VERSION ""

NS_ :

BS_:

BU_: Skylark_EV

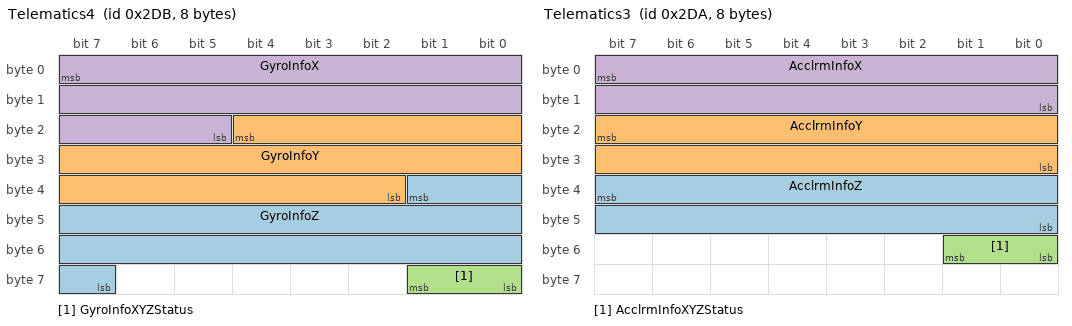
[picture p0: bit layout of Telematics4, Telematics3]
BO_ 731 Telematics4: 8 Skylark_EV
 SG_ GyroInfoZ : 33|19@0- (0.01,0) [-2000|2000] "deg/s" Vector__XXX
 SG_ GyroInfoY : 20|19@0- (0.01,0) [-2000|2000] "deg/s" Vector__XXX
 SG_ GyroInfoXYZStatus : 57|2@0+ (1,0) [0|3] "" Vector__XXX
 SG_ GyroInfoX : 7|19@0- (0.01,0) [-2000|2000] "deg/s" Vector__XXX

BO_ 730 Telematics3: 8 Skylark_EV
 SG_ AcclrmInfoZ : 39|16@0- (0.01,0) [-300|300] "m/s^2" Vector__XXX
 SG_ AcclrmInfoY : 23|16@0- (0.01,0) [-300|300] "m/s^2" Vector__XXX
 SG_ AcclrmInfoXYZStatus : 49|2@0+ (1,0) [0|3] "" Vector__XXX
 SG_ AcclrmInfoX : 7|16@0- (0.01,0) [-300|300] "m/s^2" Vector__XXX

BO_ 699 IPC11: 8 Vector__XXX
 SG_ IcHuTripBInfofull : 22|17@0+ (0.1,0) [0|9999.9] "Km"  Skylark_EV
 SG_ IcHuTripAInfofull : 7|17@0+ (0.1,0) [0|9999.9] "Km"  Skylark_EV

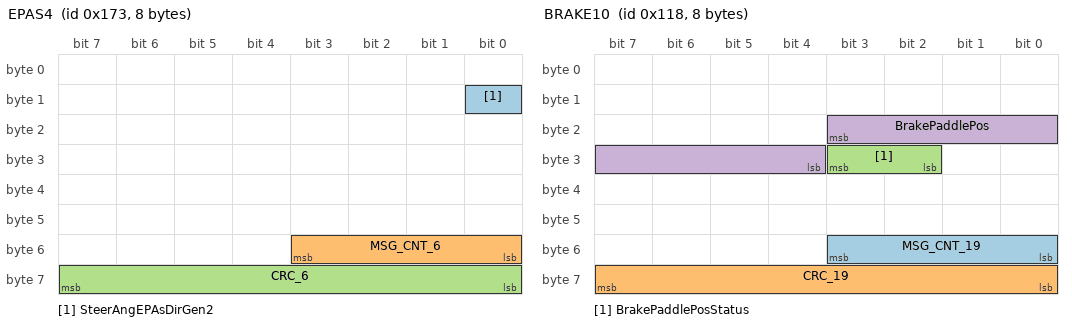
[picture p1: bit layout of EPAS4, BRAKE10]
BO_ 371 EPAS4: 8 Vector__XXX
 SG_ SteerAngEPAsDirGen2 : 8|1@0+ (1,0) [0|1] ""  Skylark_EV
 SG_ MSG_CNT_6 : 51|4@0+ (1,0) [0|15] ""  Skylark_EV
 SG_ CRC_6 : 63|8@0+ (1,0) [0|255] ""  Skylark_EV

BO_ 280 BRAKE10: 8 Vector__XXX
 SG_ MSG_CNT_19 : 51|4@0+ (1,0) [0|15] ""  Skylark_EV
 SG_ CRC_19 : 63|8@0+ (1,0) [0|255] ""  Skylark_EV
 SG_ BrakePaddlePosStatus : 27|2@0+ (1,0) [0|3] ""  Skylark_EV
 SG_ BrakePaddlePos : 19|8@0+ (0.5,0) [0|100] "%"  Skylark_EV

BO_ 703 IPC_RC1: 8 Vector__XXX
 SG_ OATICSigNewStatus : 15|2@0+ (1,0) [0|3] ""  Skylark_EV
 SG_ OATICSigNew : 7|8@0+ (0.5,-40) [-40|85] "degC"  Skylark_EV

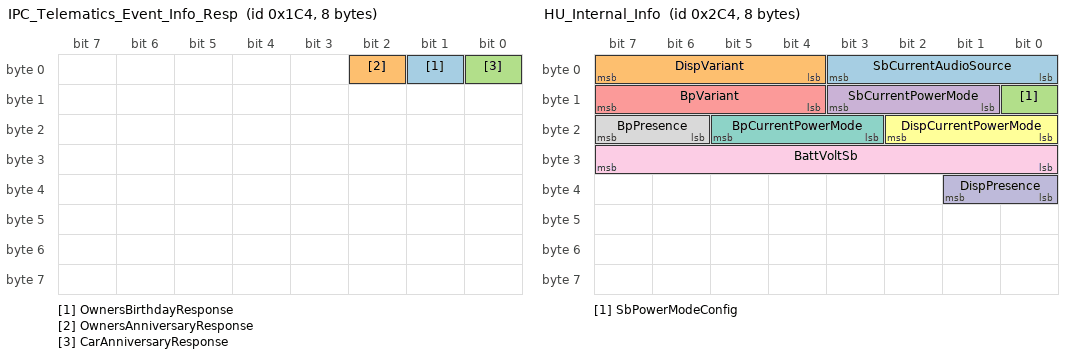
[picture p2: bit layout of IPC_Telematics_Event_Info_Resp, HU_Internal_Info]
BO_ 452 IPC_Telematics_Event_Info_Resp: 8 Vector__XXX
 SG_ OwnersBirthdayResponse : 1|1@0+ (1,0) [0|1] ""  Skylark_EV
 SG_ OwnersAnniversaryResponse : 2|1@0+ (1,0) [0|1] ""  Skylark_EV
 SG_ CarAnniversaryResponse : 0|1@0+ (1,0) [0|1] ""  Skylark_EV

BO_ 1548 VICM_DiagResponse_UUDT: 8 Vector__XXX
 SG_ VICM_DiagResponse_UUDT : 7|64@0+ (1,0) [0|0] ""  Skylark_EV

BO_ 1804 VICM_DiagResponse_USDT: 8 Vector__XXX
 SG_ VICM_DiagResponse_USDT : 7|64@0+ (1,0) [0|0] ""  Skylark_EV

BO_ 1796 VICM_DiagRequest: 8 Skylark_EV
 SG_ VICM_DiagRequest : 7|64@0+ (1,0) [0|0] "" Vector__XXX

BO_ 1771 VCU_DiagResponse_UUDT: 8 Vector__XXX
 SG_ VCU_DiagResponse_UUDT : 7|64@0+ (1,0) [0|0] ""  Skylark_EV

BO_ 2027 VCU_DiagResponse_USDT: 8 Vector__XXX
 SG_ VCU_DiagResponse_USDT : 7|64@0+ (1,0) [0|0] ""  Skylark_EV

BO_ 1763 VCU_DiagRequest_UUDT: 8 Skylark_EV
 SG_ VCU_DiagRequest_UUDT : 7|64@0+ (1,0) [0|0] "" Vector__XXX

BO_ 2019 VCU_DiagRequest_USDT: 8 Skylark_EV
 SG_ VCU_DiagRequest_USDT : 7|64@0+ (1,0) [0|0] "" Vector__XXX

BO_ 1849 WPC_DiagResponse_USDT: 8 Vector__XXX
 SG_ WPC_DiagResponse_USDT : 7|64@0+ (1,0) [0|0] ""  Skylark_EV

BO_ 1841 WPC_DiagRequest: 8 Skylark_EV
 SG_ WPC_DiagRequest : 7|64@0+ (1,0) [0|0] "" Vector__XXX

BO_ 1630 TPMS_DiagResponse_UUDT: 8 Vector__XXX
 SG_ TPMS_DiagResponse_UUDT : 7|64@0+ (1,0) [0|0] ""  Skylark_EV

BO_ 1886 TPMS_DiagResponse_USDT: 8 Vector__XXX
 SG_ TPMS_DiagResponse_USDT : 7|64@0+ (1,0) [0|0] ""  Skylark_EV

BO_ 1878 TPMS_DiagRequest: 8 Skylark_EV
 SG_ TPMS_DiagRequest : 7|64@0+ (1,0) [0|0] "" Vector__XXX

BO_ 1546 SRS_DiagResponse_UUDT: 8 Vector__XXX
 SG_ SRS_DiagResponse_UUDT : 7|64@0+ (1,0) [0|0] ""  Skylark_EV

BO_ 1802 SRS_DiagResponse_USDT: 8 Vector__XXX
 SG_ SRS_DiagResponse_USDT : 7|64@0+ (1,0) [0|0] ""  Skylark_EV

BO_ 1794 SRS_DiagRequest: 8 Skylark_EV
 SG_ SRS_DiagRequest : 7|64@0+ (1,0) [0|0] "" Vector__XXX

BO_ 1610 SRR_DiagResponse_UUDT: 8 Vector__XXX
 SG_ SRR_DiagResponse_UUDT : 7|64@0+ (1,0) [0|0] ""  Skylark_EV

BO_ 1866 SRR_DiagResponse_USDT: 8 Vector__XXX
 SG_ SRR_DiagResponse_USDT : 7|64@0+ (1,0) [0|0] ""  Skylark_EV

BO_ 1858 SRR_DiagRequest: 8 Skylark_EV
 SG_ SRR_DiagRequest : 7|64@0+ (1,0) [0|0] "" Vector__XXX

BO_ 1560 PEPS_DiagResponse_UUDT: 8 Vector__XXX
 SG_ PEPS_DiagResponse_UUDT : 7|64@0+ (1,0) [0|0] ""  Skylark_EV

BO_ 1816 PEPS_DiagResponse_USDT: 8 Vector__XXX
 SG_ PEPS_DiagResponse_USDT : 7|64@0+ (1,0) [0|0] ""  Skylark_EV

BO_ 1808 PEPS_DiagRequest_USDT: 8 Skylark_EV
 SG_ PEPS_DiagRequest_USDT : 7|64@0+ (1,0) [0|0] "" Vector__XXX

BO_ 1564 PDC_DiagResponse_UUDT: 8 Vector__XXX
 SG_ PDC_DiagResponse_UUDT : 7|64@0+ (1,0) [0|0] ""  Skylark_EV

BO_ 1820 PDC_DiagResponse_USDT: 8 Vector__XXX
 SG_ PDC_DiagResponse_USDT : 7|64@0+ (1,0) [0|0] ""  Skylark_EV

BO_ 1812 PDC_DiagRequest: 8 Skylark_EV
 SG_ PDC_DiagRequest : 7|64@0+ (1,0) [0|0] "" Vector__XXX

BO_ 1608 FR_DiagResponse_UUDT: 8 Vector__XXX
 SG_ FR_DiagResponse_UUDT : 7|64@0+ (1,0) [0|0] ""  Skylark_EV

BO_ 1864 FR_DiagResponse_USDT: 8 Vector__XXX
 SG_ FR_DiagResponse_USDT : 7|64@0+ (1,0) [0|0] ""  Skylark_EV

BO_ 1856 FR_DiagRequest: 8 Skylark_EV
 SG_ FR_DiagRequest : 7|64@0+ (1,0) [0|0] "" Vector__XXX

BO_ 1609 FCM_DiagResponse_UUDT: 8 Vector__XXX
 SG_ FCM_DiagResponse_UUDT : 7|64@0+ (1,0) [0|0] ""  Skylark_EV

BO_ 1865 FCM_DiagResponse_USDT: 8 Vector__XXX
 SG_ FCM_DiagResponse_USDT : 7|64@0+ (1,0) [0|0] ""  Skylark_EV

BO_ 1857 FCM_DiagRequest: 8 Skylark_EV
 SG_ FCM_DiagRequest : 7|64@0+ (1,0) [0|0] "" Vector__XXX

BO_ 1624 ESP_DiagResponse_UUDT: 8 Vector__XXX
 SG_ ESP_DiagResponse_UUDT : 7|64@0+ (1,0) [0|0] ""  Skylark_EV

BO_ 1880 ESP_DiagResponse_USDT: 8 Vector__XXX
 SG_ ESP_DiagResponse_USDT : 7|64@0+ (1,0) [0|0] ""  Skylark_EV

BO_ 1872 ESP_DiagRequest: 8 Skylark_EV
 SG_ ESP_DiagRequest : 7|64@0+ (1,0) [0|0] "" Vector__XXX

BO_ 1884 ESCL_DiagResponse_USDT: 8 Vector__XXX
 SG_ ESCL_DiagResponse_USDT : 7|64@0+ (1,0) [0|0] ""  Skylark_EV

BO_ 1876 ESCL_DiagRequest: 8 Skylark_EV
 SG_ ESCL_DiagRequest : 7|64@0+ (1,0) [0|0] "" Vector__XXX

BO_ 1626 EPAS_DiagResponse_UUDT: 8 Vector__XXX
 SG_ EPAS_DiagResponse_UUDT : 7|64@0+ (1,0) [0|0] ""  Skylark_EV

BO_ 1882 EPAS_DiagResponse_USDT: 8 Vector__XXX
 SG_ EPAS_DiagResponse_USDT : 7|64@0+ (1,0) [0|0] ""  Skylark_EV

BO_ 1874 EPAS_DiagRequest: 8 Skylark_EV
 SG_ EPAS_DiagRequest : 7|64@0+ (1,0) [0|0] "" Vector__XXX

BO_ 1549 CCM_DiagResponse_UUDT: 8 Vector__XXX
 SG_ CCM_DiagResponse_UUDT : 7|64@0+ (1,0) [0|0] ""  Skylark_EV

BO_ 1805 CCM_DiagResponse_USDT: 8 Vector__XXX
 SG_ CCM_DiagResponse_USDT : 7|64@0+ (1,0) [0|0] ""  Skylark_EV

BO_ 1797 CCM_DiagRequest: 8 Skylark_EV
 SG_ CCM_DiagRequest : 7|64@0+ (1,0) [0|0] "" Vector__XXX

BO_ 1545 BCM_DiagResponse_UUDT: 8 Vector__XXX
 SG_ BCM_DiagResponse_UUDT : 7|64@0+ (1,0) [0|0] ""  Skylark_EV

BO_ 1801 BCM_DiagResponse_USDT: 8 Vector__XXX
 SG_ BCM_DiagResponse_USDT : 7|64@0+ (1,0) [0|0] ""  Skylark_EV

BO_ 1793 BCM_DiagRequest: 8 Skylark_EV
 SG_ BCM_DiagRequest : 7|64@0+ (1,0) [0|0] "" Vector__XXX

BO_ 708 HU_Internal_Info: 8 Skylark_EV
 SG_ SbCurrentAudioSource : 3|4@0+ (1,0) [0|15] "" Vector__XXX
 SG_ DispVariant : 7|4@0+ (1,0) [0|15] "" Vector__XXX
 SG_ SbPowerModeConfig : 8|1@0+ (1,0) [0|1] "" Vector__XXX
 SG_ SbCurrentPowerMode : 11|3@0+ (1,0) [0|7] "" Vector__XXX
 SG_ BpVariant : 15|4@0+ (1,0) [0|15] "" Vector__XXX
 SG_ DispCurrentPowerMode : 18|3@0+ (1,0) [0|7] "" Vector__XXX
 SG_ BpCurrentPowerMode : 21|3@0+ (1,0) [0|7] "" Vector__XXX
 SG_ BpPresence : 23|2@0+ (1,0) [0|3] "" Vector__XXX
 SG_ BattVoltSb : 31|8@0+ (0.1,0) [0|25.4] "V" Vector__XXX
 SG_ DispPresence : 33|2@0+ (1,0) [0|3] "" Vector__XXX

BO_ 1109 AVAS_Event2: 8 Vector__XXX
 SG_ AvasOnOffSettingState : 7|1@0+ (1,0) [0|1] ""  Skylark_EV
 SG_ AvasOnOffSettingPresence : 6|2@0+ (1,0) [0|3] ""  Skylark_EV

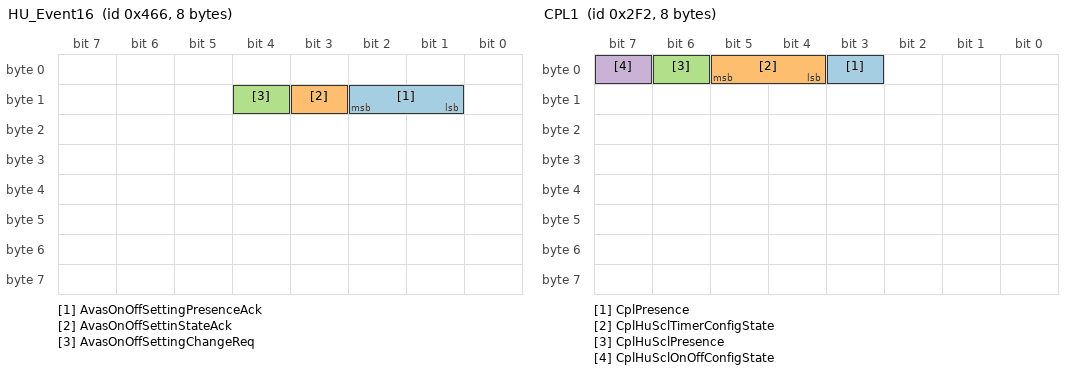
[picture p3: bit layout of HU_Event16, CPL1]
BO_ 1126 HU_Event16: 8 Skylark_EV
 SG_ AvasOnOffSettingPresenceAck : 10|2@0+ (1,0) [0|3] "" Vector__XXX
 SG_ AvasOnOffSettinStateAck : 11|1@0+ (1,0) [0|1] "" Vector__XXX
 SG_ AvasOnOffSettingChangeReq : 12|1@0+ (1,0) [0|1] "" Vector__XXX

BO_ 945 BCM5: 8 Vector__XXX
 SG_ VehicleKeyType : 7|5@0+ (1,0) [0|31] ""  Skylark_EV

BO_ 535 CPL_Event1: 8 Vector__XXX
 SG_ CplHuSclSettingUpdateAck : 1|2@0+ (1,0) [0|3] ""  Skylark_EV

BO_ 754 CPL1: 8 Vector__XXX
 SG_ CplPresence : 3|1@0+ (1,0) [0|1] ""  Skylark_EV
 SG_ CplHuSclTimerConfigState : 5|2@0+ (1,0) [0|3] ""  Skylark_EV
 SG_ CplHuSclPresence : 6|1@0+ (1,0) [0|1] ""  Skylark_EV
 SG_ CplHuSclOnOffConfigState : 7|1@0+ (1,0) [0|1] ""  Skylark_EV

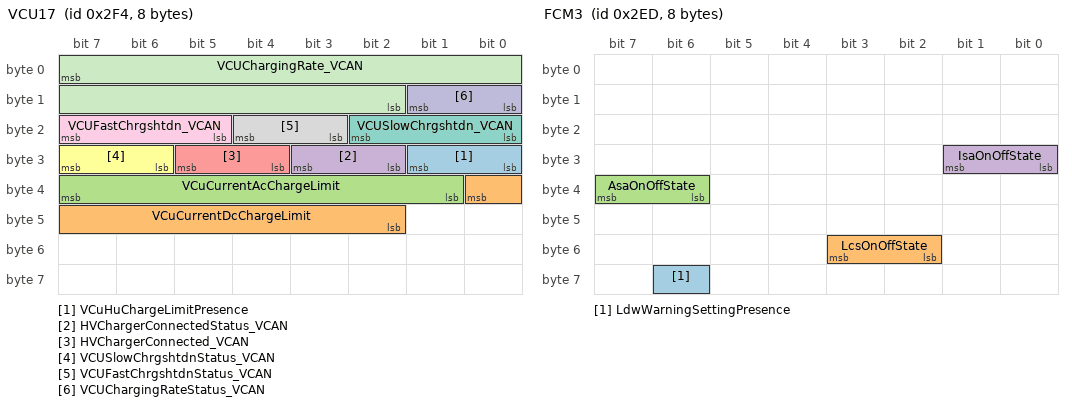
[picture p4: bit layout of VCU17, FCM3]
BO_ 756 VCU17: 8 Vector__XXX
 SG_ VCuHuChargeLimitPresence : 25|2@0+ (1,0) [0|3] ""  Skylark_EV
 SG_ VCuCurrentDcChargeLimit : 32|7@0+ (1,0) [0|100] ""  Skylark_EV
 SG_ VCuCurrentAcChargeLimit : 39|7@0+ (1,0) [0|100] ""  Skylark_EV
 SG_ HVChargerConnectedStatus_VCAN : 27|2@0+ (1,0) [0|3] ""  Skylark_EV
 SG_ HVChargerConnected_VCAN : 29|2@0+ (1,0) [0|3] ""  Skylark_EV
 SG_ VCUSlowChrgshtdnStatus_VCAN : 31|2@0+ (1,0) [0|3] ""  Skylark_EV
 SG_ VCUSlowChrgshtdn_VCAN : 18|3@0+ (1,0) [0|7] ""  Skylark_EV
 SG_ VCUFastChrgshtdnStatus_VCAN : 20|2@0+ (1,0) [0|3] ""  Skylark_EV
 SG_ VCUFastChrgshtdn_VCAN : 23|3@0+ (1,0) [0|7] ""  Skylark_EV
 SG_ VCUChargingRateStatus_VCAN : 9|2@0+ (1,0) [0|3] ""  Skylark_EV
 SG_ VCUChargingRate_VCAN : 7|14@0+ (0.01,0) [0|163.84] "Kwh"  Skylark_EV

BO_ 753 HUD1: 8 Vector__XXX
 SG_ HudPresence : 7|2@0+ (1,0) [0|3] ""  Skylark_EV
 SG_ HudFeaturePresence : 5|1@0+ (1,0) [0|1] ""  Skylark_EV

BO_ 382 VCU15: 8 Vector__XXX
 SG_ VCUGSAPositionDisplay : 23|16@0+ (1,0) [0|65535] ""  Skylark_EV

BO_ 529 VCU_Event1: 8 Vector__XXX
 SG_ VCuHuChargeLimitValueAck : 13|2@0+ (1,0) [0|3] ""  Skylark_EV
 SG_ DischargingSOCLimitAck : 15|2@0+ (1,0) [0|3] ""  Skylark_EV

BO_ 528 HU_Event4: 8 Skylark_EV
 SG_ DischargeSOClimitcmd : 60|2@0+ (1,0) [0|3] "" Vector__XXX
 SG_ DischargeSOClimit : 51|7@0+ (1,0) [30|100] "%" Vector__XXX
 SG_ AVAsFeaturePreviewReq : 47|6@0+ (1,0) [0|63] "" Vector__XXX
 SG_ SoundSigSettingStateAck : 25|6@0+ (1,0) [0|63] "" Vector__XXX
 SG_ SoundSigSettingPresenceAck : 31|6@0+ (1,0) [0|63] "" Vector__XXX
 SG_ ChargingSettingChangeReq : 12|1@0+ (1,0) [0|1] "" Vector__XXX
 SG_ V2XSoundSettingStateAck : 33|1@0+ (1,0) [0|1] "" Vector__XXX
 SG_ V2XSettingChangeReq : 32|1@0+ (1,0) [0|1] "" Vector__XXX
 SG_ V2XEventPresenceAck : 35|2@0+ (1,0) [0|3] "" Vector__XXX
 SG_ SndSyncDriveModeChangeReq : 40|1@0+ (1,0) [0|1] "" Vector__XXX
 SG_ SoundSigSettingChangeReq : 21|6@0+ (1,0) [0|63] "" Vector__XXX
 SG_ CrankSettingChangeReq : 8|1@0+ (1,0) [0|1] "" Vector__XXX
 SG_ LockUnlockSettingChangeReq : 0|1@0+ (1,0) [0|1] "" Vector__XXX
 SG_ ActiveExtSettingChangeReq : 4|1@0+ (1,0) [0|1] "" Vector__XXX
 SG_ HuAVAsReqType : 55|4@0+ (1,0) [0|15] "" Vector__XXX
 SG_ SndSyncDriveModePresenceAck : 23|2@0+ (1,0) [0|3] "" Vector__XXX
 SG_ SndSyncDriveModeSettingStateAck : 41|1@0+ (1,0) [0|1] "" Vector__XXX
 SG_ CrankSoundSettingStateAck : 9|1@0+ (1,0) [0|1] "" Vector__XXX
 SG_ CrankEventPresenceAck : 11|2@0+ (1,0) [0|3] "" Vector__XXX
 SG_ ChargingSoundSettingStateAck : 13|1@0+ (1,0) [0|1] "" Vector__XXX
 SG_ ChargingEventPresenceAck : 15|2@0+ (1,0) [0|3] "" Vector__XXX
 SG_ LockUnlockSettingStateAck : 1|1@0+ (1,0) [0|1] "" Vector__XXX
 SG_ LockUnlockEventPresenceAck : 3|2@0+ (1,0) [0|3] "" Vector__XXX
 SG_ ActiveExtSoundSettingStateAck : 5|1@0+ (1,0) [0|1] "" Vector__XXX
 SG_ ActiveExtSoundPresenceAck : 7|2@0+ (1,0) [0|3] "" Vector__XXX

BO_ 527 AVAS_Event1: 8 Vector__XXX
 SG_ V2XSoundSettingState : 34|1@0+ (1,0) [0|1] ""  Skylark_EV
 SG_ V2XEventPresence : 33|2@0+ (1,0) [0|3] ""  Skylark_EV
 SG_ SoundSignSettingState : 27|6@0+ (1,0) [0|63] ""  Skylark_EV
 SG_ SoundSignSettingPresence : 17|6@0+ (1,0) [0|63] ""  Skylark_EV
 SG_ SndSyncDriveModeSettingState : 18|1@0+ (1,0) [0|1] ""  Skylark_EV
 SG_ SndSyncDriveModePresence : 20|2@0+ (1,0) [0|3] ""  Skylark_EV
 SG_ LockUnlockSettingState : 35|1@0+ (1,0) [0|1] ""  Skylark_EV
 SG_ LockUnlockEventPresence : 37|2@0+ (1,0) [0|3] ""  Skylark_EV
 SG_ CrankSoundSettingState : 21|1@0+ (1,0) [0|1] ""  Skylark_EV
 SG_ CrankEventPresence : 23|2@0+ (1,0) [0|3] ""  Skylark_EV
 SG_ ChargingSoundSettingState : 8|1@0+ (1,0) [0|1] ""  Skylark_EV
 SG_ ChargingEventPresence : 10|2@0+ (1,0) [0|3] ""  Skylark_EV
 SG_ AVAsPreviewStateapplicability : 0|6@0+ (1,0) [0|63] ""  Skylark_EV
 SG_ AVAsPreviewState : 2|2@0+ (1,0) [0|3] ""  Skylark_EV
 SG_ AVAsPreviewPresence : 4|2@0+ (1,0) [0|3] ""  Skylark_EV
 SG_ ActiveExtSoundSettingState : 5|1@0+ (1,0) [0|1] ""  Skylark_EV
 SG_ ActiveExtSoundPresence : 7|2@0+ (1,0) [0|3] ""  Skylark_EV

BO_ 751 AVAS1: 8 Vector__XXX
 SG_ AvasPresence : 7|1@0+ (1,0) [0|1] ""  Skylark_EV
 SG_ AVAsMalFunction : 6|2@0+ (1,0) [0|3] ""  Skylark_EV

BO_ 749 FCM3: 8 Vector__XXX
 SG_ LdwWarningSettingPresence : 62|1@0+ (1,0) [0|1] ""  Skylark_EV
 SG_ LcsOnOffState : 51|2@0+ (1,0) [0|3] ""  Skylark_EV
 SG_ AsaOnOffState : 39|2@0+ (1,0) [0|3] ""  Skylark_EV
 SG_ IsaOnOffState : 25|2@0+ (1,0) [0|3] ""  Skylark_EV

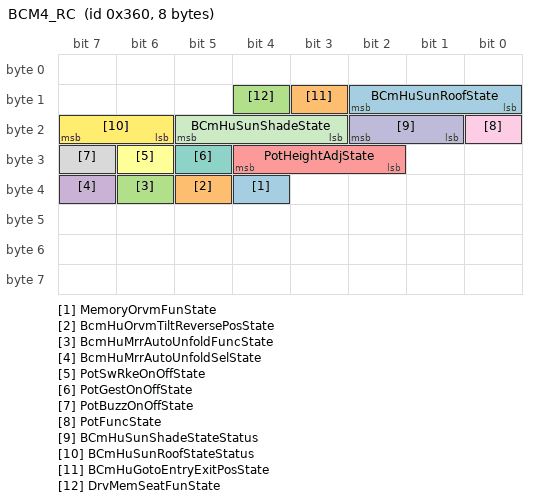
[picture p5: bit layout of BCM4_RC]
BO_ 864 BCM4_RC: 8 Vector__XXX
 SG_ MemoryOrvmFunState : 36|1@0+ (1,0) [0|1] ""  Skylark_EV
 SG_ BcmHuOrvmTiltReversePosState : 37|1@0+ (1,0) [0|1] ""  Skylark_EV
 SG_ BcmHuMrrAutoUnfoldFuncState : 38|1@0+ (1,0) [0|1] ""  Skylark_EV
 SG_ BcmHuMrrAutoUnfoldSelState : 39|1@0+ (1,0) [0|1] ""  Skylark_EV
 SG_ PotHeightAdjState : 28|3@0+ (1,0) [0|7] ""  Skylark_EV
 SG_ PotSwRkeOnOffState : 30|1@0+ (1,0) [0|1] ""  Skylark_EV
 SG_ PotGestOnOffState : 29|1@0+ (1,0) [0|1] ""  Skylark_EV
 SG_ PotBuzzOnOffState : 31|1@0+ (1,0) [0|1] ""  Skylark_EV
 SG_ PotFuncState : 16|1@0+ (1,0) [0|1] ""  Skylark_EV
 SG_ BCmHuSunShadeStateStatus : 18|2@0+ (1,0) [0|3] ""  Skylark_EV
 SG_ BCmHuSunShadeState : 21|3@0+ (1,0) [0|7] ""  Skylark_EV
 SG_ BCmHuSunRoofStateStatus : 23|2@0+ (1,0) [0|3] ""  Skylark_EV
 SG_ BCmHuSunRoofState : 10|3@0+ (1,0) [0|7] ""  Skylark_EV
 SG_ BCmHuGotoEntryExitPosState : 11|1@0+ (1,0) [0|1] ""  Skylark_EV
 SG_ DrvMemSeatFunState : 12|1@0+ (1,0) [0|1] ""  Skylark_EV

CM_ BU_ Skylark_EV "FN file name: 'TML_HU_Gen3_Function_Net_Skylark_23Jul2025_1.8'
FN column letter: 'B'
FN column Name: 'Gen3_IVI_EV'";
CM_ SG_ 731 GyroInfoZ "Z- axis gyroscope signal value published by TCU to VCU";
CM_ SG_ 731 GyroInfoY "Y- axis gyroscope signal value published by TCU to VCU";
CM_ SG_ 731 GyroInfoXYZStatus "Gyroscope signal  Status value published by TCU";
CM_ SG_ 731 GyroInfoX "X- axis gyroscope signal value published by TCU to VCU";
CM_ SG_ 730 AcclrmInfoZ "Z-axis accelerometer signal value published by TCU to VCU";
CM_ SG_ 730 AcclrmInfoY "Y-axis accelerometer signal value published by TCU to VCU";
CM_ SG_ 730 AcclrmInfoXYZStatus "States plausibility of the signal AccelerometerInfo ";
CM_ SG_ 730 AcclrmInfoX "X-axis accelerometer signal value published by TCU to VCU";
CM_ SG_ 699 IcHuTripBInfofull "This signal indicates Trip B info";
CM_ SG_ 699 IcHuTripAInfofull "This signal indicates Trip A info";
CM_ BO_ 371 "Frame to be enabled through DID for ADAS. ";
CM_ SG_ 371 SteerAngEPAsDirGen2 "Steering wheel angle direction";
CM_ SG_ 371 MSG_CNT_6 "MRC for entire message which consists of SteerAngEPAS, SteerAngEPAsDir, SteerAngEPASStatus";
CM_ SG_ 371 CRC_6 "CRC for entire message which consists of SteerAngEPAS, SteerAngEPAsDir, SteerAngEPASStatus";
CM_ SG_ 280 MSG_CNT_19 "Rolling counter for the entire Tx message";
CM_ SG_ 280 CRC_19 "CRC signal";
CM_ SG_ 280 BrakePaddlePosStatus "status information of Brake paddle percentage signal";
CM_ SG_ 280 BrakePaddlePos "Brake paddle travel percentage shall be Transmissted  by iVBAC";
CM_ SG_ 703 OATICSigNewStatus "Signal represents Status of OATSig";
CM_ SG_ 703 OATICSigNew "Signal represents Outside Ambient Temperature raw value evaluated by Instrument Cluster 
";
CM_ SG_ 452 OwnersBirthdayResponse "It's the response from IPC to TCU for HappyBirthday display";
CM_ SG_ 452 OwnersAnniversaryResponse "It's the response from IPC to TCU for HappyAnniversary display";
CM_ SG_ 452 CarAnniversaryResponse "It's the response from IPC to TCU for CarAnniversary display";
CM_ BO_ 1630 "Diag UUDT Response";
CM_ BO_ 1886 "USDT Diag Response";
CM_ BO_ 1878 "Diag Request";
CM_ SG_ 1878 TPMS_DiagRequest "Diag Request Signal";
CM_ SG_ 708 SbCurrentAudioSource "Silver Box shall published its current audio source";
CM_ SG_ 708 DispVariant "HU shall publish its variant type to all partner ECUs.";
CM_ SG_ 708 SbPowerModeConfig "Silver Box shall published its current power mode configuration";
CM_ SG_ 708 SbCurrentPowerMode "Silver Box shall published its current operating power mode";
CM_ SG_ 708 BpVariant "HU shall publish its variant type to all partner ECUs.";
CM_ SG_ 708 DispCurrentPowerMode "Silver Box shall published display current operating power mode";
CM_ SG_ 708 BpCurrentPowerMode "Silver Box shall published button panel current operating power mode";
CM_ SG_ 708 BpPresence "HU shall publish its presence to all partner ECUs.";
CM_ SG_ 708 BattVoltSb "Silver Box Battery Voltage";
CM_ SG_ 708 DispPresence "HU shall publish its presence to all partner ECUs.";
CM_ SG_ 1109 AvasOnOffSettingState "This signal indicates the current setting state stored in AVAS ECU for AVAS ON/OFF setting state";
CM_ SG_ 1109 AvasOnOffSettingPresence "This signal indicates AVAS ON/OFF setting feature presence";
CM_ SG_ 1126 AvasOnOffSettingPresenceAck "AVAS ON/OFF setting feature presence acknowledgement";
CM_ SG_ 1126 AvasOnOffSettinStateAck "This signal indicates the current setting state stored in AVAS ECU for AVAS ON/OFF setting state acknowledgement";
CM_ SG_ 1126 AvasOnOffSettingChangeReq "This signal indicates the user setting request from HU for AVAS ON/OFF setting";
CM_ SG_ 945 VehicleKeyType "BCM publish the Vehicle Key type Information on CAN";
CM_ SG_ 535 CplHuSclSettingUpdateAck "This signal indicates setting update acknowledgement information for SCL feature.";
CM_ SG_ 754 CplPresence "This signal indicates the presence of CPL.";
CM_ SG_ 754 CplHuSclTimerConfigState "This signal indicates current timer setting state of SCL feature.";
CM_ SG_ 754 CplHuSclPresence "This signal indicates the presence of SCL feature from CPL.";
CM_ SG_ 754 CplHuSclOnOffConfigState "This signal indicates current On/Off setting state of SCL feature.";
CM_ SG_ 756 VCuHuChargeLimitPresence "VCuHuChargeLimitPresence";
CM_ SG_ 756 VCuCurrentDcChargeLimit "VCuCurrentDcChargeLimit
";
CM_ SG_ 756 VCuCurrentAcChargeLimit "VCu Current Ac Charge Limit";
CM_ SG_ 756 HVChargerConnectedStatus_VCAN "This information is used to determine the HV Battery Charger Connected Lamp Status";
CM_ SG_ 756 HVChargerConnected_VCAN "HV battery Charger connected lamp";
CM_ SG_ 756 VCUSlowChrgshtdnStatus_VCAN "Indicates the Slow charging shutdown reason status";
CM_ SG_ 756 VCUSlowChrgshtdn_VCAN "Slow charging shutdown reason";
CM_ SG_ 756 VCUFastChrgshtdnStatus_VCAN "Indicates the Fast charging shutdown reason status";
CM_ SG_ 756 VCUFastChrgshtdn_VCAN "Fast charging shutdown reason";
CM_ SG_ 756 VCUChargingRateStatus_VCAN "Indicates the status of charging rate";
CM_ SG_ 756 VCUChargingRate_VCAN "Charging rate in Kwh";
CM_ SG_ 753 HudPresence "HUD shall publish its presence to all partner ECUs.";
CM_ SG_ 753 HudFeaturePresence "HUD shall publish its feature presence to HU to show HMI setting.";
CM_ SG_ 382 VCUGSAPositionDisplay "Refer FN/FD for bit-mapped signals";
CM_ SG_ 529 DischargingSOCLimitAck "Indicates the discharge limit command response/acknowledgement from VCU";
CM_ SG_ 528 DischargeSOClimitcmd "Indicates the discharge limit set or discharge limit reset request status from IVI";
CM_ SG_ 528 DischargeSOClimit "Set limit band from IVI";
CM_ SG_ 528 AVAsFeaturePreviewReq "This signal indicates user setting request from HU for preview of AVAS Sounds";
CM_ SG_ 528 SoundSigSettingStateAck "This signal indicates the current setting state stored in AVAS ECU for Sound Signature acknowledgement";
CM_ SG_ 528 SoundSigSettingPresenceAck "This signal indicates the No. of sound signatures present in vehicle acknowledgement";
CM_ SG_ 528 ChargingSettingChangeReq "This signal indicates the user setting request from HU for Charging Sound";
CM_ SG_ 528 V2XSoundSettingStateAck "This signal indicates the current setting state stored in AVAS ECU for V2X sound acknowledgement";
CM_ SG_ 528 V2XSettingChangeReq "This signal indicates the user setting request from HU for V2X Sound";
CM_ SG_ 528 V2XEventPresenceAck "This signal indicates V2X Event Sound feature presence acknowledgement";
CM_ SG_ 528 SndSyncDriveModeChangeReq "This signal indicates user setting request from HU for sound signature in sync with drive mode";
CM_ SG_ 528 SoundSigSettingChangeReq "This signal indicates the user setting request from HU for Sound Signature Change";
CM_ SG_ 528 CrankSettingChangeReq "This signal indicates the user setting request from HU for Crank Sound";
CM_ SG_ 528 LockUnlockSettingChangeReq "This signal indicates the user setting request from HU for Lock Unlock Sound";
CM_ SG_ 528 ActiveExtSettingChangeReq "This signal indicates the user setting request from HU for active external sound";
CM_ SG_ 528 HuAVAsReqType "This signal indicates the request for an action that HU wants AVAS to perform for active external sound ";
CM_ SG_ 528 SndSyncDriveModePresenceAck "This signal indicates Sound sync with Drive mode feature presence acknowledgement";
CM_ SG_ 528 SndSyncDriveModeSettingStateAck "This signal indicates the current setting state stored in AVAS ECU for Sound Sync with Drive Modes ";
CM_ SG_ 528 CrankSoundSettingStateAck "This signal indicates the current setting state stored in AVAS ECU for Crank sound acknowledgement";
CM_ SG_ 528 CrankEventPresenceAck "This signal indicates Crank Event sound feature presence acknowledgement";
CM_ SG_ 528 ChargingSoundSettingStateAck "This signal indicates the current setting state stored in AVAS ECU for Charging sound acknowledgement";
CM_ SG_ 528 ChargingEventPresenceAck "This signal indicates Charging Event Sound feature presence acknowledgement";
CM_ SG_ 528 LockUnlockSettingStateAck "This signal indicates the current setting state stored in AVAS ECU for Lock Unlock sound acknowledgement";
CM_ SG_ 528 LockUnlockEventPresenceAck "This signal indicates Lock Unlock event sound feature presence acknowledgement";
CM_ SG_ 528 ActiveExtSoundSettingStateAck "This signal indicates the current setting state stored in AVAS ECU for active external sound acknowledgement";
CM_ SG_ 528 ActiveExtSoundPresenceAck "This signal indicates active external sound feature presence acknowledgement";
CM_ SG_ 527 V2XSoundSettingState "This signal indicates the current setting state stored in AVAS ECU for V2X sound";
CM_ SG_ 527 V2XEventPresence "This signal indicates V2X Event Sound feature presence";
CM_ SG_ 527 SoundSignSettingState "This signal indicates the current setting state stored in AVAS ECU for Sound Signature";
CM_ SG_ 527 SoundSignSettingPresence "This signal indicates the No. of sound signatures present in vehicle";
CM_ SG_ 527 SndSyncDriveModeSettingState "This signal indicates the current setting state stored in AVAS ECU for Sound Sync with Drive Modes";
CM_ SG_ 527 SndSyncDriveModePresence "This signal indicates Sound sync with Drive mode feature presence";
CM_ SG_ 527 LockUnlockSettingState "This signal indicates the current setting state stored in AVAS ECU for Lock Unlock sound";
CM_ SG_ 527 LockUnlockEventPresence "This signal indicates Lock Unlock event sound feature presence";
CM_ SG_ 527 CrankSoundSettingState "This signal indicates the current setting state stored in AVAS ECU for Crank sound";
CM_ SG_ 527 CrankEventPresence "This signal indicates Crank Event sound feature presence";
CM_ SG_ 527 ChargingSoundSettingState "This signal indicates the current setting state stored in AVAS ECU for Charging sound";
CM_ SG_ 527 ChargingEventPresence "This signal indicates Charging Event Sound feature presence";
CM_ SG_ 527 AVAsPreviewStateapplicability "This signal indicates the feature for which AVAsPreviewState is applicable";
CM_ SG_ 527 AVAsPreviewState "This signal indicates the preview state of AVAS ECU";
CM_ SG_ 527 AVAsPreviewPresence "This signal indicates the presence of preview feature";
CM_ SG_ 527 ActiveExtSoundSettingState "This signal indicates the current setting state stored in AVAS ECU for active external sound";
CM_ SG_ 527 ActiveExtSoundPresence "This signal indicates active external sound feature presence";
CM_ SG_ 751 AvasPresence "This signal indicates the presence of AVAS ECU";
CM_ SG_ 751 AVAsMalFunction "This signal indicates the malfunction information of AVAS";
CM_ SG_ 749 LdwWarningSettingPresence "This signal indicates the presence of LDW warning settings



";
CM_ SG_ 749 LcsOnOffState "It indicates the LCS feature's On/Off State





";
CM_ SG_ 749 AsaOnOffState "It indicates the ASA feature's On/Off State





";
CM_ SG_ 749 IsaOnOffState "It indicates the ISA feature's ON/OFF state





";
CM_ SG_ 864 MemoryOrvmFunState "This signal informs whether Memory ORVM Function present or Not";
CM_ SG_ 864 BcmHuOrvmTiltReversePosState "ORVM Tilt in reverse function Enable or Disable current State";
CM_ SG_ 864 BcmHuMrrAutoUnfoldFuncState "ORVM Auto Unfold feature present/Absent on vehicle data from BCM to HU for auto-learning";
CM_ SG_ 864 BcmHuMrrAutoUnfoldSelState "ORVM Auto Unfold function user selection Current state data from BCM to HU";
CM_ SG_ 864 PotHeightAdjState "Easy Entry/Exit function Enable or Disable current State to HU";
CM_ SG_ 864 PotSwRkeOnOffState "POT open/close by RKE switch enable/ disable user req state from BCM to HU";
CM_ SG_ 864 PotGestOnOffState "POT open/close by gesture enable/ disable user req state from BCM to HU";
CM_ SG_ 864 PotBuzzOnOffState "POT buzzer of open/close action enable/ disable user req state from BCM to HU";
CM_ SG_ 864 PotFuncState "This signal informs the whether POT function present or not in Vehicle";
CM_ SG_ 864 BCmHuSunShadeStateStatus "status of BCmHuSunShadeState";
CM_ SG_ 864 BCmHuSunShadeState "SunShade state from BCM to HU";
CM_ SG_ 864 BCmHuSunRoofStateStatus "status of BCmHuSunRoofState";
CM_ SG_ 864 BCmHuSunRoofState "Sunroof state from BCM to HU";
CM_ SG_ 864 BCmHuGotoEntryExitPosState "Easy Entry/Exit function Enable or Disable current State to HU";
CM_ SG_ 864 DrvMemSeatFunState "This signal informs the whether memory driver seat function present or not ";
BA_DEF_ SG_  "Remarks" STRING ;
BA_DEF_ SG_  "NWM_WakeupAllowed" ENUM  "No","Yes";
BA_DEF_ SG_  "GenSigTimeoutTime_HU_Mid_X451" INT 0 65535;
BA_DEF_ SG_  "GenSigTimeoutTime_HU_High_X451" INT 0 65535;
BA_DEF_ SG_  "GenSigTimeoutTime_HU_B" INT 0 65535;
BA_DEF_ SG_  "GenSigTimeoutTime_HU_A" INT 0 65535;
BA_DEF_ SG_  "GenSigTimeoutTime_BCM_Mid" INT 0 65535;
BA_DEF_ SG_  "GenSigTimeoutMsg_HU_Mid_X451" INT 0 65535;
BA_DEF_ SG_  "GenSigTimeoutMsg_HU_High_X451" INT 0 65535;
BA_DEF_ SG_  "GenSigTimeoutMsg_HU_B" INT 0 65535;
BA_DEF_ SG_  "GenSigTimeoutMsg_HU_A" INT 0 65535;
BA_DEF_ SG_  "GenSigStartValue" INT 0 0;
BA_DEF_ SG_  "GenSigSendType" ENUM  "Cyclic","OnWrite","OnWriteWithRepetition","OnChange","OnChangeWithRepetition","IfActive","IfActiveWithRepetition","NoSigSendType","NotUsed","NotUsed","NotUsed","NotUsed","NotUsed";
BA_DEF_ SG_  "GenSigInactiveValue" INT 0 0;
BA_DEF_ SG_  "GenSigEnvVarType" ENUM  "int","float","undef";
BA_DEF_ SG_  "GenSigCycleTimeActive" INT 0 0;
BA_DEF_ SG_  "GenSigCycleTime" INT 0 0;
BA_DEF_ SG_  "GenSigTimeoutMsg_HU_High_X445" INT 0 65535;
BA_DEF_ SG_  "GenSigTimeoutMsg_HU_Mid_X445" INT 0 65535;
BA_DEF_ SG_  "GenSigTimeoutTime_HU_High_X445" INT 0 65535;
BA_DEF_ SG_  "GenSigTimeoutTime_HU_Mid_X445" INT 0 65535;
BA_DEF_ SG_  "GenSigTimeoutMsg_IVI" INT 0 65535;
BA_DEF_ SG_  "GenSigTimeoutTime_IVI" INT 0 65535;
BA_DEF_ BO_  "NmMessage" ENUM  "no","yes";
BA_DEF_ BO_  "NmAsrMessage" ENUM  "<n.a.>","No","Yes";
BA_DEF_ BO_  "MessageTimeout" INT 0 65535;
BA_DEF_ BO_  "GenMsgStartDelayTime" INT 0 0;
BA_DEF_ BO_  "GenMsgSendType" ENUM  "Cyclic","NotUsed","NotUsed","NotUsed","NotUsed","NotUsed","NotUsed","IfActive","NoMsgSendType","NotUsed";
BA_DEF_ BO_  "GenMsgNrOfRepetition" INT 0 0;
BA_DEF_ BO_  "GenMsgILSupport" ENUM  "No","Yes";
BA_DEF_ BO_  "GenMsgDelayTime" INT 0 0;
BA_DEF_ BO_  "GenMsgCycleTimeFast" INT 0 0;
BA_DEF_ BO_  "GenMsgCycleTime" INT 0 0;
BA_DEF_ BO_  "DiagUudtResponse" ENUM  "false","true";
BA_DEF_ BO_  "DiagUsdtResponse" ENUM  "false","true";
BA_DEF_ BO_  "DiagState" ENUM  "No","Yes";
BA_DEF_ BO_  "DiagResponse" ENUM  "No","Yes";
BA_DEF_ BO_  "DiagRequest" ENUM  "No","Yes";
BA_DEF_ BO_  "MsgType" ENUM  "Application","NM","NMH";
BA_DEF_ BU_  "NodeLayerModules" STRING ;
BA_DEF_ BU_  "NmStationAddress" INT 0 63;
BA_DEF_ BU_  "NmCAN" INT 1 3;
BA_DEF_ BU_  "NmAsrNodeIdentifier" HEX 0 255;
BA_DEF_ BU_  "NmAsrNode" ENUM  "<n.a.>","No","Yes";
BA_DEF_ BU_  "NmAsrCanMsgReducedTime" INT 1 65535;
BA_DEF_ BU_  "ECU" STRING ;
BA_DEF_  "NmType" STRING ;
BA_DEF_  "NmMessageCount" INT 0 128;
BA_DEF_  "NmBaseAddress" HEX 0 0;
BA_DEF_  "NmAsrWaitBusSleepTime" INT 1 65535;
BA_DEF_  "NmAsrTimeoutTime" INT 1 65535;
BA_DEF_  "NmAsrRepeatMessageTime" INT 1 65535;
BA_DEF_  "NmAsrMessageCount" INT 128 128;
BA_DEF_  "NmAsrCanMsgCycleTime" INT 1 65535;
BA_DEF_  "NmAsrBaseAddress" HEX 0 2047;
BA_DEF_  "Manufacturer" STRING ;
BA_DEF_  "ILTxTimeout" INT 0 65535;
BA_DEF_  "GenEnvVarPrefix" STRING ;
BA_DEF_  "GenEnvVarEndingSnd" STRING ;
BA_DEF_  "GenEnvVarEndingDsp" STRING ;
BA_DEF_  "DBName" STRING ;
BA_DEF_  "BusType" STRING ;
BA_DEF_  "Baudrate" INT 0 1000000;
BA_DEF_ SG_  "SystemSignalLongSymbol" STRING ;
BA_DEF_DEF_  "Remarks" "null";
BA_DEF_DEF_  "NWM_WakeupAllowed" "No";
BA_DEF_DEF_  "GenSigTimeoutTime_HU_Mid_X451" 500;
BA_DEF_DEF_  "GenSigTimeoutTime_HU_High_X451" 500;
BA_DEF_DEF_  "GenSigTimeoutTime_HU_B" 500;
BA_DEF_DEF_  "GenSigTimeoutTime_HU_A" 500;
BA_DEF_DEF_  "GenSigTimeoutTime_BCM_Mid" 0;
BA_DEF_DEF_  "GenSigTimeoutMsg_HU_Mid_X451" 500;
BA_DEF_DEF_  "GenSigTimeoutMsg_HU_High_X451" 500;
BA_DEF_DEF_  "GenSigTimeoutMsg_HU_B" 500;
BA_DEF_DEF_  "GenSigTimeoutMsg_HU_A" 500;
BA_DEF_DEF_  "GenSigStartValue" 0;
BA_DEF_DEF_  "GenSigSendType" "Cyclic";
BA_DEF_DEF_  "GenSigInactiveValue" 0;
BA_DEF_DEF_  "GenSigEnvVarType" "undef";
BA_DEF_DEF_  "GenSigCycleTimeActive" 0;
BA_DEF_DEF_  "GenSigCycleTime" 0;
BA_DEF_DEF_  "GenSigTimeoutMsg_HU_High_X445" 500;
BA_DEF_DEF_  "GenSigTimeoutMsg_HU_Mid_X445" 500;
BA_DEF_DEF_  "GenSigTimeoutTime_HU_High_X445" 500;
BA_DEF_DEF_  "GenSigTimeoutTime_HU_Mid_X445" 500;
BA_DEF_DEF_  "GenSigTimeoutMsg_IVI" 500;
BA_DEF_DEF_  "GenSigTimeoutTime_IVI" 500;
BA_DEF_DEF_  "NmMessage" "no";
BA_DEF_DEF_  "NmAsrMessage" "<n.a.>";
BA_DEF_DEF_  "MessageTimeout" 500;
BA_DEF_DEF_  "GenMsgStartDelayTime" 0;
BA_DEF_DEF_  "GenMsgSendType" "Cyclic";
BA_DEF_DEF_  "GenMsgNrOfRepetition" 0;
BA_DEF_DEF_  "GenMsgILSupport" "Yes";
BA_DEF_DEF_  "GenMsgDelayTime" 0;
BA_DEF_DEF_  "GenMsgCycleTimeFast" 0;
BA_DEF_DEF_  "GenMsgCycleTime" 0;
BA_DEF_DEF_  "DiagUudtResponse" "false";
BA_DEF_DEF_  "DiagUsdtResponse" "false";
BA_DEF_DEF_  "DiagState" "No";
BA_DEF_DEF_  "DiagResponse" "No";
BA_DEF_DEF_  "DiagRequest" "No";
BA_DEF_DEF_  "MsgType" "Application";
BA_DEF_DEF_  "NodeLayerModules" "null";
BA_DEF_DEF_  "NmStationAddress" 0;
BA_DEF_DEF_  "NmCAN" 3;
BA_DEF_DEF_  "NmAsrNodeIdentifier" 2;
BA_DEF_DEF_  "NmAsrNode" "<n.a.>";
BA_DEF_DEF_  "NmAsrCanMsgReducedTime" 50;
BA_DEF_DEF_  "ECU" "";
BA_DEF_DEF_  "NmType" "NmAsr";
BA_DEF_DEF_  "NmMessageCount" 128;
BA_DEF_DEF_  "NmBaseAddress" 0;
BA_DEF_DEF_  "NmAsrWaitBusSleepTime" 500;
BA_DEF_DEF_  "NmAsrTimeoutTime" 1000;
BA_DEF_DEF_  "NmAsrRepeatMessageTime" 1500;
BA_DEF_DEF_  "NmAsrMessageCount" 128;
BA_DEF_DEF_  "NmAsrCanMsgCycleTime" 200;
BA_DEF_DEF_  "NmAsrBaseAddress" 1280;
BA_DEF_DEF_  "Manufacturer" "TML";
BA_DEF_DEF_  "ILTxTimeout" 500;
BA_DEF_DEF_  "GenEnvVarPrefix" "Env";
BA_DEF_DEF_  "GenEnvVarEndingSnd" "_";
BA_DEF_DEF_  "GenEnvVarEndingDsp" "Dsp_";
BA_DEF_DEF_  "DBName" "null";
BA_DEF_DEF_  "BusType" "CAN";
BA_DEF_DEF_  "Baudrate" 500000;
BA_DEF_DEF_  "SystemSignalLongSymbol" "";
BA_ "NmBaseAddress" 1280;
BA_ "DBName" "CANBus_1";
BA_ "NmAsrNode" BU_ Skylark_EV 2;
BA_ "ECU" BU_ Skylark_EV "Gen3_IVI";
BA_ "GenMsgCycleTime" BO_ 731 20;
BA_ "GenMsgCycleTime" BO_ 730 20;
BA_ "GenMsgCycleTime" BO_ 699 100;
BA_ "GenMsgCycleTime" BO_ 371 20;
BA_ "GenMsgCycleTime" BO_ 280 10;
BA_ "GenMsgCycleTime" BO_ 703 100;
BA_ "MessageTimeout" BO_ 452 0;
BA_ "GenMsgSendType" BO_ 452 8;
BA_ "DiagResponse" BO_ 1548 1;
BA_ "GenMsgILSupport" BO_ 1548 0;
BA_ "GenMsgSendType" BO_ 1548 8;
BA_ "MessageTimeout" BO_ 1548 0;
BA_ "DiagResponse" BO_ 1804 1;
BA_ "GenMsgILSupport" BO_ 1804 0;
BA_ "GenMsgSendType" BO_ 1804 8;
BA_ "MessageTimeout" BO_ 1804 0;
BA_ "DiagRequest" BO_ 1796 1;
BA_ "GenMsgILSupport" BO_ 1796 0;
BA_ "GenMsgSendType" BO_ 1796 8;
BA_ "MessageTimeout" BO_ 1796 0;
BA_ "GenMsgILSupport" BO_ 1771 0;
BA_ "GenMsgSendType" BO_ 1771 8;
BA_ "MessageTimeout" BO_ 1771 0;
BA_ "DiagResponse" BO_ 2027 1;
BA_ "GenMsgILSupport" BO_ 2027 0;
BA_ "GenMsgSendType" BO_ 2027 8;
BA_ "MessageTimeout" BO_ 2027 0;
BA_ "GenMsgILSupport" BO_ 1763 0;
BA_ "GenMsgSendType" BO_ 1763 8;
BA_ "MessageTimeout" BO_ 1763 0;
BA_ "DiagRequest" BO_ 2019 1;
BA_ "GenMsgILSupport" BO_ 2019 0;
BA_ "GenMsgSendType" BO_ 2019 8;
BA_ "MessageTimeout" BO_ 2019 0;
BA_ "DiagResponse" BO_ 1849 1;
BA_ "GenMsgILSupport" BO_ 1849 0;
BA_ "GenMsgSendType" BO_ 1849 8;
BA_ "MessageTimeout" BO_ 1849 0;
BA_ "DiagRequest" BO_ 1841 1;
BA_ "GenMsgILSupport" BO_ 1841 0;
BA_ "GenMsgSendType" BO_ 1841 8;
BA_ "MessageTimeout" BO_ 1841 0;
BA_ "DiagResponse" BO_ 1630 1;
BA_ "GenMsgILSupport" BO_ 1630 0;
BA_ "GenMsgSendType" BO_ 1630 8;
BA_ "MessageTimeout" BO_ 1630 0;
BA_ "DiagResponse" BO_ 1886 1;
BA_ "GenMsgILSupport" BO_ 1886 0;
BA_ "GenMsgSendType" BO_ 1886 8;
BA_ "MessageTimeout" BO_ 1886 0;
BA_ "DiagRequest" BO_ 1878 1;
BA_ "GenMsgILSupport" BO_ 1878 0;
BA_ "GenMsgSendType" BO_ 1878 8;
BA_ "MessageTimeout" BO_ 1878 0;
BA_ "DiagResponse" BO_ 1546 1;
BA_ "GenMsgILSupport" BO_ 1546 0;
BA_ "GenMsgSendType" BO_ 1546 8;
BA_ "MessageTimeout" BO_ 1546 0;
BA_ "DiagResponse" BO_ 1802 1;
BA_ "GenMsgILSupport" BO_ 1802 0;
BA_ "GenMsgSendType" BO_ 1802 8;
BA_ "MessageTimeout" BO_ 1802 0;
BA_ "DiagRequest" BO_ 1794 1;
BA_ "GenMsgILSupport" BO_ 1794 0;
BA_ "GenMsgSendType" BO_ 1794 8;
BA_ "MessageTimeout" BO_ 1794 0;
BA_ "DiagResponse" BO_ 1610 1;
BA_ "GenMsgILSupport" BO_ 1610 0;
BA_ "GenMsgSendType" BO_ 1610 8;
BA_ "MessageTimeout" BO_ 1610 0;
BA_ "DiagResponse" BO_ 1866 1;
BA_ "GenMsgILSupport" BO_ 1866 0;
BA_ "GenMsgSendType" BO_ 1866 8;
BA_ "MessageTimeout" BO_ 1866 0;
BA_ "DiagRequest" BO_ 1858 1;
BA_ "GenMsgILSupport" BO_ 1858 0;
BA_ "GenMsgSendType" BO_ 1858 8;
BA_ "MessageTimeout" BO_ 1858 0;
BA_ "DiagResponse" BO_ 1560 1;
BA_ "GenMsgILSupport" BO_ 1560 0;
BA_ "GenMsgSendType" BO_ 1560 8;
BA_ "MessageTimeout" BO_ 1560 0;
BA_ "DiagResponse" BO_ 1816 1;
BA_ "GenMsgILSupport" BO_ 1816 0;
BA_ "GenMsgSendType" BO_ 1816 8;
BA_ "MessageTimeout" BO_ 1816 0;
BA_ "DiagRequest" BO_ 1808 1;
BA_ "GenMsgILSupport" BO_ 1808 0;
BA_ "GenMsgSendType" BO_ 1808 8;
BA_ "MessageTimeout" BO_ 1808 0;
BA_ "DiagResponse" BO_ 1564 1;
BA_ "GenMsgILSupport" BO_ 1564 0;
BA_ "GenMsgSendType" BO_ 1564 8;
BA_ "MessageTimeout" BO_ 1564 0;
BA_ "DiagResponse" BO_ 1820 1;
BA_ "GenMsgILSupport" BO_ 1820 0;
BA_ "GenMsgSendType" BO_ 1820 8;
BA_ "MessageTimeout" BO_ 1820 0;
BA_ "DiagRequest" BO_ 1812 1;
BA_ "GenMsgILSupport" BO_ 1812 0;
BA_ "GenMsgSendType" BO_ 1812 8;
BA_ "MessageTimeout" BO_ 1812 0;
BA_ "DiagResponse" BO_ 1608 1;
BA_ "GenMsgILSupport" BO_ 1608 0;
BA_ "GenMsgSendType" BO_ 1608 8;
BA_ "MessageTimeout" BO_ 1608 0;
BA_ "DiagResponse" BO_ 1864 1;
BA_ "GenMsgILSupport" BO_ 1864 0;
BA_ "GenMsgSendType" BO_ 1864 8;
BA_ "MessageTimeout" BO_ 1864 0;
BA_ "DiagRequest" BO_ 1856 1;
BA_ "GenMsgILSupport" BO_ 1856 0;
BA_ "GenMsgSendType" BO_ 1856 8;
BA_ "MessageTimeout" BO_ 1856 0;
BA_ "DiagResponse" BO_ 1609 1;
BA_ "GenMsgILSupport" BO_ 1609 0;
BA_ "GenMsgSendType" BO_ 1609 8;
BA_ "MessageTimeout" BO_ 1609 0;
BA_ "DiagResponse" BO_ 1865 1;
BA_ "GenMsgILSupport" BO_ 1865 0;
BA_ "GenMsgSendType" BO_ 1865 8;
BA_ "MessageTimeout" BO_ 1865 0;
BA_ "DiagRequest" BO_ 1857 1;
BA_ "GenMsgILSupport" BO_ 1857 0;
BA_ "GenMsgSendType" BO_ 1857 8;
BA_ "MessageTimeout" BO_ 1857 0;
BA_ "DiagResponse" BO_ 1624 1;
BA_ "GenMsgILSupport" BO_ 1624 0;
BA_ "GenMsgSendType" BO_ 1624 8;
BA_ "MessageTimeout" BO_ 1624 0;
BA_ "DiagResponse" BO_ 1880 1;
BA_ "GenMsgILSupport" BO_ 1880 0;
BA_ "GenMsgSendType" BO_ 1880 8;
BA_ "MessageTimeout" BO_ 1880 0;
BA_ "DiagRequest" BO_ 1872 1;
BA_ "GenMsgILSupport" BO_ 1872 0;
BA_ "GenMsgSendType" BO_ 1872 8;
BA_ "MessageTimeout" BO_ 1872 0;
BA_ "DiagResponse" BO_ 1884 1;
BA_ "GenMsgILSupport" BO_ 1884 0;
BA_ "GenMsgSendType" BO_ 1884 8;
BA_ "MessageTimeout" BO_ 1884 0;
BA_ "DiagRequest" BO_ 1876 1;
BA_ "GenMsgILSupport" BO_ 1876 0;
BA_ "GenMsgSendType" BO_ 1876 8;
BA_ "MessageTimeout" BO_ 1876 0;
BA_ "DiagResponse" BO_ 1626 1;
BA_ "GenMsgILSupport" BO_ 1626 0;
BA_ "GenMsgSendType" BO_ 1626 8;
BA_ "MessageTimeout" BO_ 1626 0;
BA_ "DiagResponse" BO_ 1882 1;
BA_ "GenMsgILSupport" BO_ 1882 0;
BA_ "GenMsgSendType" BO_ 1882 8;
BA_ "MessageTimeout" BO_ 1882 0;
BA_ "DiagRequest" BO_ 1874 1;
BA_ "GenMsgILSupport" BO_ 1874 0;
BA_ "GenMsgSendType" BO_ 1874 8;
BA_ "MessageTimeout" BO_ 1874 0;
BA_ "DiagResponse" BO_ 1549 1;
BA_ "GenMsgILSupport" BO_ 1549 0;
BA_ "GenMsgSendType" BO_ 1549 8;
BA_ "MessageTimeout" BO_ 1549 0;
BA_ "DiagResponse" BO_ 1805 1;
BA_ "GenMsgILSupport" BO_ 1805 0;
BA_ "GenMsgSendType" BO_ 1805 8;
BA_ "MessageTimeout" BO_ 1805 0;
BA_ "DiagRequest" BO_ 1797 1;
BA_ "GenMsgILSupport" BO_ 1797 0;
BA_ "GenMsgSendType" BO_ 1797 8;
BA_ "MessageTimeout" BO_ 1797 0;
BA_ "DiagResponse" BO_ 1545 1;
BA_ "GenMsgILSupport" BO_ 1545 0;
BA_ "GenMsgSendType" BO_ 1545 8;
BA_ "MessageTimeout" BO_ 1545 0;
BA_ "DiagResponse" BO_ 1801 1;
BA_ "GenMsgILSupport" BO_ 1801 0;
BA_ "GenMsgSendType" BO_ 1801 8;
BA_ "MessageTimeout" BO_ 1801 0;
BA_ "DiagRequest" BO_ 1793 1;
BA_ "GenMsgILSupport" BO_ 1793 0;
BA_ "GenMsgSendType" BO_ 1793 8;
BA_ "MessageTimeout" BO_ 1793 0;
BA_ "GenMsgCycleTime" BO_ 708 100;
BA_ "GenMsgStartDelayTime" BO_ 708 10;
BA_ "MessageTimeout" BO_ 1109 0;
BA_ "GenMsgSendType" BO_ 1109 8;
BA_ "GenMsgNrOfRepetition" BO_ 1109 3;
BA_ "GenMsgDelayTime" BO_ 1109 100;
BA_ "GenMsgCycleTimeFast" BO_ 1109 100;
BA_ "MessageTimeout" BO_ 1126 0;
BA_ "GenMsgSendType" BO_ 1126 8;
BA_ "GenMsgNrOfRepetition" BO_ 1126 3;
BA_ "GenMsgDelayTime" BO_ 1126 100;
BA_ "GenMsgCycleTimeFast" BO_ 1126 100;
BA_ "MessageTimeout" BO_ 945 2500;
BA_ "GenMsgCycleTime" BO_ 945 500;
BA_ "MessageTimeout" BO_ 535 0;
BA_ "GenMsgSendType" BO_ 535 8;
BA_ "GenMsgNrOfRepetition" BO_ 535 3;
BA_ "GenMsgDelayTime" BO_ 535 200;
BA_ "GenMsgCycleTimeFast" BO_ 535 200;
BA_ "GenMsgStartDelayTime" BO_ 754 10;
BA_ "GenMsgCycleTime" BO_ 754 100;
BA_ "GenMsgCycleTime" BO_ 756 100;
BA_ "GenMsgCycleTime" BO_ 753 100;
BA_ "GenMsgCycleTime" BO_ 382 20;
BA_ "MessageTimeout" BO_ 529 0;
BA_ "GenMsgSendType" BO_ 529 8;
BA_ "GenMsgNrOfRepetition" BO_ 529 10;
BA_ "GenMsgDelayTime" BO_ 529 100;
BA_ "GenMsgCycleTimeFast" BO_ 529 100;
BA_ "MessageTimeout" BO_ 528 0;
BA_ "GenMsgSendType" BO_ 528 8;
BA_ "GenMsgNrOfRepetition" BO_ 528 3;
BA_ "GenMsgDelayTime" BO_ 528 200;
BA_ "GenMsgCycleTimeFast" BO_ 528 200;
BA_ "MessageTimeout" BO_ 527 0;
BA_ "GenMsgSendType" BO_ 527 8;
BA_ "GenMsgStartDelayTime" BO_ 751 10;
BA_ "GenMsgCycleTime" BO_ 751 100;
BA_ "GenMsgCycleTime" BO_ 749 100;
BA_ "MessageTimeout" BO_ 864 1000;
BA_ "GenMsgCycleTime" BO_ 864 200;
BA_ "GenSigSendType" SG_ 731 GyroInfoZ 7;
BA_ "GenSigCycleTimeActive" SG_ 731 GyroInfoZ 20;
BA_ "GenSigCycleTime" SG_ 731 GyroInfoZ 20;
BA_ "GenSigSendType" SG_ 731 GyroInfoY 7;
BA_ "GenSigCycleTimeActive" SG_ 731 GyroInfoY 20;
BA_ "GenSigCycleTime" SG_ 731 GyroInfoY 20;
BA_ "GenSigSendType" SG_ 731 GyroInfoXYZStatus 7;
BA_ "GenSigCycleTimeActive" SG_ 731 GyroInfoXYZStatus 20;
BA_ "GenSigCycleTime" SG_ 731 GyroInfoXYZStatus 20;
BA_ "GenSigSendType" SG_ 731 GyroInfoX 7;
BA_ "GenSigCycleTimeActive" SG_ 731 GyroInfoX 20;
BA_ "GenSigCycleTime" SG_ 731 GyroInfoX 20;
BA_ "GenSigSendType" SG_ 730 AcclrmInfoZ 7;
BA_ "GenSigCycleTimeActive" SG_ 730 AcclrmInfoZ 20;
BA_ "GenSigCycleTime" SG_ 730 AcclrmInfoZ 20;
BA_ "GenSigSendType" SG_ 730 AcclrmInfoY 7;
BA_ "GenSigCycleTimeActive" SG_ 730 AcclrmInfoY 20;
BA_ "GenSigCycleTime" SG_ 730 AcclrmInfoY 20;
BA_ "GenSigSendType" SG_ 730 AcclrmInfoXYZStatus 7;
BA_ "GenSigCycleTimeActive" SG_ 730 AcclrmInfoXYZStatus 20;
BA_ "GenSigCycleTime" SG_ 730 AcclrmInfoXYZStatus 20;
BA_ "GenSigSendType" SG_ 730 AcclrmInfoX 7;
BA_ "GenSigCycleTimeActive" SG_ 730 AcclrmInfoX 20;
BA_ "GenSigCycleTime" SG_ 730 AcclrmInfoX 20;
BA_ "GenSigSendType" SG_ 699 IcHuTripBInfofull 7;
BA_ "GenSigCycleTimeActive" SG_ 699 IcHuTripBInfofull 100;
BA_ "GenSigCycleTime" SG_ 699 IcHuTripBInfofull 100;
BA_ "GenSigSendType" SG_ 699 IcHuTripAInfofull 7;
BA_ "GenSigCycleTimeActive" SG_ 699 IcHuTripAInfofull 100;
BA_ "GenSigCycleTime" SG_ 699 IcHuTripAInfofull 100;
BA_ "GenSigSendType" SG_ 371 SteerAngEPAsDirGen2 7;
BA_ "GenSigCycleTimeActive" SG_ 371 SteerAngEPAsDirGen2 20;
BA_ "GenSigCycleTime" SG_ 371 SteerAngEPAsDirGen2 20;
BA_ "GenSigSendType" SG_ 371 MSG_CNT_6 7;
BA_ "GenSigCycleTimeActive" SG_ 371 MSG_CNT_6 20;
BA_ "GenSigCycleTime" SG_ 371 MSG_CNT_6 20;
BA_ "GenSigSendType" SG_ 371 CRC_6 7;
BA_ "GenSigCycleTimeActive" SG_ 371 CRC_6 20;
BA_ "GenSigCycleTime" SG_ 371 CRC_6 20;
BA_ "GenSigSendType" SG_ 280 MSG_CNT_19 7;
BA_ "GenSigCycleTimeActive" SG_ 280 MSG_CNT_19 20;
BA_ "GenSigCycleTime" SG_ 280 MSG_CNT_19 20;
BA_ "GenSigSendType" SG_ 280 CRC_19 7;
BA_ "GenSigCycleTimeActive" SG_ 280 CRC_19 20;
BA_ "GenSigCycleTime" SG_ 280 CRC_19 20;
BA_ "GenSigSendType" SG_ 280 BrakePaddlePosStatus 7;
BA_ "GenSigCycleTimeActive" SG_ 280 BrakePaddlePosStatus 20;
BA_ "GenSigCycleTime" SG_ 280 BrakePaddlePosStatus 20;
BA_ "GenSigSendType" SG_ 280 BrakePaddlePos 7;
BA_ "GenSigCycleTimeActive" SG_ 280 BrakePaddlePos 20;
BA_ "GenSigCycleTime" SG_ 280 BrakePaddlePos 20;
BA_ "GenSigStartValue" SG_ 703 OATICSigNewStatus 2;
BA_ "GenSigSendType" SG_ 703 OATICSigNewStatus 7;
BA_ "GenSigCycleTimeActive" SG_ 703 OATICSigNewStatus 100;
BA_ "GenSigCycleTime" SG_ 703 OATICSigNewStatus 100;
BA_ "GenSigStartValue" SG_ 703 OATICSigNew 130;
BA_ "GenSigSendType" SG_ 703 OATICSigNew 7;
BA_ "GenSigCycleTimeActive" SG_ 703 OATICSigNew 100;
BA_ "GenSigCycleTime" SG_ 703 OATICSigNew 100;
BA_ "GenSigTimeoutTime_HU_Mid_X451" SG_ 452 OwnersBirthdayResponse 0;
BA_ "GenSigTimeoutTime_HU_High_X451" SG_ 452 OwnersBirthdayResponse 0;
BA_ "GenSigTimeoutTime_HU_B" SG_ 452 OwnersBirthdayResponse 0;
BA_ "GenSigTimeoutTime_HU_A" SG_ 452 OwnersBirthdayResponse 0;
BA_ "GenSigTimeoutMsg_HU_Mid_X451" SG_ 452 OwnersBirthdayResponse 0;
BA_ "GenSigTimeoutMsg_HU_High_X451" SG_ 452 OwnersBirthdayResponse 0;
BA_ "GenSigTimeoutMsg_HU_B" SG_ 452 OwnersBirthdayResponse 0;
BA_ "GenSigTimeoutMsg_HU_A" SG_ 452 OwnersBirthdayResponse 0;
BA_ "GenSigSendType" SG_ 452 OwnersBirthdayResponse 1;
BA_ "GenSigTimeoutMsg_HU_High_X445" SG_ 452 OwnersBirthdayResponse 0;
BA_ "GenSigTimeoutMsg_HU_Mid_X445" SG_ 452 OwnersBirthdayResponse 0;
BA_ "GenSigTimeoutTime_HU_High_X445" SG_ 452 OwnersBirthdayResponse 0;
BA_ "GenSigTimeoutTime_HU_Mid_X445" SG_ 452 OwnersBirthdayResponse 0;
BA_ "GenSigTimeoutMsg_IVI" SG_ 452 OwnersBirthdayResponse 0;
BA_ "GenSigTimeoutTime_IVI" SG_ 452 OwnersBirthdayResponse 0;
BA_ "GenSigTimeoutTime_HU_Mid_X451" SG_ 452 OwnersAnniversaryResponse 0;
BA_ "GenSigTimeoutTime_HU_High_X451" SG_ 452 OwnersAnniversaryResponse 0;
BA_ "GenSigTimeoutTime_HU_B" SG_ 452 OwnersAnniversaryResponse 0;
BA_ "GenSigTimeoutTime_HU_A" SG_ 452 OwnersAnniversaryResponse 0;
BA_ "GenSigTimeoutMsg_HU_Mid_X451" SG_ 452 OwnersAnniversaryResponse 0;
BA_ "GenSigTimeoutMsg_HU_High_X451" SG_ 452 OwnersAnniversaryResponse 0;
BA_ "GenSigTimeoutMsg_HU_B" SG_ 452 OwnersAnniversaryResponse 0;
BA_ "GenSigTimeoutMsg_HU_A" SG_ 452 OwnersAnniversaryResponse 0;
BA_ "GenSigSendType" SG_ 452 OwnersAnniversaryResponse 1;
BA_ "GenSigTimeoutMsg_HU_High_X445" SG_ 452 OwnersAnniversaryResponse 0;
BA_ "GenSigTimeoutMsg_HU_Mid_X445" SG_ 452 OwnersAnniversaryResponse 0;
BA_ "GenSigTimeoutTime_HU_High_X445" SG_ 452 OwnersAnniversaryResponse 0;
BA_ "GenSigTimeoutTime_HU_Mid_X445" SG_ 452 OwnersAnniversaryResponse 0;
BA_ "GenSigTimeoutMsg_IVI" SG_ 452 OwnersAnniversaryResponse 0;
BA_ "GenSigTimeoutTime_IVI" SG_ 452 OwnersAnniversaryResponse 0;
BA_ "GenSigTimeoutTime_HU_Mid_X451" SG_ 452 CarAnniversaryResponse 0;
BA_ "GenSigTimeoutTime_HU_High_X451" SG_ 452 CarAnniversaryResponse 0;
BA_ "GenSigTimeoutTime_HU_B" SG_ 452 CarAnniversaryResponse 0;
BA_ "GenSigTimeoutTime_HU_A" SG_ 452 CarAnniversaryResponse 0;
BA_ "GenSigTimeoutMsg_HU_Mid_X451" SG_ 452 CarAnniversaryResponse 0;
BA_ "GenSigTimeoutMsg_HU_High_X451" SG_ 452 CarAnniversaryResponse 0;
BA_ "GenSigTimeoutMsg_HU_B" SG_ 452 CarAnniversaryResponse 0;
BA_ "GenSigTimeoutMsg_HU_A" SG_ 452 CarAnniversaryResponse 0;
BA_ "GenSigSendType" SG_ 452 CarAnniversaryResponse 1;
BA_ "GenSigTimeoutMsg_HU_High_X445" SG_ 452 CarAnniversaryResponse 0;
BA_ "GenSigTimeoutMsg_HU_Mid_X445" SG_ 452 CarAnniversaryResponse 0;
BA_ "GenSigTimeoutTime_HU_High_X445" SG_ 452 CarAnniversaryResponse 0;
BA_ "GenSigTimeoutTime_HU_Mid_X445" SG_ 452 CarAnniversaryResponse 0;
BA_ "GenSigTimeoutMsg_IVI" SG_ 452 CarAnniversaryResponse 0;
BA_ "GenSigTimeoutTime_IVI" SG_ 452 CarAnniversaryResponse 0;
BA_ "GenSigTimeoutTime_IVI" SG_ 1548 VICM_DiagResponse_UUDT 0;
BA_ "GenSigTimeoutMsg_IVI" SG_ 1548 VICM_DiagResponse_UUDT 0;
BA_ "GenSigTimeoutTime_HU_Mid_X445" SG_ 1548 VICM_DiagResponse_UUDT 0;
BA_ "GenSigTimeoutTime_HU_High_X445" SG_ 1548 VICM_DiagResponse_UUDT 0;
BA_ "GenSigTimeoutMsg_HU_Mid_X445" SG_ 1548 VICM_DiagResponse_UUDT 0;
BA_ "GenSigTimeoutMsg_HU_High_X445" SG_ 1548 VICM_DiagResponse_UUDT 0;
BA_ "GenSigSendType" SG_ 1548 VICM_DiagResponse_UUDT 1;
BA_ "GenSigTimeoutMsg_HU_A" SG_ 1548 VICM_DiagResponse_UUDT 0;
BA_ "GenSigTimeoutMsg_HU_B" SG_ 1548 VICM_DiagResponse_UUDT 0;
BA_ "GenSigTimeoutMsg_HU_High_X451" SG_ 1548 VICM_DiagResponse_UUDT 0;
BA_ "GenSigTimeoutMsg_HU_Mid_X451" SG_ 1548 VICM_DiagResponse_UUDT 0;
BA_ "GenSigTimeoutTime_HU_A" SG_ 1548 VICM_DiagResponse_UUDT 0;
BA_ "GenSigTimeoutTime_HU_B" SG_ 1548 VICM_DiagResponse_UUDT 0;
BA_ "GenSigTimeoutTime_HU_High_X451" SG_ 1548 VICM_DiagResponse_UUDT 0;
BA_ "GenSigTimeoutTime_HU_Mid_X451" SG_ 1548 VICM_DiagResponse_UUDT 0;
BA_ "GenSigTimeoutTime_IVI" SG_ 1804 VICM_DiagResponse_USDT 0;
BA_ "GenSigTimeoutMsg_IVI" SG_ 1804 VICM_DiagResponse_USDT 0;
BA_ "GenSigTimeoutTime_HU_Mid_X445" SG_ 1804 VICM_DiagResponse_USDT 0;
BA_ "GenSigTimeoutTime_HU_High_X445" SG_ 1804 VICM_DiagResponse_USDT 0;
BA_ "GenSigTimeoutMsg_HU_Mid_X445" SG_ 1804 VICM_DiagResponse_USDT 0;
BA_ "GenSigTimeoutMsg_HU_High_X445" SG_ 1804 VICM_DiagResponse_USDT 0;
BA_ "GenSigSendType" SG_ 1804 VICM_DiagResponse_USDT 1;
BA_ "GenSigTimeoutMsg_HU_A" SG_ 1804 VICM_DiagResponse_USDT 0;
BA_ "GenSigTimeoutMsg_HU_B" SG_ 1804 VICM_DiagResponse_USDT 0;
BA_ "GenSigTimeoutMsg_HU_High_X451" SG_ 1804 VICM_DiagResponse_USDT 0;
BA_ "GenSigTimeoutMsg_HU_Mid_X451" SG_ 1804 VICM_DiagResponse_USDT 0;
BA_ "GenSigTimeoutTime_HU_A" SG_ 1804 VICM_DiagResponse_USDT 0;
BA_ "GenSigTimeoutTime_HU_B" SG_ 1804 VICM_DiagResponse_USDT 0;
BA_ "GenSigTimeoutTime_HU_High_X451" SG_ 1804 VICM_DiagResponse_USDT 0;
BA_ "GenSigTimeoutTime_HU_Mid_X451" SG_ 1804 VICM_DiagResponse_USDT 0;
BA_ "GenSigTimeoutTime_IVI" SG_ 1796 VICM_DiagRequest 0;
BA_ "GenSigTimeoutMsg_IVI" SG_ 1796 VICM_DiagRequest 0;
BA_ "GenSigTimeoutTime_HU_Mid_X445" SG_ 1796 VICM_DiagRequest 0;
BA_ "GenSigTimeoutTime_HU_High_X445" SG_ 1796 VICM_DiagRequest 0;
BA_ "GenSigTimeoutMsg_HU_Mid_X445" SG_ 1796 VICM_DiagRequest 0;
BA_ "GenSigTimeoutMsg_HU_High_X445" SG_ 1796 VICM_DiagRequest 0;
BA_ "GenSigSendType" SG_ 1796 VICM_DiagRequest 1;
BA_ "GenSigTimeoutMsg_HU_A" SG_ 1796 VICM_DiagRequest 0;
BA_ "GenSigTimeoutMsg_HU_B" SG_ 1796 VICM_DiagRequest 0;
BA_ "GenSigTimeoutMsg_HU_High_X451" SG_ 1796 VICM_DiagRequest 0;
BA_ "GenSigTimeoutMsg_HU_Mid_X451" SG_ 1796 VICM_DiagRequest 0;
BA_ "GenSigTimeoutTime_HU_A" SG_ 1796 VICM_DiagRequest 0;
BA_ "GenSigTimeoutTime_HU_B" SG_ 1796 VICM_DiagRequest 0;
BA_ "GenSigTimeoutTime_HU_High_X451" SG_ 1796 VICM_DiagRequest 0;
BA_ "GenSigTimeoutTime_HU_Mid_X451" SG_ 1796 VICM_DiagRequest 0;
BA_ "GenSigTimeoutTime_IVI" SG_ 1771 VCU_DiagResponse_UUDT 0;
BA_ "GenSigTimeoutMsg_IVI" SG_ 1771 VCU_DiagResponse_UUDT 0;
BA_ "GenSigTimeoutTime_HU_Mid_X445" SG_ 1771 VCU_DiagResponse_UUDT 0;
BA_ "GenSigTimeoutTime_HU_High_X445" SG_ 1771 VCU_DiagResponse_UUDT 0;
BA_ "GenSigTimeoutMsg_HU_Mid_X445" SG_ 1771 VCU_DiagResponse_UUDT 0;
BA_ "GenSigTimeoutMsg_HU_High_X445" SG_ 1771 VCU_DiagResponse_UUDT 0;
BA_ "GenSigSendType" SG_ 1771 VCU_DiagResponse_UUDT 1;
BA_ "GenSigTimeoutMsg_HU_A" SG_ 1771 VCU_DiagResponse_UUDT 0;
BA_ "GenSigTimeoutMsg_HU_B" SG_ 1771 VCU_DiagResponse_UUDT 0;
BA_ "GenSigTimeoutMsg_HU_High_X451" SG_ 1771 VCU_DiagResponse_UUDT 0;
BA_ "GenSigTimeoutMsg_HU_Mid_X451" SG_ 1771 VCU_DiagResponse_UUDT 0;
BA_ "GenSigTimeoutTime_HU_A" SG_ 1771 VCU_DiagResponse_UUDT 0;
BA_ "GenSigTimeoutTime_HU_B" SG_ 1771 VCU_DiagResponse_UUDT 0;
BA_ "GenSigTimeoutTime_HU_High_X451" SG_ 1771 VCU_DiagResponse_UUDT 0;
BA_ "GenSigTimeoutTime_HU_Mid_X451" SG_ 1771 VCU_DiagResponse_UUDT 0;
BA_ "GenSigTimeoutTime_IVI" SG_ 2027 VCU_DiagResponse_USDT 0;
BA_ "GenSigTimeoutMsg_IVI" SG_ 2027 VCU_DiagResponse_USDT 0;
BA_ "GenSigTimeoutTime_HU_Mid_X445" SG_ 2027 VCU_DiagResponse_USDT 0;
BA_ "GenSigTimeoutTime_HU_High_X445" SG_ 2027 VCU_DiagResponse_USDT 0;
BA_ "GenSigTimeoutMsg_HU_Mid_X445" SG_ 2027 VCU_DiagResponse_USDT 0;
BA_ "GenSigTimeoutMsg_HU_High_X445" SG_ 2027 VCU_DiagResponse_USDT 0;
BA_ "GenSigSendType" SG_ 2027 VCU_DiagResponse_USDT 1;
BA_ "GenSigTimeoutMsg_HU_A" SG_ 2027 VCU_DiagResponse_USDT 0;
BA_ "GenSigTimeoutMsg_HU_B" SG_ 2027 VCU_DiagResponse_USDT 0;
BA_ "GenSigTimeoutMsg_HU_High_X451" SG_ 2027 VCU_DiagResponse_USDT 0;
BA_ "GenSigTimeoutMsg_HU_Mid_X451" SG_ 2027 VCU_DiagResponse_USDT 0;
BA_ "GenSigTimeoutTime_HU_A" SG_ 2027 VCU_DiagResponse_USDT 0;
BA_ "GenSigTimeoutTime_HU_B" SG_ 2027 VCU_DiagResponse_USDT 0;
BA_ "GenSigTimeoutTime_HU_High_X451" SG_ 2027 VCU_DiagResponse_USDT 0;
BA_ "GenSigTimeoutTime_HU_Mid_X451" SG_ 2027 VCU_DiagResponse_USDT 0;
BA_ "GenSigTimeoutTime_IVI" SG_ 1763 VCU_DiagRequest_UUDT 0;
BA_ "GenSigTimeoutMsg_IVI" SG_ 1763 VCU_DiagRequest_UUDT 0;
BA_ "GenSigTimeoutTime_HU_Mid_X445" SG_ 1763 VCU_DiagRequest_UUDT 0;
BA_ "GenSigTimeoutTime_HU_High_X445" SG_ 1763 VCU_DiagRequest_UUDT 0;
BA_ "GenSigTimeoutMsg_HU_Mid_X445" SG_ 1763 VCU_DiagRequest_UUDT 0;
BA_ "GenSigTimeoutMsg_HU_High_X445" SG_ 1763 VCU_DiagRequest_UUDT 0;
BA_ "GenSigSendType" SG_ 1763 VCU_DiagRequest_UUDT 1;
BA_ "GenSigTimeoutMsg_HU_A" SG_ 1763 VCU_DiagRequest_UUDT 0;
BA_ "GenSigTimeoutMsg_HU_B" SG_ 1763 VCU_DiagRequest_UUDT 0;
BA_ "GenSigTimeoutMsg_HU_High_X451" SG_ 1763 VCU_DiagRequest_UUDT 0;
BA_ "GenSigTimeoutMsg_HU_Mid_X451" SG_ 1763 VCU_DiagRequest_UUDT 0;
BA_ "GenSigTimeoutTime_HU_A" SG_ 1763 VCU_DiagRequest_UUDT 0;
BA_ "GenSigTimeoutTime_HU_B" SG_ 1763 VCU_DiagRequest_UUDT 0;
BA_ "GenSigTimeoutTime_HU_High_X451" SG_ 1763 VCU_DiagRequest_UUDT 0;
BA_ "GenSigTimeoutTime_HU_Mid_X451" SG_ 1763 VCU_DiagRequest_UUDT 0;
BA_ "GenSigTimeoutTime_IVI" SG_ 2019 VCU_DiagRequest_USDT 0;
BA_ "GenSigTimeoutMsg_IVI" SG_ 2019 VCU_DiagRequest_USDT 0;
BA_ "GenSigTimeoutTime_HU_Mid_X445" SG_ 2019 VCU_DiagRequest_USDT 0;
BA_ "GenSigTimeoutTime_HU_High_X445" SG_ 2019 VCU_DiagRequest_USDT 0;
BA_ "GenSigTimeoutMsg_HU_Mid_X445" SG_ 2019 VCU_DiagRequest_USDT 0;
BA_ "GenSigTimeoutMsg_HU_High_X445" SG_ 2019 VCU_DiagRequest_USDT 0;
BA_ "GenSigSendType" SG_ 2019 VCU_DiagRequest_USDT 1;
BA_ "GenSigTimeoutMsg_HU_A" SG_ 2019 VCU_DiagRequest_USDT 0;
BA_ "GenSigTimeoutMsg_HU_B" SG_ 2019 VCU_DiagRequest_USDT 0;
BA_ "GenSigTimeoutMsg_HU_High_X451" SG_ 2019 VCU_DiagRequest_USDT 0;
BA_ "GenSigTimeoutMsg_HU_Mid_X451" SG_ 2019 VCU_DiagRequest_USDT 0;
BA_ "GenSigTimeoutTime_HU_A" SG_ 2019 VCU_DiagRequest_USDT 0;
BA_ "GenSigTimeoutTime_HU_B" SG_ 2019 VCU_DiagRequest_USDT 0;
BA_ "GenSigTimeoutTime_HU_High_X451" SG_ 2019 VCU_DiagRequest_USDT 0;
BA_ "GenSigTimeoutTime_HU_Mid_X451" SG_ 2019 VCU_DiagRequest_USDT 0;
BA_ "GenSigTimeoutTime_IVI" SG_ 1849 WPC_DiagResponse_USDT 0;
BA_ "GenSigTimeoutMsg_IVI" SG_ 1849 WPC_DiagResponse_USDT 0;
BA_ "GenSigTimeoutTime_HU_Mid_X445" SG_ 1849 WPC_DiagResponse_USDT 0;
BA_ "GenSigTimeoutTime_HU_High_X445" SG_ 1849 WPC_DiagResponse_USDT 0;
BA_ "GenSigTimeoutMsg_HU_Mid_X445" SG_ 1849 WPC_DiagResponse_USDT 0;
BA_ "GenSigTimeoutMsg_HU_High_X445" SG_ 1849 WPC_DiagResponse_USDT 0;
BA_ "GenSigSendType" SG_ 1849 WPC_DiagResponse_USDT 1;
BA_ "GenSigTimeoutMsg_HU_A" SG_ 1849 WPC_DiagResponse_USDT 0;
BA_ "GenSigTimeoutMsg_HU_B" SG_ 1849 WPC_DiagResponse_USDT 0;
BA_ "GenSigTimeoutMsg_HU_High_X451" SG_ 1849 WPC_DiagResponse_USDT 0;
BA_ "GenSigTimeoutMsg_HU_Mid_X451" SG_ 1849 WPC_DiagResponse_USDT 0;
BA_ "GenSigTimeoutTime_HU_A" SG_ 1849 WPC_DiagResponse_USDT 0;
BA_ "GenSigTimeoutTime_HU_B" SG_ 1849 WPC_DiagResponse_USDT 0;
BA_ "GenSigTimeoutTime_HU_High_X451" SG_ 1849 WPC_DiagResponse_USDT 0;
BA_ "GenSigTimeoutTime_HU_Mid_X451" SG_ 1849 WPC_DiagResponse_USDT 0;
BA_ "GenSigTimeoutTime_IVI" SG_ 1841 WPC_DiagRequest 0;
BA_ "GenSigTimeoutMsg_IVI" SG_ 1841 WPC_DiagRequest 0;
BA_ "GenSigTimeoutTime_HU_Mid_X445" SG_ 1841 WPC_DiagRequest 0;
BA_ "GenSigTimeoutTime_HU_High_X445" SG_ 1841 WPC_DiagRequest 0;
BA_ "GenSigTimeoutMsg_HU_Mid_X445" SG_ 1841 WPC_DiagRequest 0;
BA_ "GenSigTimeoutMsg_HU_High_X445" SG_ 1841 WPC_DiagRequest 0;
BA_ "GenSigSendType" SG_ 1841 WPC_DiagRequest 1;
BA_ "GenSigTimeoutMsg_HU_A" SG_ 1841 WPC_DiagRequest 0;
BA_ "GenSigTimeoutMsg_HU_B" SG_ 1841 WPC_DiagRequest 0;
BA_ "GenSigTimeoutMsg_HU_High_X451" SG_ 1841 WPC_DiagRequest 0;
BA_ "GenSigTimeoutMsg_HU_Mid_X451" SG_ 1841 WPC_DiagRequest 0;
BA_ "GenSigTimeoutTime_HU_A" SG_ 1841 WPC_DiagRequest 0;
BA_ "GenSigTimeoutTime_HU_B" SG_ 1841 WPC_DiagRequest 0;
BA_ "GenSigTimeoutTime_HU_High_X451" SG_ 1841 WPC_DiagRequest 0;
BA_ "GenSigTimeoutTime_HU_Mid_X451" SG_ 1841 WPC_DiagRequest 0;
BA_ "GenSigTimeoutTime_IVI" SG_ 1630 TPMS_DiagResponse_UUDT 0;
BA_ "GenSigTimeoutMsg_IVI" SG_ 1630 TPMS_DiagResponse_UUDT 0;
BA_ "GenSigTimeoutTime_HU_Mid_X445" SG_ 1630 TPMS_DiagResponse_UUDT 0;
BA_ "GenSigTimeoutTime_HU_High_X445" SG_ 1630 TPMS_DiagResponse_UUDT 0;
BA_ "GenSigTimeoutMsg_HU_Mid_X445" SG_ 1630 TPMS_DiagResponse_UUDT 0;
BA_ "GenSigTimeoutMsg_HU_High_X445" SG_ 1630 TPMS_DiagResponse_UUDT 0;
BA_ "GenSigSendType" SG_ 1630 TPMS_DiagResponse_UUDT 1;
BA_ "GenSigTimeoutMsg_HU_A" SG_ 1630 TPMS_DiagResponse_UUDT 0;
BA_ "GenSigTimeoutMsg_HU_B" SG_ 1630 TPMS_DiagResponse_UUDT 0;
BA_ "GenSigTimeoutMsg_HU_High_X451" SG_ 1630 TPMS_DiagResponse_UUDT 0;
BA_ "GenSigTimeoutMsg_HU_Mid_X451" SG_ 1630 TPMS_DiagResponse_UUDT 0;
BA_ "GenSigTimeoutTime_HU_A" SG_ 1630 TPMS_DiagResponse_UUDT 0;
BA_ "GenSigTimeoutTime_HU_B" SG_ 1630 TPMS_DiagResponse_UUDT 0;
BA_ "GenSigTimeoutTime_HU_High_X451" SG_ 1630 TPMS_DiagResponse_UUDT 0;
BA_ "GenSigTimeoutTime_HU_Mid_X451" SG_ 1630 TPMS_DiagResponse_UUDT 0;
BA_ "GenSigTimeoutTime_IVI" SG_ 1886 TPMS_DiagResponse_USDT 0;
BA_ "GenSigTimeoutMsg_IVI" SG_ 1886 TPMS_DiagResponse_USDT 0;
BA_ "GenSigTimeoutTime_HU_Mid_X445" SG_ 1886 TPMS_DiagResponse_USDT 0;
BA_ "GenSigTimeoutTime_HU_High_X445" SG_ 1886 TPMS_DiagResponse_USDT 0;
BA_ "GenSigTimeoutMsg_HU_Mid_X445" SG_ 1886 TPMS_DiagResponse_USDT 0;
BA_ "GenSigTimeoutMsg_HU_High_X445" SG_ 1886 TPMS_DiagResponse_USDT 0;
BA_ "GenSigSendType" SG_ 1886 TPMS_DiagResponse_USDT 1;
BA_ "GenSigTimeoutMsg_HU_A" SG_ 1886 TPMS_DiagResponse_USDT 0;
BA_ "GenSigTimeoutMsg_HU_B" SG_ 1886 TPMS_DiagResponse_USDT 0;
BA_ "GenSigTimeoutMsg_HU_High_X451" SG_ 1886 TPMS_DiagResponse_USDT 0;
BA_ "GenSigTimeoutMsg_HU_Mid_X451" SG_ 1886 TPMS_DiagResponse_USDT 0;
BA_ "GenSigTimeoutTime_HU_A" SG_ 1886 TPMS_DiagResponse_USDT 0;
BA_ "GenSigTimeoutTime_HU_B" SG_ 1886 TPMS_DiagResponse_USDT 0;
BA_ "GenSigTimeoutTime_HU_High_X451" SG_ 1886 TPMS_DiagResponse_USDT 0;
BA_ "GenSigTimeoutTime_HU_Mid_X451" SG_ 1886 TPMS_DiagResponse_USDT 0;
BA_ "GenSigTimeoutTime_IVI" SG_ 1878 TPMS_DiagRequest 0;
BA_ "GenSigTimeoutMsg_IVI" SG_ 1878 TPMS_DiagRequest 0;
BA_ "GenSigTimeoutTime_HU_Mid_X445" SG_ 1878 TPMS_DiagRequest 0;
BA_ "GenSigTimeoutTime_HU_High_X445" SG_ 1878 TPMS_DiagRequest 0;
BA_ "GenSigTimeoutMsg_HU_Mid_X445" SG_ 1878 TPMS_DiagRequest 0;
BA_ "GenSigTimeoutMsg_HU_High_X445" SG_ 1878 TPMS_DiagRequest 0;
BA_ "GenSigSendType" SG_ 1878 TPMS_DiagRequest 1;
BA_ "GenSigTimeoutMsg_HU_A" SG_ 1878 TPMS_DiagRequest 0;
BA_ "GenSigTimeoutMsg_HU_B" SG_ 1878 TPMS_DiagRequest 0;
BA_ "GenSigTimeoutMsg_HU_High_X451" SG_ 1878 TPMS_DiagRequest 0;
BA_ "GenSigTimeoutMsg_HU_Mid_X451" SG_ 1878 TPMS_DiagRequest 0;
BA_ "GenSigTimeoutTime_HU_A" SG_ 1878 TPMS_DiagRequest 0;
BA_ "GenSigTimeoutTime_HU_B" SG_ 1878 TPMS_DiagRequest 0;
BA_ "GenSigTimeoutTime_HU_High_X451" SG_ 1878 TPMS_DiagRequest 0;
BA_ "GenSigTimeoutTime_HU_Mid_X451" SG_ 1878 TPMS_DiagRequest 0;
BA_ "GenSigTimeoutTime_IVI" SG_ 1546 SRS_DiagResponse_UUDT 0;
BA_ "GenSigTimeoutMsg_IVI" SG_ 1546 SRS_DiagResponse_UUDT 0;
BA_ "GenSigTimeoutTime_HU_Mid_X445" SG_ 1546 SRS_DiagResponse_UUDT 0;
BA_ "GenSigTimeoutTime_HU_High_X445" SG_ 1546 SRS_DiagResponse_UUDT 0;
BA_ "GenSigTimeoutMsg_HU_Mid_X445" SG_ 1546 SRS_DiagResponse_UUDT 0;
BA_ "GenSigTimeoutMsg_HU_High_X445" SG_ 1546 SRS_DiagResponse_UUDT 0;
BA_ "GenSigSendType" SG_ 1546 SRS_DiagResponse_UUDT 1;
BA_ "GenSigTimeoutMsg_HU_A" SG_ 1546 SRS_DiagResponse_UUDT 0;
BA_ "GenSigTimeoutMsg_HU_B" SG_ 1546 SRS_DiagResponse_UUDT 0;
BA_ "GenSigTimeoutMsg_HU_High_X451" SG_ 1546 SRS_DiagResponse_UUDT 0;
BA_ "GenSigTimeoutMsg_HU_Mid_X451" SG_ 1546 SRS_DiagResponse_UUDT 0;
BA_ "GenSigTimeoutTime_HU_A" SG_ 1546 SRS_DiagResponse_UUDT 0;
BA_ "GenSigTimeoutTime_HU_B" SG_ 1546 SRS_DiagResponse_UUDT 0;
BA_ "GenSigTimeoutTime_HU_High_X451" SG_ 1546 SRS_DiagResponse_UUDT 0;
BA_ "GenSigTimeoutTime_HU_Mid_X451" SG_ 1546 SRS_DiagResponse_UUDT 0;
BA_ "GenSigTimeoutTime_IVI" SG_ 1802 SRS_DiagResponse_USDT 0;
BA_ "GenSigTimeoutMsg_IVI" SG_ 1802 SRS_DiagResponse_USDT 0;
BA_ "GenSigTimeoutTime_HU_Mid_X445" SG_ 1802 SRS_DiagResponse_USDT 0;
BA_ "GenSigTimeoutTime_HU_High_X445" SG_ 1802 SRS_DiagResponse_USDT 0;
BA_ "GenSigTimeoutMsg_HU_Mid_X445" SG_ 1802 SRS_DiagResponse_USDT 0;
BA_ "GenSigTimeoutMsg_HU_High_X445" SG_ 1802 SRS_DiagResponse_USDT 0;
BA_ "GenSigSendType" SG_ 1802 SRS_DiagResponse_USDT 1;
BA_ "GenSigTimeoutMsg_HU_A" SG_ 1802 SRS_DiagResponse_USDT 0;
BA_ "GenSigTimeoutMsg_HU_B" SG_ 1802 SRS_DiagResponse_USDT 0;
BA_ "GenSigTimeoutMsg_HU_High_X451" SG_ 1802 SRS_DiagResponse_USDT 0;
BA_ "GenSigTimeoutMsg_HU_Mid_X451" SG_ 1802 SRS_DiagResponse_USDT 0;
BA_ "GenSigTimeoutTime_HU_A" SG_ 1802 SRS_DiagResponse_USDT 0;
BA_ "GenSigTimeoutTime_HU_B" SG_ 1802 SRS_DiagResponse_USDT 0;
BA_ "GenSigTimeoutTime_HU_High_X451" SG_ 1802 SRS_DiagResponse_USDT 0;
BA_ "GenSigTimeoutTime_HU_Mid_X451" SG_ 1802 SRS_DiagResponse_USDT 0;
BA_ "GenSigTimeoutTime_IVI" SG_ 1794 SRS_DiagRequest 0;
BA_ "GenSigTimeoutMsg_IVI" SG_ 1794 SRS_DiagRequest 0;
BA_ "GenSigTimeoutTime_HU_Mid_X445" SG_ 1794 SRS_DiagRequest 0;
BA_ "GenSigTimeoutTime_HU_High_X445" SG_ 1794 SRS_DiagRequest 0;
BA_ "GenSigTimeoutMsg_HU_Mid_X445" SG_ 1794 SRS_DiagRequest 0;
BA_ "GenSigTimeoutMsg_HU_High_X445" SG_ 1794 SRS_DiagRequest 0;
BA_ "GenSigSendType" SG_ 1794 SRS_DiagRequest 1;
BA_ "GenSigTimeoutMsg_HU_A" SG_ 1794 SRS_DiagRequest 0;
BA_ "GenSigTimeoutMsg_HU_B" SG_ 1794 SRS_DiagRequest 0;
BA_ "GenSigTimeoutMsg_HU_High_X451" SG_ 1794 SRS_DiagRequest 0;
BA_ "GenSigTimeoutMsg_HU_Mid_X451" SG_ 1794 SRS_DiagRequest 0;
BA_ "GenSigTimeoutTime_HU_A" SG_ 1794 SRS_DiagRequest 0;
BA_ "GenSigTimeoutTime_HU_B" SG_ 1794 SRS_DiagRequest 0;
BA_ "GenSigTimeoutTime_HU_High_X451" SG_ 1794 SRS_DiagRequest 0;
BA_ "GenSigTimeoutTime_HU_Mid_X451" SG_ 1794 SRS_DiagRequest 0;
BA_ "GenSigTimeoutTime_IVI" SG_ 1610 SRR_DiagResponse_UUDT 0;
BA_ "GenSigTimeoutMsg_IVI" SG_ 1610 SRR_DiagResponse_UUDT 0;
BA_ "GenSigTimeoutTime_HU_Mid_X445" SG_ 1610 SRR_DiagResponse_UUDT 0;
BA_ "GenSigTimeoutTime_HU_High_X445" SG_ 1610 SRR_DiagResponse_UUDT 0;
BA_ "GenSigTimeoutMsg_HU_Mid_X445" SG_ 1610 SRR_DiagResponse_UUDT 0;
BA_ "GenSigTimeoutMsg_HU_High_X445" SG_ 1610 SRR_DiagResponse_UUDT 0;
BA_ "GenSigSendType" SG_ 1610 SRR_DiagResponse_UUDT 1;
BA_ "GenSigTimeoutMsg_HU_A" SG_ 1610 SRR_DiagResponse_UUDT 0;
BA_ "GenSigTimeoutMsg_HU_B" SG_ 1610 SRR_DiagResponse_UUDT 0;
BA_ "GenSigTimeoutMsg_HU_High_X451" SG_ 1610 SRR_DiagResponse_UUDT 0;
BA_ "GenSigTimeoutMsg_HU_Mid_X451" SG_ 1610 SRR_DiagResponse_UUDT 0;
BA_ "GenSigTimeoutTime_HU_A" SG_ 1610 SRR_DiagResponse_UUDT 0;
BA_ "GenSigTimeoutTime_HU_B" SG_ 1610 SRR_DiagResponse_UUDT 0;
BA_ "GenSigTimeoutTime_HU_High_X451" SG_ 1610 SRR_DiagResponse_UUDT 0;
BA_ "GenSigTimeoutTime_HU_Mid_X451" SG_ 1610 SRR_DiagResponse_UUDT 0;
BA_ "GenSigTimeoutTime_IVI" SG_ 1866 SRR_DiagResponse_USDT 0;
BA_ "GenSigTimeoutMsg_IVI" SG_ 1866 SRR_DiagResponse_USDT 0;
BA_ "GenSigTimeoutTime_HU_Mid_X445" SG_ 1866 SRR_DiagResponse_USDT 0;
BA_ "GenSigTimeoutTime_HU_High_X445" SG_ 1866 SRR_DiagResponse_USDT 0;
BA_ "GenSigTimeoutMsg_HU_Mid_X445" SG_ 1866 SRR_DiagResponse_USDT 0;
BA_ "GenSigTimeoutMsg_HU_High_X445" SG_ 1866 SRR_DiagResponse_USDT 0;
BA_ "GenSigSendType" SG_ 1866 SRR_DiagResponse_USDT 1;
BA_ "GenSigTimeoutMsg_HU_A" SG_ 1866 SRR_DiagResponse_USDT 0;
BA_ "GenSigTimeoutMsg_HU_B" SG_ 1866 SRR_DiagResponse_USDT 0;
BA_ "GenSigTimeoutMsg_HU_High_X451" SG_ 1866 SRR_DiagResponse_USDT 0;
BA_ "GenSigTimeoutMsg_HU_Mid_X451" SG_ 1866 SRR_DiagResponse_USDT 0;
BA_ "GenSigTimeoutTime_HU_A" SG_ 1866 SRR_DiagResponse_USDT 0;
BA_ "GenSigTimeoutTime_HU_B" SG_ 1866 SRR_DiagResponse_USDT 0;
BA_ "GenSigTimeoutTime_HU_High_X451" SG_ 1866 SRR_DiagResponse_USDT 0;
BA_ "GenSigTimeoutTime_HU_Mid_X451" SG_ 1866 SRR_DiagResponse_USDT 0;
BA_ "GenSigTimeoutTime_IVI" SG_ 1858 SRR_DiagRequest 0;
BA_ "GenSigTimeoutMsg_IVI" SG_ 1858 SRR_DiagRequest 0;
BA_ "GenSigTimeoutTime_HU_Mid_X445" SG_ 1858 SRR_DiagRequest 0;
BA_ "GenSigTimeoutTime_HU_High_X445" SG_ 1858 SRR_DiagRequest 0;
BA_ "GenSigTimeoutMsg_HU_Mid_X445" SG_ 1858 SRR_DiagRequest 0;
BA_ "GenSigTimeoutMsg_HU_High_X445" SG_ 1858 SRR_DiagRequest 0;
BA_ "GenSigSendType" SG_ 1858 SRR_DiagRequest 1;
BA_ "GenSigTimeoutMsg_HU_A" SG_ 1858 SRR_DiagRequest 0;
BA_ "GenSigTimeoutMsg_HU_B" SG_ 1858 SRR_DiagRequest 0;
BA_ "GenSigTimeoutMsg_HU_High_X451" SG_ 1858 SRR_DiagRequest 0;
BA_ "GenSigTimeoutMsg_HU_Mid_X451" SG_ 1858 SRR_DiagRequest 0;
BA_ "GenSigTimeoutTime_HU_A" SG_ 1858 SRR_DiagRequest 0;
BA_ "GenSigTimeoutTime_HU_B" SG_ 1858 SRR_DiagRequest 0;
BA_ "GenSigTimeoutTime_HU_High_X451" SG_ 1858 SRR_DiagRequest 0;
BA_ "GenSigTimeoutTime_HU_Mid_X451" SG_ 1858 SRR_DiagRequest 0;
BA_ "GenSigTimeoutTime_IVI" SG_ 1560 PEPS_DiagResponse_UUDT 0;
BA_ "GenSigTimeoutMsg_IVI" SG_ 1560 PEPS_DiagResponse_UUDT 0;
BA_ "GenSigTimeoutTime_HU_Mid_X445" SG_ 1560 PEPS_DiagResponse_UUDT 0;
BA_ "GenSigTimeoutTime_HU_High_X445" SG_ 1560 PEPS_DiagResponse_UUDT 0;
BA_ "GenSigTimeoutMsg_HU_Mid_X445" SG_ 1560 PEPS_DiagResponse_UUDT 0;
BA_ "GenSigTimeoutMsg_HU_High_X445" SG_ 1560 PEPS_DiagResponse_UUDT 0;
BA_ "GenSigSendType" SG_ 1560 PEPS_DiagResponse_UUDT 1;
BA_ "GenSigTimeoutMsg_HU_A" SG_ 1560 PEPS_DiagResponse_UUDT 0;
BA_ "GenSigTimeoutMsg_HU_B" SG_ 1560 PEPS_DiagResponse_UUDT 0;
BA_ "GenSigTimeoutMsg_HU_High_X451" SG_ 1560 PEPS_DiagResponse_UUDT 0;
BA_ "GenSigTimeoutMsg_HU_Mid_X451" SG_ 1560 PEPS_DiagResponse_UUDT 0;
BA_ "GenSigTimeoutTime_HU_A" SG_ 1560 PEPS_DiagResponse_UUDT 0;
BA_ "GenSigTimeoutTime_HU_B" SG_ 1560 PEPS_DiagResponse_UUDT 0;
BA_ "GenSigTimeoutTime_HU_High_X451" SG_ 1560 PEPS_DiagResponse_UUDT 0;
BA_ "GenSigTimeoutTime_HU_Mid_X451" SG_ 1560 PEPS_DiagResponse_UUDT 0;
BA_ "GenSigTimeoutTime_IVI" SG_ 1816 PEPS_DiagResponse_USDT 0;
BA_ "GenSigTimeoutMsg_IVI" SG_ 1816 PEPS_DiagResponse_USDT 0;
BA_ "GenSigTimeoutTime_HU_Mid_X445" SG_ 1816 PEPS_DiagResponse_USDT 0;
BA_ "GenSigTimeoutTime_HU_High_X445" SG_ 1816 PEPS_DiagResponse_USDT 0;
BA_ "GenSigTimeoutMsg_HU_Mid_X445" SG_ 1816 PEPS_DiagResponse_USDT 0;
BA_ "GenSigTimeoutMsg_HU_High_X445" SG_ 1816 PEPS_DiagResponse_USDT 0;
BA_ "GenSigSendType" SG_ 1816 PEPS_DiagResponse_USDT 1;
BA_ "GenSigTimeoutMsg_HU_A" SG_ 1816 PEPS_DiagResponse_USDT 0;
BA_ "GenSigTimeoutMsg_HU_B" SG_ 1816 PEPS_DiagResponse_USDT 0;
BA_ "GenSigTimeoutMsg_HU_High_X451" SG_ 1816 PEPS_DiagResponse_USDT 0;
BA_ "GenSigTimeoutMsg_HU_Mid_X451" SG_ 1816 PEPS_DiagResponse_USDT 0;
BA_ "GenSigTimeoutTime_HU_A" SG_ 1816 PEPS_DiagResponse_USDT 0;
BA_ "GenSigTimeoutTime_HU_B" SG_ 1816 PEPS_DiagResponse_USDT 0;
BA_ "GenSigTimeoutTime_HU_High_X451" SG_ 1816 PEPS_DiagResponse_USDT 0;
BA_ "GenSigTimeoutTime_HU_Mid_X451" SG_ 1816 PEPS_DiagResponse_USDT 0;
BA_ "GenSigTimeoutTime_IVI" SG_ 1808 PEPS_DiagRequest_USDT 0;
BA_ "GenSigTimeoutMsg_IVI" SG_ 1808 PEPS_DiagRequest_USDT 0;
BA_ "GenSigTimeoutTime_HU_Mid_X445" SG_ 1808 PEPS_DiagRequest_USDT 0;
BA_ "GenSigTimeoutTime_HU_High_X445" SG_ 1808 PEPS_DiagRequest_USDT 0;
BA_ "GenSigTimeoutMsg_HU_Mid_X445" SG_ 1808 PEPS_DiagRequest_USDT 0;
BA_ "GenSigTimeoutMsg_HU_High_X445" SG_ 1808 PEPS_DiagRequest_USDT 0;
BA_ "GenSigSendType" SG_ 1808 PEPS_DiagRequest_USDT 1;
BA_ "GenSigTimeoutMsg_HU_A" SG_ 1808 PEPS_DiagRequest_USDT 0;
BA_ "GenSigTimeoutMsg_HU_B" SG_ 1808 PEPS_DiagRequest_USDT 0;
BA_ "GenSigTimeoutMsg_HU_High_X451" SG_ 1808 PEPS_DiagRequest_USDT 0;
BA_ "GenSigTimeoutMsg_HU_Mid_X451" SG_ 1808 PEPS_DiagRequest_USDT 0;
BA_ "GenSigTimeoutTime_HU_A" SG_ 1808 PEPS_DiagRequest_USDT 0;
BA_ "GenSigTimeoutTime_HU_B" SG_ 1808 PEPS_DiagRequest_USDT 0;
BA_ "GenSigTimeoutTime_HU_High_X451" SG_ 1808 PEPS_DiagRequest_USDT 0;
BA_ "GenSigTimeoutTime_HU_Mid_X451" SG_ 1808 PEPS_DiagRequest_USDT 0;
BA_ "GenSigTimeoutTime_IVI" SG_ 1564 PDC_DiagResponse_UUDT 0;
BA_ "GenSigTimeoutMsg_IVI" SG_ 1564 PDC_DiagResponse_UUDT 0;
BA_ "GenSigTimeoutTime_HU_Mid_X445" SG_ 1564 PDC_DiagResponse_UUDT 0;
BA_ "GenSigTimeoutTime_HU_High_X445" SG_ 1564 PDC_DiagResponse_UUDT 0;
BA_ "GenSigTimeoutMsg_HU_Mid_X445" SG_ 1564 PDC_DiagResponse_UUDT 0;
BA_ "GenSigTimeoutMsg_HU_High_X445" SG_ 1564 PDC_DiagResponse_UUDT 0;
BA_ "GenSigSendType" SG_ 1564 PDC_DiagResponse_UUDT 1;
BA_ "GenSigTimeoutMsg_HU_A" SG_ 1564 PDC_DiagResponse_UUDT 0;
BA_ "GenSigTimeoutMsg_HU_B" SG_ 1564 PDC_DiagResponse_UUDT 0;
BA_ "GenSigTimeoutMsg_HU_High_X451" SG_ 1564 PDC_DiagResponse_UUDT 0;
BA_ "GenSigTimeoutMsg_HU_Mid_X451" SG_ 1564 PDC_DiagResponse_UUDT 0;
BA_ "GenSigTimeoutTime_HU_A" SG_ 1564 PDC_DiagResponse_UUDT 0;
BA_ "GenSigTimeoutTime_HU_B" SG_ 1564 PDC_DiagResponse_UUDT 0;
BA_ "GenSigTimeoutTime_HU_High_X451" SG_ 1564 PDC_DiagResponse_UUDT 0;
BA_ "GenSigTimeoutTime_HU_Mid_X451" SG_ 1564 PDC_DiagResponse_UUDT 0;
BA_ "GenSigTimeoutTime_IVI" SG_ 1820 PDC_DiagResponse_USDT 0;
BA_ "GenSigTimeoutMsg_IVI" SG_ 1820 PDC_DiagResponse_USDT 0;
BA_ "GenSigTimeoutTime_HU_Mid_X445" SG_ 1820 PDC_DiagResponse_USDT 0;
BA_ "GenSigTimeoutTime_HU_High_X445" SG_ 1820 PDC_DiagResponse_USDT 0;
BA_ "GenSigTimeoutMsg_HU_Mid_X445" SG_ 1820 PDC_DiagResponse_USDT 0;
BA_ "GenSigTimeoutMsg_HU_High_X445" SG_ 1820 PDC_DiagResponse_USDT 0;
BA_ "GenSigSendType" SG_ 1820 PDC_DiagResponse_USDT 1;
BA_ "GenSigTimeoutMsg_HU_A" SG_ 1820 PDC_DiagResponse_USDT 0;
BA_ "GenSigTimeoutMsg_HU_B" SG_ 1820 PDC_DiagResponse_USDT 0;
BA_ "GenSigTimeoutMsg_HU_High_X451" SG_ 1820 PDC_DiagResponse_USDT 0;
BA_ "GenSigTimeoutMsg_HU_Mid_X451" SG_ 1820 PDC_DiagResponse_USDT 0;
BA_ "GenSigTimeoutTime_HU_A" SG_ 1820 PDC_DiagResponse_USDT 0;
BA_ "GenSigTimeoutTime_HU_B" SG_ 1820 PDC_DiagResponse_USDT 0;
BA_ "GenSigTimeoutTime_HU_High_X451" SG_ 1820 PDC_DiagResponse_USDT 0;
BA_ "GenSigTimeoutTime_HU_Mid_X451" SG_ 1820 PDC_DiagResponse_USDT 0;
BA_ "GenSigTimeoutTime_IVI" SG_ 1812 PDC_DiagRequest 0;
BA_ "GenSigTimeoutMsg_IVI" SG_ 1812 PDC_DiagRequest 0;
BA_ "GenSigTimeoutTime_HU_Mid_X445" SG_ 1812 PDC_DiagRequest 0;
BA_ "GenSigTimeoutTime_HU_High_X445" SG_ 1812 PDC_DiagRequest 0;
BA_ "GenSigTimeoutMsg_HU_Mid_X445" SG_ 1812 PDC_DiagRequest 0;
BA_ "GenSigTimeoutMsg_HU_High_X445" SG_ 1812 PDC_DiagRequest 0;
BA_ "GenSigSendType" SG_ 1812 PDC_DiagRequest 1;
BA_ "GenSigTimeoutMsg_HU_A" SG_ 1812 PDC_DiagRequest 0;
BA_ "GenSigTimeoutMsg_HU_B" SG_ 1812 PDC_DiagRequest 0;
BA_ "GenSigTimeoutMsg_HU_High_X451" SG_ 1812 PDC_DiagRequest 0;
BA_ "GenSigTimeoutMsg_HU_Mid_X451" SG_ 1812 PDC_DiagRequest 0;
BA_ "GenSigTimeoutTime_HU_A" SG_ 1812 PDC_DiagRequest 0;
BA_ "GenSigTimeoutTime_HU_B" SG_ 1812 PDC_DiagRequest 0;
BA_ "GenSigTimeoutTime_HU_High_X451" SG_ 1812 PDC_DiagRequest 0;
BA_ "GenSigTimeoutTime_HU_Mid_X451" SG_ 1812 PDC_DiagRequest 0;
BA_ "GenSigTimeoutTime_IVI" SG_ 1608 FR_DiagResponse_UUDT 0;
BA_ "GenSigTimeoutMsg_IVI" SG_ 1608 FR_DiagResponse_UUDT 0;
BA_ "GenSigTimeoutTime_HU_Mid_X445" SG_ 1608 FR_DiagResponse_UUDT 0;
BA_ "GenSigTimeoutTime_HU_High_X445" SG_ 1608 FR_DiagResponse_UUDT 0;
BA_ "GenSigTimeoutMsg_HU_Mid_X445" SG_ 1608 FR_DiagResponse_UUDT 0;
BA_ "GenSigTimeoutMsg_HU_High_X445" SG_ 1608 FR_DiagResponse_UUDT 0;
BA_ "GenSigSendType" SG_ 1608 FR_DiagResponse_UUDT 1;
BA_ "GenSigTimeoutMsg_HU_A" SG_ 1608 FR_DiagResponse_UUDT 0;
BA_ "GenSigTimeoutMsg_HU_B" SG_ 1608 FR_DiagResponse_UUDT 0;
BA_ "GenSigTimeoutMsg_HU_High_X451" SG_ 1608 FR_DiagResponse_UUDT 0;
BA_ "GenSigTimeoutMsg_HU_Mid_X451" SG_ 1608 FR_DiagResponse_UUDT 0;
BA_ "GenSigTimeoutTime_HU_A" SG_ 1608 FR_DiagResponse_UUDT 0;
BA_ "GenSigTimeoutTime_HU_B" SG_ 1608 FR_DiagResponse_UUDT 0;
BA_ "GenSigTimeoutTime_HU_High_X451" SG_ 1608 FR_DiagResponse_UUDT 0;
BA_ "GenSigTimeoutTime_HU_Mid_X451" SG_ 1608 FR_DiagResponse_UUDT 0;
BA_ "GenSigTimeoutTime_IVI" SG_ 1864 FR_DiagResponse_USDT 0;
BA_ "GenSigTimeoutMsg_IVI" SG_ 1864 FR_DiagResponse_USDT 0;
BA_ "GenSigTimeoutTime_HU_Mid_X445" SG_ 1864 FR_DiagResponse_USDT 0;
BA_ "GenSigTimeoutTime_HU_High_X445" SG_ 1864 FR_DiagResponse_USDT 0;
BA_ "GenSigTimeoutMsg_HU_Mid_X445" SG_ 1864 FR_DiagResponse_USDT 0;
BA_ "GenSigTimeoutMsg_HU_High_X445" SG_ 1864 FR_DiagResponse_USDT 0;
BA_ "GenSigSendType" SG_ 1864 FR_DiagResponse_USDT 1;
BA_ "GenSigTimeoutMsg_HU_A" SG_ 1864 FR_DiagResponse_USDT 0;
BA_ "GenSigTimeoutMsg_HU_B" SG_ 1864 FR_DiagResponse_USDT 0;
BA_ "GenSigTimeoutMsg_HU_High_X451" SG_ 1864 FR_DiagResponse_USDT 0;
BA_ "GenSigTimeoutMsg_HU_Mid_X451" SG_ 1864 FR_DiagResponse_USDT 0;
BA_ "GenSigTimeoutTime_HU_A" SG_ 1864 FR_DiagResponse_USDT 0;
BA_ "GenSigTimeoutTime_HU_B" SG_ 1864 FR_DiagResponse_USDT 0;
BA_ "GenSigTimeoutTime_HU_High_X451" SG_ 1864 FR_DiagResponse_USDT 0;
BA_ "GenSigTimeoutTime_HU_Mid_X451" SG_ 1864 FR_DiagResponse_USDT 0;
BA_ "GenSigTimeoutTime_IVI" SG_ 1856 FR_DiagRequest 0;
BA_ "GenSigTimeoutMsg_IVI" SG_ 1856 FR_DiagRequest 0;
BA_ "GenSigTimeoutTime_HU_Mid_X445" SG_ 1856 FR_DiagRequest 0;
BA_ "GenSigTimeoutTime_HU_High_X445" SG_ 1856 FR_DiagRequest 0;
BA_ "GenSigTimeoutMsg_HU_Mid_X445" SG_ 1856 FR_DiagRequest 0;
BA_ "GenSigTimeoutMsg_HU_High_X445" SG_ 1856 FR_DiagRequest 0;
BA_ "GenSigSendType" SG_ 1856 FR_DiagRequest 1;
BA_ "GenSigTimeoutMsg_HU_A" SG_ 1856 FR_DiagRequest 0;
BA_ "GenSigTimeoutMsg_HU_B" SG_ 1856 FR_DiagRequest 0;
BA_ "GenSigTimeoutMsg_HU_High_X451" SG_ 1856 FR_DiagRequest 0;
BA_ "GenSigTimeoutMsg_HU_Mid_X451" SG_ 1856 FR_DiagRequest 0;
BA_ "GenSigTimeoutTime_HU_A" SG_ 1856 FR_DiagRequest 0;
BA_ "GenSigTimeoutTime_HU_B" SG_ 1856 FR_DiagRequest 0;
BA_ "GenSigTimeoutTime_HU_High_X451" SG_ 1856 FR_DiagRequest 0;
BA_ "GenSigTimeoutTime_HU_Mid_X451" SG_ 1856 FR_DiagRequest 0;
BA_ "GenSigTimeoutTime_IVI" SG_ 1609 FCM_DiagResponse_UUDT 0;
BA_ "GenSigTimeoutMsg_IVI" SG_ 1609 FCM_DiagResponse_UUDT 0;
BA_ "GenSigTimeoutTime_HU_Mid_X445" SG_ 1609 FCM_DiagResponse_UUDT 0;
BA_ "GenSigTimeoutTime_HU_High_X445" SG_ 1609 FCM_DiagResponse_UUDT 0;
BA_ "GenSigTimeoutMsg_HU_Mid_X445" SG_ 1609 FCM_DiagResponse_UUDT 0;
BA_ "GenSigTimeoutMsg_HU_High_X445" SG_ 1609 FCM_DiagResponse_UUDT 0;
BA_ "GenSigSendType" SG_ 1609 FCM_DiagResponse_UUDT 1;
BA_ "GenSigTimeoutMsg_HU_A" SG_ 1609 FCM_DiagResponse_UUDT 0;
BA_ "GenSigTimeoutMsg_HU_B" SG_ 1609 FCM_DiagResponse_UUDT 0;
BA_ "GenSigTimeoutMsg_HU_High_X451" SG_ 1609 FCM_DiagResponse_UUDT 0;
BA_ "GenSigTimeoutMsg_HU_Mid_X451" SG_ 1609 FCM_DiagResponse_UUDT 0;
BA_ "GenSigTimeoutTime_HU_A" SG_ 1609 FCM_DiagResponse_UUDT 0;
BA_ "GenSigTimeoutTime_HU_B" SG_ 1609 FCM_DiagResponse_UUDT 0;
BA_ "GenSigTimeoutTime_HU_High_X451" SG_ 1609 FCM_DiagResponse_UUDT 0;
BA_ "GenSigTimeoutTime_HU_Mid_X451" SG_ 1609 FCM_DiagResponse_UUDT 0;
BA_ "GenSigTimeoutTime_IVI" SG_ 1865 FCM_DiagResponse_USDT 0;
BA_ "GenSigTimeoutMsg_IVI" SG_ 1865 FCM_DiagResponse_USDT 0;
BA_ "GenSigTimeoutTime_HU_Mid_X445" SG_ 1865 FCM_DiagResponse_USDT 0;
BA_ "GenSigTimeoutTime_HU_High_X445" SG_ 1865 FCM_DiagResponse_USDT 0;
BA_ "GenSigTimeoutMsg_HU_Mid_X445" SG_ 1865 FCM_DiagResponse_USDT 0;
BA_ "GenSigTimeoutMsg_HU_High_X445" SG_ 1865 FCM_DiagResponse_USDT 0;
BA_ "GenSigSendType" SG_ 1865 FCM_DiagResponse_USDT 1;
BA_ "GenSigTimeoutMsg_HU_A" SG_ 1865 FCM_DiagResponse_USDT 0;
BA_ "GenSigTimeoutMsg_HU_B" SG_ 1865 FCM_DiagResponse_USDT 0;
BA_ "GenSigTimeoutMsg_HU_High_X451" SG_ 1865 FCM_DiagResponse_USDT 0;
BA_ "GenSigTimeoutMsg_HU_Mid_X451" SG_ 1865 FCM_DiagResponse_USDT 0;
BA_ "GenSigTimeoutTime_HU_A" SG_ 1865 FCM_DiagResponse_USDT 0;
BA_ "GenSigTimeoutTime_HU_B" SG_ 1865 FCM_DiagResponse_USDT 0;
BA_ "GenSigTimeoutTime_HU_High_X451" SG_ 1865 FCM_DiagResponse_USDT 0;
BA_ "GenSigTimeoutTime_HU_Mid_X451" SG_ 1865 FCM_DiagResponse_USDT 0;
BA_ "GenSigTimeoutTime_IVI" SG_ 1857 FCM_DiagRequest 0;
BA_ "GenSigTimeoutMsg_IVI" SG_ 1857 FCM_DiagRequest 0;
BA_ "GenSigTimeoutTime_HU_Mid_X445" SG_ 1857 FCM_DiagRequest 0;
BA_ "GenSigTimeoutTime_HU_High_X445" SG_ 1857 FCM_DiagRequest 0;
BA_ "GenSigTimeoutMsg_HU_Mid_X445" SG_ 1857 FCM_DiagRequest 0;
BA_ "GenSigTimeoutMsg_HU_High_X445" SG_ 1857 FCM_DiagRequest 0;
BA_ "GenSigSendType" SG_ 1857 FCM_DiagRequest 1;
BA_ "GenSigTimeoutMsg_HU_A" SG_ 1857 FCM_DiagRequest 0;
BA_ "GenSigTimeoutMsg_HU_B" SG_ 1857 FCM_DiagRequest 0;
BA_ "GenSigTimeoutMsg_HU_High_X451" SG_ 1857 FCM_DiagRequest 0;
BA_ "GenSigTimeoutMsg_HU_Mid_X451" SG_ 1857 FCM_DiagRequest 0;
BA_ "GenSigTimeoutTime_HU_A" SG_ 1857 FCM_DiagRequest 0;
BA_ "GenSigTimeoutTime_HU_B" SG_ 1857 FCM_DiagRequest 0;
BA_ "GenSigTimeoutTime_HU_High_X451" SG_ 1857 FCM_DiagRequest 0;
BA_ "GenSigTimeoutTime_HU_Mid_X451" SG_ 1857 FCM_DiagRequest 0;
BA_ "GenSigTimeoutTime_IVI" SG_ 1624 ESP_DiagResponse_UUDT 0;
BA_ "GenSigTimeoutMsg_IVI" SG_ 1624 ESP_DiagResponse_UUDT 0;
BA_ "GenSigTimeoutTime_HU_Mid_X445" SG_ 1624 ESP_DiagResponse_UUDT 0;
BA_ "GenSigTimeoutTime_HU_High_X445" SG_ 1624 ESP_DiagResponse_UUDT 0;
BA_ "GenSigTimeoutMsg_HU_Mid_X445" SG_ 1624 ESP_DiagResponse_UUDT 0;
BA_ "GenSigTimeoutMsg_HU_High_X445" SG_ 1624 ESP_DiagResponse_UUDT 0;
BA_ "GenSigSendType" SG_ 1624 ESP_DiagResponse_UUDT 1;
BA_ "GenSigTimeoutMsg_HU_A" SG_ 1624 ESP_DiagResponse_UUDT 0;
BA_ "GenSigTimeoutMsg_HU_B" SG_ 1624 ESP_DiagResponse_UUDT 0;
BA_ "GenSigTimeoutMsg_HU_High_X451" SG_ 1624 ESP_DiagResponse_UUDT 0;
BA_ "GenSigTimeoutMsg_HU_Mid_X451" SG_ 1624 ESP_DiagResponse_UUDT 0;
BA_ "GenSigTimeoutTime_HU_A" SG_ 1624 ESP_DiagResponse_UUDT 0;
BA_ "GenSigTimeoutTime_HU_B" SG_ 1624 ESP_DiagResponse_UUDT 0;
BA_ "GenSigTimeoutTime_HU_High_X451" SG_ 1624 ESP_DiagResponse_UUDT 0;
BA_ "GenSigTimeoutTime_HU_Mid_X451" SG_ 1624 ESP_DiagResponse_UUDT 0;
BA_ "GenSigTimeoutTime_IVI" SG_ 1880 ESP_DiagResponse_USDT 0;
BA_ "GenSigTimeoutMsg_IVI" SG_ 1880 ESP_DiagResponse_USDT 0;
BA_ "GenSigTimeoutTime_HU_Mid_X445" SG_ 1880 ESP_DiagResponse_USDT 0;
BA_ "GenSigTimeoutTime_HU_High_X445" SG_ 1880 ESP_DiagResponse_USDT 0;
BA_ "GenSigTimeoutMsg_HU_Mid_X445" SG_ 1880 ESP_DiagResponse_USDT 0;
BA_ "GenSigTimeoutMsg_HU_High_X445" SG_ 1880 ESP_DiagResponse_USDT 0;
BA_ "GenSigSendType" SG_ 1880 ESP_DiagResponse_USDT 1;
BA_ "GenSigTimeoutMsg_HU_A" SG_ 1880 ESP_DiagResponse_USDT 0;
BA_ "GenSigTimeoutMsg_HU_B" SG_ 1880 ESP_DiagResponse_USDT 0;
BA_ "GenSigTimeoutMsg_HU_High_X451" SG_ 1880 ESP_DiagResponse_USDT 0;
BA_ "GenSigTimeoutMsg_HU_Mid_X451" SG_ 1880 ESP_DiagResponse_USDT 0;
BA_ "GenSigTimeoutTime_HU_A" SG_ 1880 ESP_DiagResponse_USDT 0;
BA_ "GenSigTimeoutTime_HU_B" SG_ 1880 ESP_DiagResponse_USDT 0;
BA_ "GenSigTimeoutTime_HU_High_X451" SG_ 1880 ESP_DiagResponse_USDT 0;
BA_ "GenSigTimeoutTime_HU_Mid_X451" SG_ 1880 ESP_DiagResponse_USDT 0;
BA_ "GenSigTimeoutTime_IVI" SG_ 1872 ESP_DiagRequest 0;
BA_ "GenSigTimeoutMsg_IVI" SG_ 1872 ESP_DiagRequest 0;
BA_ "GenSigTimeoutTime_HU_Mid_X445" SG_ 1872 ESP_DiagRequest 0;
BA_ "GenSigTimeoutTime_HU_High_X445" SG_ 1872 ESP_DiagRequest 0;
BA_ "GenSigTimeoutMsg_HU_Mid_X445" SG_ 1872 ESP_DiagRequest 0;
BA_ "GenSigTimeoutMsg_HU_High_X445" SG_ 1872 ESP_DiagRequest 0;
BA_ "GenSigSendType" SG_ 1872 ESP_DiagRequest 1;
BA_ "GenSigTimeoutMsg_HU_A" SG_ 1872 ESP_DiagRequest 0;
BA_ "GenSigTimeoutMsg_HU_B" SG_ 1872 ESP_DiagRequest 0;
BA_ "GenSigTimeoutMsg_HU_High_X451" SG_ 1872 ESP_DiagRequest 0;
BA_ "GenSigTimeoutMsg_HU_Mid_X451" SG_ 1872 ESP_DiagRequest 0;
BA_ "GenSigTimeoutTime_HU_A" SG_ 1872 ESP_DiagRequest 0;
BA_ "GenSigTimeoutTime_HU_B" SG_ 1872 ESP_DiagRequest 0;
BA_ "GenSigTimeoutTime_HU_High_X451" SG_ 1872 ESP_DiagRequest 0;
BA_ "GenSigTimeoutTime_HU_Mid_X451" SG_ 1872 ESP_DiagRequest 0;
BA_ "GenSigTimeoutTime_IVI" SG_ 1884 ESCL_DiagResponse_USDT 0;
BA_ "GenSigTimeoutMsg_IVI" SG_ 1884 ESCL_DiagResponse_USDT 0;
BA_ "GenSigTimeoutTime_HU_Mid_X445" SG_ 1884 ESCL_DiagResponse_USDT 0;
BA_ "GenSigTimeoutTime_HU_High_X445" SG_ 1884 ESCL_DiagResponse_USDT 0;
BA_ "GenSigTimeoutMsg_HU_Mid_X445" SG_ 1884 ESCL_DiagResponse_USDT 0;
BA_ "GenSigTimeoutMsg_HU_High_X445" SG_ 1884 ESCL_DiagResponse_USDT 0;
BA_ "GenSigSendType" SG_ 1884 ESCL_DiagResponse_USDT 1;
BA_ "GenSigTimeoutMsg_HU_A" SG_ 1884 ESCL_DiagResponse_USDT 0;
BA_ "GenSigTimeoutMsg_HU_B" SG_ 1884 ESCL_DiagResponse_USDT 0;
BA_ "GenSigTimeoutMsg_HU_High_X451" SG_ 1884 ESCL_DiagResponse_USDT 0;
BA_ "GenSigTimeoutMsg_HU_Mid_X451" SG_ 1884 ESCL_DiagResponse_USDT 0;
BA_ "GenSigTimeoutTime_HU_A" SG_ 1884 ESCL_DiagResponse_USDT 0;
BA_ "GenSigTimeoutTime_HU_B" SG_ 1884 ESCL_DiagResponse_USDT 0;
BA_ "GenSigTimeoutTime_HU_High_X451" SG_ 1884 ESCL_DiagResponse_USDT 0;
BA_ "GenSigTimeoutTime_HU_Mid_X451" SG_ 1884 ESCL_DiagResponse_USDT 0;
BA_ "GenSigTimeoutTime_IVI" SG_ 1876 ESCL_DiagRequest 0;
BA_ "GenSigTimeoutMsg_IVI" SG_ 1876 ESCL_DiagRequest 0;
BA_ "GenSigTimeoutTime_HU_Mid_X445" SG_ 1876 ESCL_DiagRequest 0;
BA_ "GenSigTimeoutTime_HU_High_X445" SG_ 1876 ESCL_DiagRequest 0;
BA_ "GenSigTimeoutMsg_HU_Mid_X445" SG_ 1876 ESCL_DiagRequest 0;
BA_ "GenSigTimeoutMsg_HU_High_X445" SG_ 1876 ESCL_DiagRequest 0;
BA_ "GenSigSendType" SG_ 1876 ESCL_DiagRequest 1;
BA_ "GenSigTimeoutMsg_HU_A" SG_ 1876 ESCL_DiagRequest 0;
BA_ "GenSigTimeoutMsg_HU_B" SG_ 1876 ESCL_DiagRequest 0;
BA_ "GenSigTimeoutMsg_HU_High_X451" SG_ 1876 ESCL_DiagRequest 0;
BA_ "GenSigTimeoutMsg_HU_Mid_X451" SG_ 1876 ESCL_DiagRequest 0;
BA_ "GenSigTimeoutTime_HU_A" SG_ 1876 ESCL_DiagRequest 0;
BA_ "GenSigTimeoutTime_HU_B" SG_ 1876 ESCL_DiagRequest 0;
BA_ "GenSigTimeoutTime_HU_High_X451" SG_ 1876 ESCL_DiagRequest 0;
BA_ "GenSigTimeoutTime_HU_Mid_X451" SG_ 1876 ESCL_DiagRequest 0;
BA_ "GenSigTimeoutTime_IVI" SG_ 1626 EPAS_DiagResponse_UUDT 0;
BA_ "GenSigTimeoutMsg_IVI" SG_ 1626 EPAS_DiagResponse_UUDT 0;
BA_ "GenSigTimeoutTime_HU_Mid_X445" SG_ 1626 EPAS_DiagResponse_UUDT 0;
BA_ "GenSigTimeoutTime_HU_High_X445" SG_ 1626 EPAS_DiagResponse_UUDT 0;
BA_ "GenSigTimeoutMsg_HU_Mid_X445" SG_ 1626 EPAS_DiagResponse_UUDT 0;
BA_ "GenSigTimeoutMsg_HU_High_X445" SG_ 1626 EPAS_DiagResponse_UUDT 0;
BA_ "GenSigSendType" SG_ 1626 EPAS_DiagResponse_UUDT 1;
BA_ "GenSigTimeoutMsg_HU_A" SG_ 1626 EPAS_DiagResponse_UUDT 0;
BA_ "GenSigTimeoutMsg_HU_B" SG_ 1626 EPAS_DiagResponse_UUDT 0;
BA_ "GenSigTimeoutMsg_HU_High_X451" SG_ 1626 EPAS_DiagResponse_UUDT 0;
BA_ "GenSigTimeoutMsg_HU_Mid_X451" SG_ 1626 EPAS_DiagResponse_UUDT 0;
BA_ "GenSigTimeoutTime_HU_A" SG_ 1626 EPAS_DiagResponse_UUDT 0;
BA_ "GenSigTimeoutTime_HU_B" SG_ 1626 EPAS_DiagResponse_UUDT 0;
BA_ "GenSigTimeoutTime_HU_High_X451" SG_ 1626 EPAS_DiagResponse_UUDT 0;
BA_ "GenSigTimeoutTime_HU_Mid_X451" SG_ 1626 EPAS_DiagResponse_UUDT 0;
BA_ "GenSigTimeoutTime_IVI" SG_ 1882 EPAS_DiagResponse_USDT 0;
BA_ "GenSigTimeoutMsg_IVI" SG_ 1882 EPAS_DiagResponse_USDT 0;
BA_ "GenSigTimeoutTime_HU_Mid_X445" SG_ 1882 EPAS_DiagResponse_USDT 0;
BA_ "GenSigTimeoutTime_HU_High_X445" SG_ 1882 EPAS_DiagResponse_USDT 0;
BA_ "GenSigTimeoutMsg_HU_Mid_X445" SG_ 1882 EPAS_DiagResponse_USDT 0;
BA_ "GenSigTimeoutMsg_HU_High_X445" SG_ 1882 EPAS_DiagResponse_USDT 0;
BA_ "GenSigSendType" SG_ 1882 EPAS_DiagResponse_USDT 1;
BA_ "GenSigTimeoutMsg_HU_A" SG_ 1882 EPAS_DiagResponse_USDT 0;
BA_ "GenSigTimeoutMsg_HU_B" SG_ 1882 EPAS_DiagResponse_USDT 0;
BA_ "GenSigTimeoutMsg_HU_High_X451" SG_ 1882 EPAS_DiagResponse_USDT 0;
BA_ "GenSigTimeoutMsg_HU_Mid_X451" SG_ 1882 EPAS_DiagResponse_USDT 0;
BA_ "GenSigTimeoutTime_HU_A" SG_ 1882 EPAS_DiagResponse_USDT 0;
BA_ "GenSigTimeoutTime_HU_B" SG_ 1882 EPAS_DiagResponse_USDT 0;
BA_ "GenSigTimeoutTime_HU_High_X451" SG_ 1882 EPAS_DiagResponse_USDT 0;
BA_ "GenSigTimeoutTime_HU_Mid_X451" SG_ 1882 EPAS_DiagResponse_USDT 0;
BA_ "GenSigTimeoutTime_IVI" SG_ 1874 EPAS_DiagRequest 0;
BA_ "GenSigTimeoutMsg_IVI" SG_ 1874 EPAS_DiagRequest 0;
BA_ "GenSigTimeoutTime_HU_Mid_X445" SG_ 1874 EPAS_DiagRequest 0;
BA_ "GenSigTimeoutTime_HU_High_X445" SG_ 1874 EPAS_DiagRequest 0;
BA_ "GenSigTimeoutMsg_HU_Mid_X445" SG_ 1874 EPAS_DiagRequest 0;
BA_ "GenSigTimeoutMsg_HU_High_X445" SG_ 1874 EPAS_DiagRequest 0;
BA_ "GenSigSendType" SG_ 1874 EPAS_DiagRequest 1;
BA_ "GenSigTimeoutMsg_HU_A" SG_ 1874 EPAS_DiagRequest 0;
BA_ "GenSigTimeoutMsg_HU_B" SG_ 1874 EPAS_DiagRequest 0;
BA_ "GenSigTimeoutMsg_HU_High_X451" SG_ 1874 EPAS_DiagRequest 0;
BA_ "GenSigTimeoutMsg_HU_Mid_X451" SG_ 1874 EPAS_DiagRequest 0;
BA_ "GenSigTimeoutTime_HU_A" SG_ 1874 EPAS_DiagRequest 0;
BA_ "GenSigTimeoutTime_HU_B" SG_ 1874 EPAS_DiagRequest 0;
BA_ "GenSigTimeoutTime_HU_High_X451" SG_ 1874 EPAS_DiagRequest 0;
BA_ "GenSigTimeoutTime_HU_Mid_X451" SG_ 1874 EPAS_DiagRequest 0;
BA_ "GenSigTimeoutTime_IVI" SG_ 1549 CCM_DiagResponse_UUDT 0;
BA_ "GenSigTimeoutMsg_IVI" SG_ 1549 CCM_DiagResponse_UUDT 0;
BA_ "GenSigTimeoutTime_HU_Mid_X445" SG_ 1549 CCM_DiagResponse_UUDT 0;
BA_ "GenSigTimeoutTime_HU_High_X445" SG_ 1549 CCM_DiagResponse_UUDT 0;
BA_ "GenSigTimeoutMsg_HU_Mid_X445" SG_ 1549 CCM_DiagResponse_UUDT 0;
BA_ "GenSigTimeoutMsg_HU_High_X445" SG_ 1549 CCM_DiagResponse_UUDT 0;
BA_ "GenSigSendType" SG_ 1549 CCM_DiagResponse_UUDT 1;
BA_ "GenSigTimeoutMsg_HU_A" SG_ 1549 CCM_DiagResponse_UUDT 0;
BA_ "GenSigTimeoutMsg_HU_B" SG_ 1549 CCM_DiagResponse_UUDT 0;
BA_ "GenSigTimeoutMsg_HU_High_X451" SG_ 1549 CCM_DiagResponse_UUDT 0;
BA_ "GenSigTimeoutMsg_HU_Mid_X451" SG_ 1549 CCM_DiagResponse_UUDT 0;
BA_ "GenSigTimeoutTime_HU_A" SG_ 1549 CCM_DiagResponse_UUDT 0;
BA_ "GenSigTimeoutTime_HU_B" SG_ 1549 CCM_DiagResponse_UUDT 0;
BA_ "GenSigTimeoutTime_HU_High_X451" SG_ 1549 CCM_DiagResponse_UUDT 0;
BA_ "GenSigTimeoutTime_HU_Mid_X451" SG_ 1549 CCM_DiagResponse_UUDT 0;
BA_ "GenSigTimeoutTime_IVI" SG_ 1805 CCM_DiagResponse_USDT 0;
BA_ "GenSigTimeoutMsg_IVI" SG_ 1805 CCM_DiagResponse_USDT 0;
BA_ "GenSigTimeoutTime_HU_Mid_X445" SG_ 1805 CCM_DiagResponse_USDT 0;
BA_ "GenSigTimeoutTime_HU_High_X445" SG_ 1805 CCM_DiagResponse_USDT 0;
BA_ "GenSigTimeoutMsg_HU_Mid_X445" SG_ 1805 CCM_DiagResponse_USDT 0;
BA_ "GenSigTimeoutMsg_HU_High_X445" SG_ 1805 CCM_DiagResponse_USDT 0;
BA_ "GenSigSendType" SG_ 1805 CCM_DiagResponse_USDT 1;
BA_ "GenSigTimeoutMsg_HU_A" SG_ 1805 CCM_DiagResponse_USDT 0;
BA_ "GenSigTimeoutMsg_HU_B" SG_ 1805 CCM_DiagResponse_USDT 0;
BA_ "GenSigTimeoutMsg_HU_High_X451" SG_ 1805 CCM_DiagResponse_USDT 0;
BA_ "GenSigTimeoutMsg_HU_Mid_X451" SG_ 1805 CCM_DiagResponse_USDT 0;
BA_ "GenSigTimeoutTime_HU_A" SG_ 1805 CCM_DiagResponse_USDT 0;
BA_ "GenSigTimeoutTime_HU_B" SG_ 1805 CCM_DiagResponse_USDT 0;
BA_ "GenSigTimeoutTime_HU_High_X451" SG_ 1805 CCM_DiagResponse_USDT 0;
BA_ "GenSigTimeoutTime_HU_Mid_X451" SG_ 1805 CCM_DiagResponse_USDT 0;
BA_ "GenSigTimeoutTime_IVI" SG_ 1797 CCM_DiagRequest 0;
BA_ "GenSigTimeoutMsg_IVI" SG_ 1797 CCM_DiagRequest 0;
BA_ "GenSigTimeoutTime_HU_Mid_X445" SG_ 1797 CCM_DiagRequest 0;
BA_ "GenSigTimeoutTime_HU_High_X445" SG_ 1797 CCM_DiagRequest 0;
BA_ "GenSigTimeoutMsg_HU_Mid_X445" SG_ 1797 CCM_DiagRequest 0;
BA_ "GenSigTimeoutMsg_HU_High_X445" SG_ 1797 CCM_DiagRequest 0;
BA_ "GenSigSendType" SG_ 1797 CCM_DiagRequest 1;
BA_ "GenSigTimeoutMsg_HU_A" SG_ 1797 CCM_DiagRequest 0;
BA_ "GenSigTimeoutMsg_HU_B" SG_ 1797 CCM_DiagRequest 0;
BA_ "GenSigTimeoutMsg_HU_High_X451" SG_ 1797 CCM_DiagRequest 0;
BA_ "GenSigTimeoutMsg_HU_Mid_X451" SG_ 1797 CCM_DiagRequest 0;
BA_ "GenSigTimeoutTime_HU_A" SG_ 1797 CCM_DiagRequest 0;
BA_ "GenSigTimeoutTime_HU_B" SG_ 1797 CCM_DiagRequest 0;
BA_ "GenSigTimeoutTime_HU_High_X451" SG_ 1797 CCM_DiagRequest 0;
BA_ "GenSigTimeoutTime_HU_Mid_X451" SG_ 1797 CCM_DiagRequest 0;
BA_ "GenSigTimeoutTime_IVI" SG_ 1545 BCM_DiagResponse_UUDT 0;
BA_ "GenSigTimeoutMsg_IVI" SG_ 1545 BCM_DiagResponse_UUDT 0;
BA_ "GenSigTimeoutTime_HU_Mid_X445" SG_ 1545 BCM_DiagResponse_UUDT 0;
BA_ "GenSigTimeoutTime_HU_High_X445" SG_ 1545 BCM_DiagResponse_UUDT 0;
BA_ "GenSigTimeoutMsg_HU_Mid_X445" SG_ 1545 BCM_DiagResponse_UUDT 0;
BA_ "GenSigTimeoutMsg_HU_High_X445" SG_ 1545 BCM_DiagResponse_UUDT 0;
BA_ "GenSigSendType" SG_ 1545 BCM_DiagResponse_UUDT 1;
BA_ "GenSigTimeoutMsg_HU_A" SG_ 1545 BCM_DiagResponse_UUDT 0;
BA_ "GenSigTimeoutMsg_HU_B" SG_ 1545 BCM_DiagResponse_UUDT 0;
BA_ "GenSigTimeoutMsg_HU_High_X451" SG_ 1545 BCM_DiagResponse_UUDT 0;
BA_ "GenSigTimeoutMsg_HU_Mid_X451" SG_ 1545 BCM_DiagResponse_UUDT 0;
BA_ "GenSigTimeoutTime_HU_A" SG_ 1545 BCM_DiagResponse_UUDT 0;
BA_ "GenSigTimeoutTime_HU_B" SG_ 1545 BCM_DiagResponse_UUDT 0;
BA_ "GenSigTimeoutTime_HU_High_X451" SG_ 1545 BCM_DiagResponse_UUDT 0;
BA_ "GenSigTimeoutTime_HU_Mid_X451" SG_ 1545 BCM_DiagResponse_UUDT 0;
BA_ "GenSigTimeoutTime_IVI" SG_ 1801 BCM_DiagResponse_USDT 0;
BA_ "GenSigTimeoutMsg_IVI" SG_ 1801 BCM_DiagResponse_USDT 0;
BA_ "GenSigTimeoutTime_HU_Mid_X445" SG_ 1801 BCM_DiagResponse_USDT 0;
BA_ "GenSigTimeoutTime_HU_High_X445" SG_ 1801 BCM_DiagResponse_USDT 0;
BA_ "GenSigTimeoutMsg_HU_Mid_X445" SG_ 1801 BCM_DiagResponse_USDT 0;
BA_ "GenSigTimeoutMsg_HU_High_X445" SG_ 1801 BCM_DiagResponse_USDT 0;
BA_ "GenSigSendType" SG_ 1801 BCM_DiagResponse_USDT 1;
BA_ "GenSigTimeoutMsg_HU_A" SG_ 1801 BCM_DiagResponse_USDT 0;
BA_ "GenSigTimeoutMsg_HU_B" SG_ 1801 BCM_DiagResponse_USDT 0;
BA_ "GenSigTimeoutMsg_HU_High_X451" SG_ 1801 BCM_DiagResponse_USDT 0;
BA_ "GenSigTimeoutMsg_HU_Mid_X451" SG_ 1801 BCM_DiagResponse_USDT 0;
BA_ "GenSigTimeoutTime_HU_A" SG_ 1801 BCM_DiagResponse_USDT 0;
BA_ "GenSigTimeoutTime_HU_B" SG_ 1801 BCM_DiagResponse_USDT 0;
BA_ "GenSigTimeoutTime_HU_High_X451" SG_ 1801 BCM_DiagResponse_USDT 0;
BA_ "GenSigTimeoutTime_HU_Mid_X451" SG_ 1801 BCM_DiagResponse_USDT 0;
BA_ "GenSigTimeoutTime_IVI" SG_ 1793 BCM_DiagRequest 0;
BA_ "GenSigTimeoutMsg_IVI" SG_ 1793 BCM_DiagRequest 0;
BA_ "GenSigTimeoutTime_HU_Mid_X445" SG_ 1793 BCM_DiagRequest 0;
BA_ "GenSigTimeoutTime_HU_High_X445" SG_ 1793 BCM_DiagRequest 0;
BA_ "GenSigTimeoutMsg_HU_Mid_X445" SG_ 1793 BCM_DiagRequest 0;
BA_ "GenSigTimeoutMsg_HU_High_X445" SG_ 1793 BCM_DiagRequest 0;
BA_ "GenSigSendType" SG_ 1793 BCM_DiagRequest 1;
BA_ "GenSigTimeoutMsg_HU_A" SG_ 1793 BCM_DiagRequest 0;
BA_ "GenSigTimeoutMsg_HU_B" SG_ 1793 BCM_DiagRequest 0;
BA_ "GenSigTimeoutMsg_HU_High_X451" SG_ 1793 BCM_DiagRequest 0;
BA_ "GenSigTimeoutMsg_HU_Mid_X451" SG_ 1793 BCM_DiagRequest 0;
BA_ "GenSigTimeoutTime_HU_A" SG_ 1793 BCM_DiagRequest 0;
BA_ "GenSigTimeoutTime_HU_B" SG_ 1793 BCM_DiagRequest 0;
BA_ "GenSigTimeoutTime_HU_High_X451" SG_ 1793 BCM_DiagRequest 0;
BA_ "GenSigTimeoutTime_HU_Mid_X451" SG_ 1793 BCM_DiagRequest 0;
BA_ "GenSigCycleTime" SG_ 708 SbCurrentAudioSource 100;
BA_ "GenSigCycleTimeActive" SG_ 708 SbCurrentAudioSource 100;
BA_ "GenSigSendType" SG_ 708 SbCurrentAudioSource 7;
BA_ "GenSigCycleTime" SG_ 708 DispVariant 100;
BA_ "GenSigCycleTimeActive" SG_ 708 DispVariant 100;
BA_ "GenSigSendType" SG_ 708 DispVariant 7;
BA_ "GenSigCycleTime" SG_ 708 SbPowerModeConfig 100;
BA_ "GenSigCycleTimeActive" SG_ 708 SbPowerModeConfig 100;
BA_ "GenSigSendType" SG_ 708 SbPowerModeConfig 7;
BA_ "GenSigCycleTime" SG_ 708 SbCurrentPowerMode 100;
BA_ "GenSigCycleTimeActive" SG_ 708 SbCurrentPowerMode 100;
BA_ "GenSigSendType" SG_ 708 SbCurrentPowerMode 7;
BA_ "GenSigCycleTime" SG_ 708 BpVariant 100;
BA_ "GenSigCycleTimeActive" SG_ 708 BpVariant 100;
BA_ "GenSigSendType" SG_ 708 BpVariant 7;
BA_ "GenSigCycleTime" SG_ 708 DispCurrentPowerMode 100;
BA_ "GenSigCycleTimeActive" SG_ 708 DispCurrentPowerMode 100;
BA_ "GenSigSendType" SG_ 708 DispCurrentPowerMode 7;
BA_ "GenSigCycleTime" SG_ 708 BpCurrentPowerMode 100;
BA_ "GenSigCycleTimeActive" SG_ 708 BpCurrentPowerMode 100;
BA_ "GenSigSendType" SG_ 708 BpCurrentPowerMode 7;
BA_ "GenSigCycleTime" SG_ 708 BpPresence 100;
BA_ "GenSigCycleTimeActive" SG_ 708 BpPresence 100;
BA_ "GenSigSendType" SG_ 708 BpPresence 7;
BA_ "GenSigCycleTime" SG_ 708 BattVoltSb 100;
BA_ "GenSigCycleTimeActive" SG_ 708 BattVoltSb 100;
BA_ "GenSigSendType" SG_ 708 BattVoltSb 7;
BA_ "GenSigStartValue" SG_ 708 BattVoltSb 120;
BA_ "GenSigCycleTime" SG_ 708 DispPresence 100;
BA_ "GenSigCycleTimeActive" SG_ 708 DispPresence 100;
BA_ "GenSigSendType" SG_ 708 DispPresence 7;
BA_ "GenSigTimeoutTime_HU_Mid_X451" SG_ 1109 AvasOnOffSettingState 0;
BA_ "GenSigTimeoutTime_HU_High_X451" SG_ 1109 AvasOnOffSettingState 0;
BA_ "GenSigTimeoutTime_HU_B" SG_ 1109 AvasOnOffSettingState 0;
BA_ "GenSigTimeoutTime_HU_A" SG_ 1109 AvasOnOffSettingState 0;
BA_ "GenSigTimeoutMsg_HU_Mid_X451" SG_ 1109 AvasOnOffSettingState 0;
BA_ "GenSigTimeoutMsg_HU_High_X451" SG_ 1109 AvasOnOffSettingState 0;
BA_ "GenSigTimeoutMsg_HU_B" SG_ 1109 AvasOnOffSettingState 0;
BA_ "GenSigTimeoutMsg_HU_A" SG_ 1109 AvasOnOffSettingState 0;
BA_ "GenSigSendType" SG_ 1109 AvasOnOffSettingState 2;
BA_ "GenSigTimeoutMsg_HU_High_X445" SG_ 1109 AvasOnOffSettingState 0;
BA_ "GenSigTimeoutMsg_HU_Mid_X445" SG_ 1109 AvasOnOffSettingState 0;
BA_ "GenSigTimeoutTime_HU_High_X445" SG_ 1109 AvasOnOffSettingState 0;
BA_ "GenSigTimeoutTime_HU_Mid_X445" SG_ 1109 AvasOnOffSettingState 0;
BA_ "GenSigTimeoutMsg_IVI" SG_ 1109 AvasOnOffSettingState 0;
BA_ "GenSigTimeoutTime_IVI" SG_ 1109 AvasOnOffSettingState 0;
BA_ "GenSigTimeoutTime_HU_Mid_X451" SG_ 1109 AvasOnOffSettingPresence 0;
BA_ "GenSigTimeoutTime_HU_High_X451" SG_ 1109 AvasOnOffSettingPresence 0;
BA_ "GenSigTimeoutTime_HU_B" SG_ 1109 AvasOnOffSettingPresence 0;
BA_ "GenSigTimeoutTime_HU_A" SG_ 1109 AvasOnOffSettingPresence 0;
BA_ "GenSigTimeoutMsg_HU_Mid_X451" SG_ 1109 AvasOnOffSettingPresence 0;
BA_ "GenSigTimeoutMsg_HU_High_X451" SG_ 1109 AvasOnOffSettingPresence 0;
BA_ "GenSigTimeoutMsg_HU_B" SG_ 1109 AvasOnOffSettingPresence 0;
BA_ "GenSigTimeoutMsg_HU_A" SG_ 1109 AvasOnOffSettingPresence 0;
BA_ "GenSigSendType" SG_ 1109 AvasOnOffSettingPresence 2;
BA_ "GenSigTimeoutMsg_HU_High_X445" SG_ 1109 AvasOnOffSettingPresence 0;
BA_ "GenSigTimeoutMsg_HU_Mid_X445" SG_ 1109 AvasOnOffSettingPresence 0;
BA_ "GenSigTimeoutTime_HU_High_X445" SG_ 1109 AvasOnOffSettingPresence 0;
BA_ "GenSigTimeoutTime_HU_Mid_X445" SG_ 1109 AvasOnOffSettingPresence 0;
BA_ "GenSigTimeoutMsg_IVI" SG_ 1109 AvasOnOffSettingPresence 0;
BA_ "GenSigTimeoutTime_IVI" SG_ 1109 AvasOnOffSettingPresence 0;
BA_ "GenSigTimeoutTime_HU_Mid_X451" SG_ 1126 AvasOnOffSettingPresenceAck 0;
BA_ "GenSigTimeoutTime_HU_High_X451" SG_ 1126 AvasOnOffSettingPresenceAck 0;
BA_ "GenSigTimeoutTime_HU_B" SG_ 1126 AvasOnOffSettingPresenceAck 0;
BA_ "GenSigTimeoutTime_HU_A" SG_ 1126 AvasOnOffSettingPresenceAck 0;
BA_ "GenSigTimeoutMsg_HU_Mid_X451" SG_ 1126 AvasOnOffSettingPresenceAck 0;
BA_ "GenSigTimeoutMsg_HU_High_X451" SG_ 1126 AvasOnOffSettingPresenceAck 0;
BA_ "GenSigTimeoutMsg_HU_B" SG_ 1126 AvasOnOffSettingPresenceAck 0;
BA_ "GenSigTimeoutMsg_HU_A" SG_ 1126 AvasOnOffSettingPresenceAck 0;
BA_ "GenSigSendType" SG_ 1126 AvasOnOffSettingPresenceAck 2;
BA_ "GenSigTimeoutMsg_HU_High_X445" SG_ 1126 AvasOnOffSettingPresenceAck 0;
BA_ "GenSigTimeoutMsg_HU_Mid_X445" SG_ 1126 AvasOnOffSettingPresenceAck 0;
BA_ "GenSigTimeoutTime_HU_High_X445" SG_ 1126 AvasOnOffSettingPresenceAck 0;
BA_ "GenSigTimeoutTime_HU_Mid_X445" SG_ 1126 AvasOnOffSettingPresenceAck 0;
BA_ "GenSigTimeoutMsg_IVI" SG_ 1126 AvasOnOffSettingPresenceAck 0;
BA_ "GenSigTimeoutTime_IVI" SG_ 1126 AvasOnOffSettingPresenceAck 0;
BA_ "GenSigTimeoutTime_HU_Mid_X451" SG_ 1126 AvasOnOffSettinStateAck 0;
BA_ "GenSigTimeoutTime_HU_High_X451" SG_ 1126 AvasOnOffSettinStateAck 0;
BA_ "GenSigTimeoutTime_HU_B" SG_ 1126 AvasOnOffSettinStateAck 0;
BA_ "GenSigTimeoutTime_HU_A" SG_ 1126 AvasOnOffSettinStateAck 0;
BA_ "GenSigTimeoutMsg_HU_Mid_X451" SG_ 1126 AvasOnOffSettinStateAck 0;
BA_ "GenSigTimeoutMsg_HU_High_X451" SG_ 1126 AvasOnOffSettinStateAck 0;
BA_ "GenSigTimeoutMsg_HU_B" SG_ 1126 AvasOnOffSettinStateAck 0;
BA_ "GenSigTimeoutMsg_HU_A" SG_ 1126 AvasOnOffSettinStateAck 0;
BA_ "GenSigSendType" SG_ 1126 AvasOnOffSettinStateAck 2;
BA_ "GenSigTimeoutMsg_HU_High_X445" SG_ 1126 AvasOnOffSettinStateAck 0;
BA_ "GenSigTimeoutMsg_HU_Mid_X445" SG_ 1126 AvasOnOffSettinStateAck 0;
BA_ "GenSigTimeoutTime_HU_High_X445" SG_ 1126 AvasOnOffSettinStateAck 0;
BA_ "GenSigTimeoutTime_HU_Mid_X445" SG_ 1126 AvasOnOffSettinStateAck 0;
BA_ "GenSigTimeoutMsg_IVI" SG_ 1126 AvasOnOffSettinStateAck 0;
BA_ "GenSigTimeoutTime_IVI" SG_ 1126 AvasOnOffSettinStateAck 0;
BA_ "GenSigTimeoutTime_HU_Mid_X451" SG_ 1126 AvasOnOffSettingChangeReq 0;
BA_ "GenSigTimeoutTime_HU_High_X451" SG_ 1126 AvasOnOffSettingChangeReq 0;
BA_ "GenSigTimeoutTime_HU_B" SG_ 1126 AvasOnOffSettingChangeReq 0;
BA_ "GenSigTimeoutTime_HU_A" SG_ 1126 AvasOnOffSettingChangeReq 0;
BA_ "GenSigTimeoutMsg_HU_Mid_X451" SG_ 1126 AvasOnOffSettingChangeReq 0;
BA_ "GenSigTimeoutMsg_HU_High_X451" SG_ 1126 AvasOnOffSettingChangeReq 0;
BA_ "GenSigTimeoutMsg_HU_B" SG_ 1126 AvasOnOffSettingChangeReq 0;
BA_ "GenSigTimeoutMsg_HU_A" SG_ 1126 AvasOnOffSettingChangeReq 0;
BA_ "GenSigSendType" SG_ 1126 AvasOnOffSettingChangeReq 2;
BA_ "GenSigTimeoutMsg_HU_High_X445" SG_ 1126 AvasOnOffSettingChangeReq 0;
BA_ "GenSigTimeoutMsg_HU_Mid_X445" SG_ 1126 AvasOnOffSettingChangeReq 0;
BA_ "GenSigTimeoutTime_HU_High_X445" SG_ 1126 AvasOnOffSettingChangeReq 0;
BA_ "GenSigTimeoutTime_HU_Mid_X445" SG_ 1126 AvasOnOffSettingChangeReq 0;
BA_ "GenSigTimeoutMsg_IVI" SG_ 1126 AvasOnOffSettingChangeReq 0;
BA_ "GenSigTimeoutTime_IVI" SG_ 1126 AvasOnOffSettingChangeReq 0;
BA_ "GenSigTimeoutTime_HU_Mid_X451" SG_ 945 VehicleKeyType 2500;
BA_ "GenSigTimeoutTime_HU_High_X451" SG_ 945 VehicleKeyType 2500;
BA_ "GenSigTimeoutTime_HU_B" SG_ 945 VehicleKeyType 2500;
BA_ "GenSigTimeoutTime_HU_A" SG_ 945 VehicleKeyType 2500;
BA_ "GenSigTimeoutMsg_HU_Mid_X451" SG_ 945 VehicleKeyType 2500;
BA_ "GenSigTimeoutMsg_HU_High_X451" SG_ 945 VehicleKeyType 2500;
BA_ "GenSigTimeoutMsg_HU_B" SG_ 945 VehicleKeyType 2500;
BA_ "GenSigTimeoutMsg_HU_A" SG_ 945 VehicleKeyType 2500;
BA_ "GenSigSendType" SG_ 945 VehicleKeyType 7;
BA_ "GenSigCycleTimeActive" SG_ 945 VehicleKeyType 500;
BA_ "GenSigCycleTime" SG_ 945 VehicleKeyType 500;
BA_ "GenSigTimeoutMsg_HU_High_X445" SG_ 945 VehicleKeyType 2500;
BA_ "GenSigTimeoutMsg_HU_Mid_X445" SG_ 945 VehicleKeyType 2500;
BA_ "GenSigTimeoutTime_HU_High_X445" SG_ 945 VehicleKeyType 2500;
BA_ "GenSigTimeoutTime_HU_Mid_X445" SG_ 945 VehicleKeyType 2500;
BA_ "GenSigTimeoutMsg_IVI" SG_ 945 VehicleKeyType 2500;
BA_ "GenSigTimeoutTime_IVI" SG_ 945 VehicleKeyType 2500;
BA_ "GenSigTimeoutTime_HU_Mid_X451" SG_ 535 CplHuSclSettingUpdateAck 0;
BA_ "GenSigTimeoutTime_HU_High_X451" SG_ 535 CplHuSclSettingUpdateAck 0;
BA_ "GenSigTimeoutTime_HU_B" SG_ 535 CplHuSclSettingUpdateAck 0;
BA_ "GenSigTimeoutTime_HU_A" SG_ 535 CplHuSclSettingUpdateAck 0;
BA_ "GenSigTimeoutMsg_HU_Mid_X451" SG_ 535 CplHuSclSettingUpdateAck 0;
BA_ "GenSigTimeoutMsg_HU_High_X451" SG_ 535 CplHuSclSettingUpdateAck 0;
BA_ "GenSigTimeoutMsg_HU_B" SG_ 535 CplHuSclSettingUpdateAck 0;
BA_ "GenSigTimeoutMsg_HU_A" SG_ 535 CplHuSclSettingUpdateAck 0;
BA_ "GenSigSendType" SG_ 535 CplHuSclSettingUpdateAck 2;
BA_ "GenSigTimeoutMsg_HU_High_X445" SG_ 535 CplHuSclSettingUpdateAck 0;
BA_ "GenSigTimeoutMsg_HU_Mid_X445" SG_ 535 CplHuSclSettingUpdateAck 0;
BA_ "GenSigTimeoutTime_HU_High_X445" SG_ 535 CplHuSclSettingUpdateAck 0;
BA_ "GenSigTimeoutTime_HU_Mid_X445" SG_ 535 CplHuSclSettingUpdateAck 0;
BA_ "GenSigTimeoutMsg_IVI" SG_ 535 CplHuSclSettingUpdateAck 0;
BA_ "GenSigTimeoutTime_IVI" SG_ 535 CplHuSclSettingUpdateAck 0;
BA_ "GenSigSendType" SG_ 754 CplPresence 7;
BA_ "GenSigCycleTimeActive" SG_ 754 CplPresence 100;
BA_ "GenSigCycleTime" SG_ 754 CplPresence 100;
BA_ "GenSigSendType" SG_ 754 CplHuSclTimerConfigState 7;
BA_ "GenSigCycleTimeActive" SG_ 754 CplHuSclTimerConfigState 100;
BA_ "GenSigCycleTime" SG_ 754 CplHuSclTimerConfigState 100;
BA_ "GenSigSendType" SG_ 754 CplHuSclPresence 7;
BA_ "GenSigCycleTimeActive" SG_ 754 CplHuSclPresence 100;
BA_ "GenSigCycleTime" SG_ 754 CplHuSclPresence 100;
BA_ "GenSigSendType" SG_ 754 CplHuSclOnOffConfigState 7;
BA_ "GenSigCycleTimeActive" SG_ 754 CplHuSclOnOffConfigState 100;
BA_ "GenSigCycleTime" SG_ 754 CplHuSclOnOffConfigState 100;
BA_ "GenSigSendType" SG_ 756 VCuHuChargeLimitPresence 7;
BA_ "GenSigCycleTimeActive" SG_ 756 VCuHuChargeLimitPresence 100;
BA_ "GenSigCycleTime" SG_ 756 VCuHuChargeLimitPresence 100;
BA_ "GenSigSendType" SG_ 756 VCuCurrentDcChargeLimit 7;
BA_ "GenSigCycleTimeActive" SG_ 756 VCuCurrentDcChargeLimit 100;
BA_ "GenSigCycleTime" SG_ 756 VCuCurrentDcChargeLimit 100;
BA_ "GenSigSendType" SG_ 756 VCuCurrentAcChargeLimit 7;
BA_ "GenSigCycleTimeActive" SG_ 756 VCuCurrentAcChargeLimit 100;
BA_ "GenSigCycleTime" SG_ 756 VCuCurrentAcChargeLimit 100;
BA_ "GenSigSendType" SG_ 756 HVChargerConnectedStatus_VCAN 7;
BA_ "GenSigCycleTimeActive" SG_ 756 HVChargerConnectedStatus_VCAN 100;
BA_ "GenSigCycleTime" SG_ 756 HVChargerConnectedStatus_VCAN 100;
BA_ "GenSigSendType" SG_ 756 HVChargerConnected_VCAN 7;
BA_ "GenSigCycleTimeActive" SG_ 756 HVChargerConnected_VCAN 100;
BA_ "GenSigCycleTime" SG_ 756 HVChargerConnected_VCAN 100;
BA_ "GenSigSendType" SG_ 756 VCUSlowChrgshtdnStatus_VCAN 7;
BA_ "GenSigCycleTimeActive" SG_ 756 VCUSlowChrgshtdnStatus_VCAN 100;
BA_ "GenSigCycleTime" SG_ 756 VCUSlowChrgshtdnStatus_VCAN 100;
BA_ "GenSigSendType" SG_ 756 VCUSlowChrgshtdn_VCAN 7;
BA_ "GenSigCycleTimeActive" SG_ 756 VCUSlowChrgshtdn_VCAN 100;
BA_ "GenSigCycleTime" SG_ 756 VCUSlowChrgshtdn_VCAN 100;
BA_ "GenSigSendType" SG_ 756 VCUFastChrgshtdnStatus_VCAN 7;
BA_ "GenSigCycleTimeActive" SG_ 756 VCUFastChrgshtdnStatus_VCAN 100;
BA_ "GenSigCycleTime" SG_ 756 VCUFastChrgshtdnStatus_VCAN 100;
BA_ "GenSigSendType" SG_ 756 VCUFastChrgshtdn_VCAN 7;
BA_ "GenSigCycleTimeActive" SG_ 756 VCUFastChrgshtdn_VCAN 100;
BA_ "GenSigCycleTime" SG_ 756 VCUFastChrgshtdn_VCAN 100;
BA_ "GenSigSendType" SG_ 756 VCUChargingRateStatus_VCAN 7;
BA_ "GenSigCycleTimeActive" SG_ 756 VCUChargingRateStatus_VCAN 100;
BA_ "GenSigCycleTime" SG_ 756 VCUChargingRateStatus_VCAN 100;
BA_ "GenSigSendType" SG_ 756 VCUChargingRate_VCAN 7;
BA_ "GenSigCycleTimeActive" SG_ 756 VCUChargingRate_VCAN 100;
BA_ "GenSigCycleTime" SG_ 756 VCUChargingRate_VCAN 100;
BA_ "GenSigSendType" SG_ 753 HudPresence 7;
BA_ "GenSigCycleTimeActive" SG_ 753 HudPresence 100;
BA_ "GenSigCycleTime" SG_ 753 HudPresence 100;
BA_ "GenSigSendType" SG_ 753 HudFeaturePresence 7;
BA_ "GenSigCycleTimeActive" SG_ 753 HudFeaturePresence 100;
BA_ "GenSigCycleTime" SG_ 753 HudFeaturePresence 100;
BA_ "GenSigSendType" SG_ 382 VCUGSAPositionDisplay 7;
BA_ "GenSigCycleTimeActive" SG_ 382 VCUGSAPositionDisplay 20;
BA_ "GenSigCycleTime" SG_ 382 VCUGSAPositionDisplay 20;
BA_ "GenSigTimeoutTime_HU_Mid_X451" SG_ 529 VCuHuChargeLimitValueAck 0;
BA_ "GenSigTimeoutTime_HU_High_X451" SG_ 529 VCuHuChargeLimitValueAck 0;
BA_ "GenSigTimeoutTime_HU_B" SG_ 529 VCuHuChargeLimitValueAck 0;
BA_ "GenSigTimeoutTime_HU_A" SG_ 529 VCuHuChargeLimitValueAck 0;
BA_ "GenSigTimeoutMsg_HU_Mid_X451" SG_ 529 VCuHuChargeLimitValueAck 0;
BA_ "GenSigTimeoutMsg_HU_High_X451" SG_ 529 VCuHuChargeLimitValueAck 0;
BA_ "GenSigTimeoutMsg_HU_B" SG_ 529 VCuHuChargeLimitValueAck 0;
BA_ "GenSigTimeoutMsg_HU_A" SG_ 529 VCuHuChargeLimitValueAck 0;
BA_ "GenSigSendType" SG_ 529 VCuHuChargeLimitValueAck 2;
BA_ "GenSigTimeoutMsg_HU_High_X445" SG_ 529 VCuHuChargeLimitValueAck 0;
BA_ "GenSigTimeoutMsg_HU_Mid_X445" SG_ 529 VCuHuChargeLimitValueAck 0;
BA_ "GenSigTimeoutTime_HU_High_X445" SG_ 529 VCuHuChargeLimitValueAck 0;
BA_ "GenSigTimeoutTime_HU_Mid_X445" SG_ 529 VCuHuChargeLimitValueAck 0;
BA_ "GenSigTimeoutMsg_IVI" SG_ 529 VCuHuChargeLimitValueAck 0;
BA_ "GenSigTimeoutTime_IVI" SG_ 529 VCuHuChargeLimitValueAck 0;
BA_ "Remarks" SG_ 529 DischargingSOCLimitAck "null*";
BA_ "GenSigTimeoutTime_HU_Mid_X451" SG_ 529 DischargingSOCLimitAck 0;
BA_ "GenSigTimeoutTime_HU_High_X451" SG_ 529 DischargingSOCLimitAck 0;
BA_ "GenSigTimeoutTime_HU_B" SG_ 529 DischargingSOCLimitAck 0;
BA_ "GenSigTimeoutTime_HU_A" SG_ 529 DischargingSOCLimitAck 0;
BA_ "GenSigTimeoutMsg_HU_Mid_X451" SG_ 529 DischargingSOCLimitAck 0;
BA_ "GenSigTimeoutMsg_HU_High_X451" SG_ 529 DischargingSOCLimitAck 0;
BA_ "GenSigTimeoutMsg_HU_B" SG_ 529 DischargingSOCLimitAck 0;
BA_ "GenSigTimeoutMsg_HU_A" SG_ 529 DischargingSOCLimitAck 0;
BA_ "GenSigSendType" SG_ 529 DischargingSOCLimitAck 2;
BA_ "GenSigTimeoutMsg_HU_High_X445" SG_ 529 DischargingSOCLimitAck 0;
BA_ "GenSigTimeoutMsg_HU_Mid_X445" SG_ 529 DischargingSOCLimitAck 0;
BA_ "GenSigTimeoutTime_HU_High_X445" SG_ 529 DischargingSOCLimitAck 0;
BA_ "GenSigTimeoutTime_HU_Mid_X445" SG_ 529 DischargingSOCLimitAck 0;
BA_ "GenSigTimeoutMsg_IVI" SG_ 529 DischargingSOCLimitAck 0;
BA_ "GenSigTimeoutTime_IVI" SG_ 529 DischargingSOCLimitAck 0;
BA_ "Remarks" SG_ 528 DischargeSOClimitcmd "null*";
BA_ "GenSigTimeoutTime_HU_Mid_X451" SG_ 528 DischargeSOClimitcmd 0;
BA_ "GenSigTimeoutTime_HU_High_X451" SG_ 528 DischargeSOClimitcmd 0;
BA_ "GenSigTimeoutTime_HU_B" SG_ 528 DischargeSOClimitcmd 0;
BA_ "GenSigTimeoutTime_HU_A" SG_ 528 DischargeSOClimitcmd 0;
BA_ "GenSigTimeoutMsg_HU_Mid_X451" SG_ 528 DischargeSOClimitcmd 0;
BA_ "GenSigTimeoutMsg_HU_High_X451" SG_ 528 DischargeSOClimitcmd 0;
BA_ "GenSigTimeoutMsg_HU_B" SG_ 528 DischargeSOClimitcmd 0;
BA_ "GenSigTimeoutMsg_HU_A" SG_ 528 DischargeSOClimitcmd 0;
BA_ "GenSigSendType" SG_ 528 DischargeSOClimitcmd 2;
BA_ "GenSigTimeoutMsg_HU_High_X445" SG_ 528 DischargeSOClimitcmd 0;
BA_ "GenSigTimeoutMsg_HU_Mid_X445" SG_ 528 DischargeSOClimitcmd 0;
BA_ "GenSigTimeoutTime_HU_High_X445" SG_ 528 DischargeSOClimitcmd 0;
BA_ "GenSigTimeoutTime_HU_Mid_X445" SG_ 528 DischargeSOClimitcmd 0;
BA_ "GenSigTimeoutMsg_IVI" SG_ 528 DischargeSOClimitcmd 0;
BA_ "GenSigTimeoutTime_IVI" SG_ 528 DischargeSOClimitcmd 0;
BA_ "Remarks" SG_ 528 DischargeSOClimit "null*";
BA_ "GenSigTimeoutTime_HU_Mid_X451" SG_ 528 DischargeSOClimit 0;
BA_ "GenSigTimeoutTime_HU_High_X451" SG_ 528 DischargeSOClimit 0;
BA_ "GenSigTimeoutTime_HU_B" SG_ 528 DischargeSOClimit 0;
BA_ "GenSigTimeoutTime_HU_A" SG_ 528 DischargeSOClimit 0;
BA_ "GenSigTimeoutMsg_HU_Mid_X451" SG_ 528 DischargeSOClimit 0;
BA_ "GenSigTimeoutMsg_HU_High_X451" SG_ 528 DischargeSOClimit 0;
BA_ "GenSigTimeoutMsg_HU_B" SG_ 528 DischargeSOClimit 0;
BA_ "GenSigTimeoutMsg_HU_A" SG_ 528 DischargeSOClimit 0;
BA_ "GenSigStartValue" SG_ 528 DischargeSOClimit 30;
BA_ "GenSigSendType" SG_ 528 DischargeSOClimit 2;
BA_ "GenSigTimeoutMsg_HU_High_X445" SG_ 528 DischargeSOClimit 0;
BA_ "GenSigTimeoutMsg_HU_Mid_X445" SG_ 528 DischargeSOClimit 0;
BA_ "GenSigTimeoutTime_HU_High_X445" SG_ 528 DischargeSOClimit 0;
BA_ "GenSigTimeoutTime_HU_Mid_X445" SG_ 528 DischargeSOClimit 0;
BA_ "GenSigTimeoutMsg_IVI" SG_ 528 DischargeSOClimit 0;
BA_ "GenSigTimeoutTime_IVI" SG_ 528 DischargeSOClimit 0;
BA_ "GenSigTimeoutTime_HU_Mid_X451" SG_ 528 AVAsFeaturePreviewReq 0;
BA_ "GenSigTimeoutTime_HU_High_X451" SG_ 528 AVAsFeaturePreviewReq 0;
BA_ "GenSigTimeoutTime_HU_B" SG_ 528 AVAsFeaturePreviewReq 0;
BA_ "GenSigTimeoutTime_HU_A" SG_ 528 AVAsFeaturePreviewReq 0;
BA_ "GenSigTimeoutMsg_HU_Mid_X451" SG_ 528 AVAsFeaturePreviewReq 0;
BA_ "GenSigTimeoutMsg_HU_High_X451" SG_ 528 AVAsFeaturePreviewReq 0;
BA_ "GenSigTimeoutMsg_HU_B" SG_ 528 AVAsFeaturePreviewReq 0;
BA_ "GenSigTimeoutMsg_HU_A" SG_ 528 AVAsFeaturePreviewReq 0;
BA_ "GenSigSendType" SG_ 528 AVAsFeaturePreviewReq 2;
BA_ "GenSigTimeoutMsg_HU_High_X445" SG_ 528 AVAsFeaturePreviewReq 0;
BA_ "GenSigTimeoutMsg_HU_Mid_X445" SG_ 528 AVAsFeaturePreviewReq 0;
BA_ "GenSigTimeoutTime_HU_High_X445" SG_ 528 AVAsFeaturePreviewReq 0;
BA_ "GenSigTimeoutTime_HU_Mid_X445" SG_ 528 AVAsFeaturePreviewReq 0;
BA_ "GenSigTimeoutMsg_IVI" SG_ 528 AVAsFeaturePreviewReq 0;
BA_ "GenSigTimeoutTime_IVI" SG_ 528 AVAsFeaturePreviewReq 0;
BA_ "GenSigTimeoutTime_HU_Mid_X451" SG_ 528 SoundSigSettingStateAck 0;
BA_ "GenSigTimeoutTime_HU_High_X451" SG_ 528 SoundSigSettingStateAck 0;
BA_ "GenSigTimeoutTime_HU_B" SG_ 528 SoundSigSettingStateAck 0;
BA_ "GenSigTimeoutTime_HU_A" SG_ 528 SoundSigSettingStateAck 0;
BA_ "GenSigTimeoutMsg_HU_Mid_X451" SG_ 528 SoundSigSettingStateAck 0;
BA_ "GenSigTimeoutMsg_HU_High_X451" SG_ 528 SoundSigSettingStateAck 0;
BA_ "GenSigTimeoutMsg_HU_B" SG_ 528 SoundSigSettingStateAck 0;
BA_ "GenSigTimeoutMsg_HU_A" SG_ 528 SoundSigSettingStateAck 0;
BA_ "GenSigSendType" SG_ 528 SoundSigSettingStateAck 2;
BA_ "GenSigTimeoutMsg_HU_High_X445" SG_ 528 SoundSigSettingStateAck 0;
BA_ "GenSigTimeoutMsg_HU_Mid_X445" SG_ 528 SoundSigSettingStateAck 0;
BA_ "GenSigTimeoutTime_HU_High_X445" SG_ 528 SoundSigSettingStateAck 0;
BA_ "GenSigTimeoutTime_HU_Mid_X445" SG_ 528 SoundSigSettingStateAck 0;
BA_ "GenSigTimeoutMsg_IVI" SG_ 528 SoundSigSettingStateAck 0;
BA_ "GenSigTimeoutTime_IVI" SG_ 528 SoundSigSettingStateAck 0;
BA_ "GenSigTimeoutTime_HU_Mid_X451" SG_ 528 SoundSigSettingPresenceAck 0;
BA_ "GenSigTimeoutTime_HU_High_X451" SG_ 528 SoundSigSettingPresenceAck 0;
BA_ "GenSigTimeoutTime_HU_B" SG_ 528 SoundSigSettingPresenceAck 0;
BA_ "GenSigTimeoutTime_HU_A" SG_ 528 SoundSigSettingPresenceAck 0;
BA_ "GenSigTimeoutMsg_HU_Mid_X451" SG_ 528 SoundSigSettingPresenceAck 0;
BA_ "GenSigTimeoutMsg_HU_High_X451" SG_ 528 SoundSigSettingPresenceAck 0;
BA_ "GenSigTimeoutMsg_HU_B" SG_ 528 SoundSigSettingPresenceAck 0;
BA_ "GenSigTimeoutMsg_HU_A" SG_ 528 SoundSigSettingPresenceAck 0;
BA_ "GenSigSendType" SG_ 528 SoundSigSettingPresenceAck 2;
BA_ "GenSigTimeoutMsg_HU_High_X445" SG_ 528 SoundSigSettingPresenceAck 0;
BA_ "GenSigTimeoutMsg_HU_Mid_X445" SG_ 528 SoundSigSettingPresenceAck 0;
BA_ "GenSigTimeoutTime_HU_High_X445" SG_ 528 SoundSigSettingPresenceAck 0;
BA_ "GenSigTimeoutTime_HU_Mid_X445" SG_ 528 SoundSigSettingPresenceAck 0;
BA_ "GenSigTimeoutMsg_IVI" SG_ 528 SoundSigSettingPresenceAck 0;
BA_ "GenSigTimeoutTime_IVI" SG_ 528 SoundSigSettingPresenceAck 0;
BA_ "GenSigTimeoutTime_HU_Mid_X451" SG_ 528 ChargingSettingChangeReq 0;
BA_ "GenSigTimeoutTime_HU_High_X451" SG_ 528 ChargingSettingChangeReq 0;
BA_ "GenSigTimeoutTime_HU_B" SG_ 528 ChargingSettingChangeReq 0;
BA_ "GenSigTimeoutTime_HU_A" SG_ 528 ChargingSettingChangeReq 0;
BA_ "GenSigTimeoutMsg_HU_Mid_X451" SG_ 528 ChargingSettingChangeReq 0;
BA_ "GenSigTimeoutMsg_HU_High_X451" SG_ 528 ChargingSettingChangeReq 0;
BA_ "GenSigTimeoutMsg_HU_B" SG_ 528 ChargingSettingChangeReq 0;
BA_ "GenSigTimeoutMsg_HU_A" SG_ 528 ChargingSettingChangeReq 0;
BA_ "GenSigSendType" SG_ 528 ChargingSettingChangeReq 2;
BA_ "GenSigTimeoutMsg_HU_High_X445" SG_ 528 ChargingSettingChangeReq 0;
BA_ "GenSigTimeoutMsg_HU_Mid_X445" SG_ 528 ChargingSettingChangeReq 0;
BA_ "GenSigTimeoutTime_HU_High_X445" SG_ 528 ChargingSettingChangeReq 0;
BA_ "GenSigTimeoutTime_HU_Mid_X445" SG_ 528 ChargingSettingChangeReq 0;
BA_ "GenSigTimeoutMsg_IVI" SG_ 528 ChargingSettingChangeReq 0;
BA_ "GenSigTimeoutTime_IVI" SG_ 528 ChargingSettingChangeReq 0;
BA_ "GenSigTimeoutTime_HU_Mid_X451" SG_ 528 V2XSoundSettingStateAck 0;
BA_ "GenSigTimeoutTime_HU_High_X451" SG_ 528 V2XSoundSettingStateAck 0;
BA_ "GenSigTimeoutTime_HU_B" SG_ 528 V2XSoundSettingStateAck 0;
BA_ "GenSigTimeoutTime_HU_A" SG_ 528 V2XSoundSettingStateAck 0;
BA_ "GenSigTimeoutMsg_HU_Mid_X451" SG_ 528 V2XSoundSettingStateAck 0;
BA_ "GenSigTimeoutMsg_HU_High_X451" SG_ 528 V2XSoundSettingStateAck 0;
BA_ "GenSigTimeoutMsg_HU_B" SG_ 528 V2XSoundSettingStateAck 0;
BA_ "GenSigTimeoutMsg_HU_A" SG_ 528 V2XSoundSettingStateAck 0;
BA_ "GenSigSendType" SG_ 528 V2XSoundSettingStateAck 2;
BA_ "GenSigTimeoutMsg_HU_High_X445" SG_ 528 V2XSoundSettingStateAck 0;
BA_ "GenSigTimeoutMsg_HU_Mid_X445" SG_ 528 V2XSoundSettingStateAck 0;
BA_ "GenSigTimeoutTime_HU_High_X445" SG_ 528 V2XSoundSettingStateAck 0;
BA_ "GenSigTimeoutTime_HU_Mid_X445" SG_ 528 V2XSoundSettingStateAck 0;
BA_ "GenSigTimeoutMsg_IVI" SG_ 528 V2XSoundSettingStateAck 0;
BA_ "GenSigTimeoutTime_IVI" SG_ 528 V2XSoundSettingStateAck 0;
BA_ "GenSigTimeoutTime_HU_Mid_X451" SG_ 528 V2XSettingChangeReq 0;
BA_ "GenSigTimeoutTime_HU_High_X451" SG_ 528 V2XSettingChangeReq 0;
BA_ "GenSigTimeoutTime_HU_B" SG_ 528 V2XSettingChangeReq 0;
BA_ "GenSigTimeoutTime_HU_A" SG_ 528 V2XSettingChangeReq 0;
BA_ "GenSigTimeoutMsg_HU_Mid_X451" SG_ 528 V2XSettingChangeReq 0;
BA_ "GenSigTimeoutMsg_HU_High_X451" SG_ 528 V2XSettingChangeReq 0;
BA_ "GenSigTimeoutMsg_HU_B" SG_ 528 V2XSettingChangeReq 0;
BA_ "GenSigTimeoutMsg_HU_A" SG_ 528 V2XSettingChangeReq 0;
BA_ "GenSigSendType" SG_ 528 V2XSettingChangeReq 2;
BA_ "GenSigTimeoutMsg_HU_High_X445" SG_ 528 V2XSettingChangeReq 0;
BA_ "GenSigTimeoutMsg_HU_Mid_X445" SG_ 528 V2XSettingChangeReq 0;
BA_ "GenSigTimeoutTime_HU_High_X445" SG_ 528 V2XSettingChangeReq 0;
BA_ "GenSigTimeoutTime_HU_Mid_X445" SG_ 528 V2XSettingChangeReq 0;
BA_ "GenSigTimeoutMsg_IVI" SG_ 528 V2XSettingChangeReq 0;
BA_ "GenSigTimeoutTime_IVI" SG_ 528 V2XSettingChangeReq 0;
BA_ "GenSigTimeoutTime_HU_Mid_X451" SG_ 528 V2XEventPresenceAck 0;
BA_ "GenSigTimeoutTime_HU_High_X451" SG_ 528 V2XEventPresenceAck 0;
BA_ "GenSigTimeoutTime_HU_B" SG_ 528 V2XEventPresenceAck 0;
BA_ "GenSigTimeoutTime_HU_A" SG_ 528 V2XEventPresenceAck 0;
BA_ "GenSigTimeoutMsg_HU_Mid_X451" SG_ 528 V2XEventPresenceAck 0;
BA_ "GenSigTimeoutMsg_HU_High_X451" SG_ 528 V2XEventPresenceAck 0;
BA_ "GenSigTimeoutMsg_HU_B" SG_ 528 V2XEventPresenceAck 0;
BA_ "GenSigTimeoutMsg_HU_A" SG_ 528 V2XEventPresenceAck 0;
BA_ "GenSigSendType" SG_ 528 V2XEventPresenceAck 2;
BA_ "GenSigTimeoutMsg_HU_High_X445" SG_ 528 V2XEventPresenceAck 0;
BA_ "GenSigTimeoutMsg_HU_Mid_X445" SG_ 528 V2XEventPresenceAck 0;
BA_ "GenSigTimeoutTime_HU_High_X445" SG_ 528 V2XEventPresenceAck 0;
BA_ "GenSigTimeoutTime_HU_Mid_X445" SG_ 528 V2XEventPresenceAck 0;
BA_ "GenSigTimeoutMsg_IVI" SG_ 528 V2XEventPresenceAck 0;
BA_ "GenSigTimeoutTime_IVI" SG_ 528 V2XEventPresenceAck 0;
BA_ "GenSigTimeoutTime_HU_Mid_X451" SG_ 528 SndSyncDriveModeChangeReq 0;
BA_ "GenSigTimeoutTime_HU_High_X451" SG_ 528 SndSyncDriveModeChangeReq 0;
BA_ "GenSigTimeoutTime_HU_B" SG_ 528 SndSyncDriveModeChangeReq 0;
BA_ "GenSigTimeoutTime_HU_A" SG_ 528 SndSyncDriveModeChangeReq 0;
BA_ "GenSigTimeoutMsg_HU_Mid_X451" SG_ 528 SndSyncDriveModeChangeReq 0;
BA_ "GenSigTimeoutMsg_HU_High_X451" SG_ 528 SndSyncDriveModeChangeReq 0;
BA_ "GenSigTimeoutMsg_HU_B" SG_ 528 SndSyncDriveModeChangeReq 0;
BA_ "GenSigTimeoutMsg_HU_A" SG_ 528 SndSyncDriveModeChangeReq 0;
BA_ "GenSigSendType" SG_ 528 SndSyncDriveModeChangeReq 2;
BA_ "GenSigTimeoutMsg_HU_High_X445" SG_ 528 SndSyncDriveModeChangeReq 0;
BA_ "GenSigTimeoutMsg_HU_Mid_X445" SG_ 528 SndSyncDriveModeChangeReq 0;
BA_ "GenSigTimeoutTime_HU_High_X445" SG_ 528 SndSyncDriveModeChangeReq 0;
BA_ "GenSigTimeoutTime_HU_Mid_X445" SG_ 528 SndSyncDriveModeChangeReq 0;
BA_ "GenSigTimeoutMsg_IVI" SG_ 528 SndSyncDriveModeChangeReq 0;
BA_ "GenSigTimeoutTime_IVI" SG_ 528 SndSyncDriveModeChangeReq 0;
BA_ "GenSigTimeoutTime_HU_Mid_X451" SG_ 528 SoundSigSettingChangeReq 0;
BA_ "GenSigTimeoutTime_HU_High_X451" SG_ 528 SoundSigSettingChangeReq 0;
BA_ "GenSigTimeoutTime_HU_B" SG_ 528 SoundSigSettingChangeReq 0;
BA_ "GenSigTimeoutTime_HU_A" SG_ 528 SoundSigSettingChangeReq 0;
BA_ "GenSigTimeoutMsg_HU_Mid_X451" SG_ 528 SoundSigSettingChangeReq 0;
BA_ "GenSigTimeoutMsg_HU_High_X451" SG_ 528 SoundSigSettingChangeReq 0;
BA_ "GenSigTimeoutMsg_HU_B" SG_ 528 SoundSigSettingChangeReq 0;
BA_ "GenSigTimeoutMsg_HU_A" SG_ 528 SoundSigSettingChangeReq 0;
BA_ "GenSigSendType" SG_ 528 SoundSigSettingChangeReq 2;
BA_ "GenSigTimeoutMsg_HU_High_X445" SG_ 528 SoundSigSettingChangeReq 0;
BA_ "GenSigTimeoutMsg_HU_Mid_X445" SG_ 528 SoundSigSettingChangeReq 0;
BA_ "GenSigTimeoutTime_HU_High_X445" SG_ 528 SoundSigSettingChangeReq 0;
BA_ "GenSigTimeoutTime_HU_Mid_X445" SG_ 528 SoundSigSettingChangeReq 0;
BA_ "GenSigTimeoutMsg_IVI" SG_ 528 SoundSigSettingChangeReq 0;
BA_ "GenSigTimeoutTime_IVI" SG_ 528 SoundSigSettingChangeReq 0;
BA_ "GenSigTimeoutTime_HU_Mid_X451" SG_ 528 CrankSettingChangeReq 0;
BA_ "GenSigTimeoutTime_HU_High_X451" SG_ 528 CrankSettingChangeReq 0;
BA_ "GenSigTimeoutTime_HU_B" SG_ 528 CrankSettingChangeReq 0;
BA_ "GenSigTimeoutTime_HU_A" SG_ 528 CrankSettingChangeReq 0;
BA_ "GenSigTimeoutMsg_HU_Mid_X451" SG_ 528 CrankSettingChangeReq 0;
BA_ "GenSigTimeoutMsg_HU_High_X451" SG_ 528 CrankSettingChangeReq 0;
BA_ "GenSigTimeoutMsg_HU_B" SG_ 528 CrankSettingChangeReq 0;
BA_ "GenSigTimeoutMsg_HU_A" SG_ 528 CrankSettingChangeReq 0;
BA_ "GenSigSendType" SG_ 528 CrankSettingChangeReq 2;
BA_ "GenSigTimeoutMsg_HU_High_X445" SG_ 528 CrankSettingChangeReq 0;
BA_ "GenSigTimeoutMsg_HU_Mid_X445" SG_ 528 CrankSettingChangeReq 0;
BA_ "GenSigTimeoutTime_HU_High_X445" SG_ 528 CrankSettingChangeReq 0;
BA_ "GenSigTimeoutTime_HU_Mid_X445" SG_ 528 CrankSettingChangeReq 0;
BA_ "GenSigTimeoutMsg_IVI" SG_ 528 CrankSettingChangeReq 0;
BA_ "GenSigTimeoutTime_IVI" SG_ 528 CrankSettingChangeReq 0;
BA_ "GenSigTimeoutTime_HU_Mid_X451" SG_ 528 LockUnlockSettingChangeReq 0;
BA_ "GenSigTimeoutTime_HU_High_X451" SG_ 528 LockUnlockSettingChangeReq 0;
BA_ "GenSigTimeoutTime_HU_B" SG_ 528 LockUnlockSettingChangeReq 0;
BA_ "GenSigTimeoutTime_HU_A" SG_ 528 LockUnlockSettingChangeReq 0;
BA_ "GenSigTimeoutMsg_HU_Mid_X451" SG_ 528 LockUnlockSettingChangeReq 0;
BA_ "GenSigTimeoutMsg_HU_High_X451" SG_ 528 LockUnlockSettingChangeReq 0;
BA_ "GenSigTimeoutMsg_HU_B" SG_ 528 LockUnlockSettingChangeReq 0;
BA_ "GenSigTimeoutMsg_HU_A" SG_ 528 LockUnlockSettingChangeReq 0;
BA_ "GenSigSendType" SG_ 528 LockUnlockSettingChangeReq 2;
BA_ "GenSigTimeoutMsg_HU_High_X445" SG_ 528 LockUnlockSettingChangeReq 0;
BA_ "GenSigTimeoutMsg_HU_Mid_X445" SG_ 528 LockUnlockSettingChangeReq 0;
BA_ "GenSigTimeoutTime_HU_High_X445" SG_ 528 LockUnlockSettingChangeReq 0;
BA_ "GenSigTimeoutTime_HU_Mid_X445" SG_ 528 LockUnlockSettingChangeReq 0;
BA_ "GenSigTimeoutMsg_IVI" SG_ 528 LockUnlockSettingChangeReq 0;
BA_ "GenSigTimeoutTime_IVI" SG_ 528 LockUnlockSettingChangeReq 0;
BA_ "GenSigTimeoutTime_HU_Mid_X451" SG_ 528 ActiveExtSettingChangeReq 0;
BA_ "GenSigTimeoutTime_HU_High_X451" SG_ 528 ActiveExtSettingChangeReq 0;
BA_ "GenSigTimeoutTime_HU_B" SG_ 528 ActiveExtSettingChangeReq 0;
BA_ "GenSigTimeoutTime_HU_A" SG_ 528 ActiveExtSettingChangeReq 0;
BA_ "GenSigTimeoutMsg_HU_Mid_X451" SG_ 528 ActiveExtSettingChangeReq 0;
BA_ "GenSigTimeoutMsg_HU_High_X451" SG_ 528 ActiveExtSettingChangeReq 0;
BA_ "GenSigTimeoutMsg_HU_B" SG_ 528 ActiveExtSettingChangeReq 0;
BA_ "GenSigTimeoutMsg_HU_A" SG_ 528 ActiveExtSettingChangeReq 0;
BA_ "GenSigSendType" SG_ 528 ActiveExtSettingChangeReq 2;
BA_ "GenSigTimeoutMsg_HU_High_X445" SG_ 528 ActiveExtSettingChangeReq 0;
BA_ "GenSigTimeoutMsg_HU_Mid_X445" SG_ 528 ActiveExtSettingChangeReq 0;
BA_ "GenSigTimeoutTime_HU_High_X445" SG_ 528 ActiveExtSettingChangeReq 0;
BA_ "GenSigTimeoutTime_HU_Mid_X445" SG_ 528 ActiveExtSettingChangeReq 0;
BA_ "GenSigTimeoutMsg_IVI" SG_ 528 ActiveExtSettingChangeReq 0;
BA_ "GenSigTimeoutTime_IVI" SG_ 528 ActiveExtSettingChangeReq 0;
BA_ "GenSigTimeoutTime_HU_Mid_X451" SG_ 528 HuAVAsReqType 0;
BA_ "GenSigTimeoutTime_HU_High_X451" SG_ 528 HuAVAsReqType 0;
BA_ "GenSigTimeoutTime_HU_B" SG_ 528 HuAVAsReqType 0;
BA_ "GenSigTimeoutTime_HU_A" SG_ 528 HuAVAsReqType 0;
BA_ "GenSigTimeoutMsg_HU_Mid_X451" SG_ 528 HuAVAsReqType 0;
BA_ "GenSigTimeoutMsg_HU_High_X451" SG_ 528 HuAVAsReqType 0;
BA_ "GenSigTimeoutMsg_HU_B" SG_ 528 HuAVAsReqType 0;
BA_ "GenSigTimeoutMsg_HU_A" SG_ 528 HuAVAsReqType 0;
BA_ "GenSigSendType" SG_ 528 HuAVAsReqType 2;
BA_ "GenSigTimeoutMsg_HU_High_X445" SG_ 528 HuAVAsReqType 0;
BA_ "GenSigTimeoutMsg_HU_Mid_X445" SG_ 528 HuAVAsReqType 0;
BA_ "GenSigTimeoutTime_HU_High_X445" SG_ 528 HuAVAsReqType 0;
BA_ "GenSigTimeoutTime_HU_Mid_X445" SG_ 528 HuAVAsReqType 0;
BA_ "GenSigTimeoutMsg_IVI" SG_ 528 HuAVAsReqType 0;
BA_ "GenSigTimeoutTime_IVI" SG_ 528 HuAVAsReqType 0;
BA_ "GenSigTimeoutTime_HU_Mid_X451" SG_ 528 SndSyncDriveModePresenceAck 0;
BA_ "GenSigTimeoutTime_HU_High_X451" SG_ 528 SndSyncDriveModePresenceAck 0;
BA_ "GenSigTimeoutTime_HU_B" SG_ 528 SndSyncDriveModePresenceAck 0;
BA_ "GenSigTimeoutTime_HU_A" SG_ 528 SndSyncDriveModePresenceAck 0;
BA_ "GenSigTimeoutMsg_HU_Mid_X451" SG_ 528 SndSyncDriveModePresenceAck 0;
BA_ "GenSigTimeoutMsg_HU_High_X451" SG_ 528 SndSyncDriveModePresenceAck 0;
BA_ "GenSigTimeoutMsg_HU_B" SG_ 528 SndSyncDriveModePresenceAck 0;
BA_ "GenSigTimeoutMsg_HU_A" SG_ 528 SndSyncDriveModePresenceAck 0;
BA_ "GenSigSendType" SG_ 528 SndSyncDriveModePresenceAck 2;
BA_ "GenSigTimeoutMsg_HU_High_X445" SG_ 528 SndSyncDriveModePresenceAck 0;
BA_ "GenSigTimeoutMsg_HU_Mid_X445" SG_ 528 SndSyncDriveModePresenceAck 0;
BA_ "GenSigTimeoutTime_HU_High_X445" SG_ 528 SndSyncDriveModePresenceAck 0;
BA_ "GenSigTimeoutTime_HU_Mid_X445" SG_ 528 SndSyncDriveModePresenceAck 0;
BA_ "GenSigTimeoutMsg_IVI" SG_ 528 SndSyncDriveModePresenceAck 0;
BA_ "GenSigTimeoutTime_IVI" SG_ 528 SndSyncDriveModePresenceAck 0;
BA_ "GenSigTimeoutTime_HU_Mid_X451" SG_ 528 SndSyncDriveModeSettingStateAck 0;
BA_ "GenSigTimeoutTime_HU_High_X451" SG_ 528 SndSyncDriveModeSettingStateAck 0;
BA_ "GenSigTimeoutTime_HU_B" SG_ 528 SndSyncDriveModeSettingStateAck 0;
BA_ "GenSigTimeoutTime_HU_A" SG_ 528 SndSyncDriveModeSettingStateAck 0;
BA_ "GenSigTimeoutMsg_HU_Mid_X451" SG_ 528 SndSyncDriveModeSettingStateAck 0;
BA_ "GenSigTimeoutMsg_HU_High_X451" SG_ 528 SndSyncDriveModeSettingStateAck 0;
BA_ "GenSigTimeoutMsg_HU_B" SG_ 528 SndSyncDriveModeSettingStateAck 0;
BA_ "GenSigTimeoutMsg_HU_A" SG_ 528 SndSyncDriveModeSettingStateAck 0;
BA_ "GenSigSendType" SG_ 528 SndSyncDriveModeSettingStateAck 2;
BA_ "GenSigTimeoutMsg_HU_High_X445" SG_ 528 SndSyncDriveModeSettingStateAck 0;
BA_ "GenSigTimeoutMsg_HU_Mid_X445" SG_ 528 SndSyncDriveModeSettingStateAck 0;
BA_ "GenSigTimeoutTime_HU_High_X445" SG_ 528 SndSyncDriveModeSettingStateAck 0;
BA_ "GenSigTimeoutTime_HU_Mid_X445" SG_ 528 SndSyncDriveModeSettingStateAck 0;
BA_ "GenSigTimeoutMsg_IVI" SG_ 528 SndSyncDriveModeSettingStateAck 0;
BA_ "GenSigTimeoutTime_IVI" SG_ 528 SndSyncDriveModeSettingStateAck 0;
BA_ "GenSigTimeoutTime_HU_Mid_X451" SG_ 528 CrankSoundSettingStateAck 0;
BA_ "GenSigTimeoutTime_HU_High_X451" SG_ 528 CrankSoundSettingStateAck 0;
BA_ "GenSigTimeoutTime_HU_B" SG_ 528 CrankSoundSettingStateAck 0;
BA_ "GenSigTimeoutTime_HU_A" SG_ 528 CrankSoundSettingStateAck 0;
BA_ "GenSigTimeoutMsg_HU_Mid_X451" SG_ 528 CrankSoundSettingStateAck 0;
BA_ "GenSigTimeoutMsg_HU_High_X451" SG_ 528 CrankSoundSettingStateAck 0;
BA_ "GenSigTimeoutMsg_HU_B" SG_ 528 CrankSoundSettingStateAck 0;
BA_ "GenSigTimeoutMsg_HU_A" SG_ 528 CrankSoundSettingStateAck 0;
BA_ "GenSigSendType" SG_ 528 CrankSoundSettingStateAck 2;
BA_ "GenSigTimeoutMsg_HU_High_X445" SG_ 528 CrankSoundSettingStateAck 0;
BA_ "GenSigTimeoutMsg_HU_Mid_X445" SG_ 528 CrankSoundSettingStateAck 0;
BA_ "GenSigTimeoutTime_HU_High_X445" SG_ 528 CrankSoundSettingStateAck 0;
BA_ "GenSigTimeoutTime_HU_Mid_X445" SG_ 528 CrankSoundSettingStateAck 0;
BA_ "GenSigTimeoutMsg_IVI" SG_ 528 CrankSoundSettingStateAck 0;
BA_ "GenSigTimeoutTime_IVI" SG_ 528 CrankSoundSettingStateAck 0;
BA_ "GenSigTimeoutTime_HU_Mid_X451" SG_ 528 CrankEventPresenceAck 0;
BA_ "GenSigTimeoutTime_HU_High_X451" SG_ 528 CrankEventPresenceAck 0;
BA_ "GenSigTimeoutTime_HU_B" SG_ 528 CrankEventPresenceAck 0;
BA_ "GenSigTimeoutTime_HU_A" SG_ 528 CrankEventPresenceAck 0;
BA_ "GenSigTimeoutMsg_HU_Mid_X451" SG_ 528 CrankEventPresenceAck 0;
BA_ "GenSigTimeoutMsg_HU_High_X451" SG_ 528 CrankEventPresenceAck 0;
BA_ "GenSigTimeoutMsg_HU_B" SG_ 528 CrankEventPresenceAck 0;
BA_ "GenSigTimeoutMsg_HU_A" SG_ 528 CrankEventPresenceAck 0;
BA_ "GenSigSendType" SG_ 528 CrankEventPresenceAck 2;
BA_ "GenSigTimeoutMsg_HU_High_X445" SG_ 528 CrankEventPresenceAck 0;
BA_ "GenSigTimeoutMsg_HU_Mid_X445" SG_ 528 CrankEventPresenceAck 0;
BA_ "GenSigTimeoutTime_HU_High_X445" SG_ 528 CrankEventPresenceAck 0;
BA_ "GenSigTimeoutTime_HU_Mid_X445" SG_ 528 CrankEventPresenceAck 0;
BA_ "GenSigTimeoutMsg_IVI" SG_ 528 CrankEventPresenceAck 0;
BA_ "GenSigTimeoutTime_IVI" SG_ 528 CrankEventPresenceAck 0;
BA_ "GenSigTimeoutTime_HU_Mid_X451" SG_ 528 ChargingSoundSettingStateAck 0;
BA_ "GenSigTimeoutTime_HU_High_X451" SG_ 528 ChargingSoundSettingStateAck 0;
BA_ "GenSigTimeoutTime_HU_B" SG_ 528 ChargingSoundSettingStateAck 0;
BA_ "GenSigTimeoutTime_HU_A" SG_ 528 ChargingSoundSettingStateAck 0;
BA_ "GenSigTimeoutMsg_HU_Mid_X451" SG_ 528 ChargingSoundSettingStateAck 0;
BA_ "GenSigTimeoutMsg_HU_High_X451" SG_ 528 ChargingSoundSettingStateAck 0;
BA_ "GenSigTimeoutMsg_HU_B" SG_ 528 ChargingSoundSettingStateAck 0;
BA_ "GenSigTimeoutMsg_HU_A" SG_ 528 ChargingSoundSettingStateAck 0;
BA_ "GenSigSendType" SG_ 528 ChargingSoundSettingStateAck 2;
BA_ "GenSigTimeoutMsg_HU_High_X445" SG_ 528 ChargingSoundSettingStateAck 0;
BA_ "GenSigTimeoutMsg_HU_Mid_X445" SG_ 528 ChargingSoundSettingStateAck 0;
BA_ "GenSigTimeoutTime_HU_High_X445" SG_ 528 ChargingSoundSettingStateAck 0;
BA_ "GenSigTimeoutTime_HU_Mid_X445" SG_ 528 ChargingSoundSettingStateAck 0;
BA_ "GenSigTimeoutMsg_IVI" SG_ 528 ChargingSoundSettingStateAck 0;
BA_ "GenSigTimeoutTime_IVI" SG_ 528 ChargingSoundSettingStateAck 0;
BA_ "GenSigTimeoutTime_HU_Mid_X451" SG_ 528 ChargingEventPresenceAck 0;
BA_ "GenSigTimeoutTime_HU_High_X451" SG_ 528 ChargingEventPresenceAck 0;
BA_ "GenSigTimeoutTime_HU_B" SG_ 528 ChargingEventPresenceAck 0;
BA_ "GenSigTimeoutTime_HU_A" SG_ 528 ChargingEventPresenceAck 0;
BA_ "GenSigTimeoutMsg_HU_Mid_X451" SG_ 528 ChargingEventPresenceAck 0;
BA_ "GenSigTimeoutMsg_HU_High_X451" SG_ 528 ChargingEventPresenceAck 0;
BA_ "GenSigTimeoutMsg_HU_B" SG_ 528 ChargingEventPresenceAck 0;
BA_ "GenSigTimeoutMsg_HU_A" SG_ 528 ChargingEventPresenceAck 0;
BA_ "GenSigSendType" SG_ 528 ChargingEventPresenceAck 2;
BA_ "GenSigTimeoutMsg_HU_High_X445" SG_ 528 ChargingEventPresenceAck 0;
BA_ "GenSigTimeoutMsg_HU_Mid_X445" SG_ 528 ChargingEventPresenceAck 0;
BA_ "GenSigTimeoutTime_HU_High_X445" SG_ 528 ChargingEventPresenceAck 0;
BA_ "GenSigTimeoutTime_HU_Mid_X445" SG_ 528 ChargingEventPresenceAck 0;
BA_ "GenSigTimeoutMsg_IVI" SG_ 528 ChargingEventPresenceAck 0;
BA_ "GenSigTimeoutTime_IVI" SG_ 528 ChargingEventPresenceAck 0;
BA_ "GenSigTimeoutTime_HU_Mid_X451" SG_ 528 LockUnlockSettingStateAck 0;
BA_ "GenSigTimeoutTime_HU_High_X451" SG_ 528 LockUnlockSettingStateAck 0;
BA_ "GenSigTimeoutTime_HU_B" SG_ 528 LockUnlockSettingStateAck 0;
BA_ "GenSigTimeoutTime_HU_A" SG_ 528 LockUnlockSettingStateAck 0;
BA_ "GenSigTimeoutMsg_HU_Mid_X451" SG_ 528 LockUnlockSettingStateAck 0;
BA_ "GenSigTimeoutMsg_HU_High_X451" SG_ 528 LockUnlockSettingStateAck 0;
BA_ "GenSigTimeoutMsg_HU_B" SG_ 528 LockUnlockSettingStateAck 0;
BA_ "GenSigTimeoutMsg_HU_A" SG_ 528 LockUnlockSettingStateAck 0;
BA_ "GenSigSendType" SG_ 528 LockUnlockSettingStateAck 2;
BA_ "GenSigTimeoutMsg_HU_High_X445" SG_ 528 LockUnlockSettingStateAck 0;
BA_ "GenSigTimeoutMsg_HU_Mid_X445" SG_ 528 LockUnlockSettingStateAck 0;
BA_ "GenSigTimeoutTime_HU_High_X445" SG_ 528 LockUnlockSettingStateAck 0;
BA_ "GenSigTimeoutTime_HU_Mid_X445" SG_ 528 LockUnlockSettingStateAck 0;
BA_ "GenSigTimeoutMsg_IVI" SG_ 528 LockUnlockSettingStateAck 0;
BA_ "GenSigTimeoutTime_IVI" SG_ 528 LockUnlockSettingStateAck 0;
BA_ "GenSigTimeoutTime_HU_Mid_X451" SG_ 528 LockUnlockEventPresenceAck 0;
BA_ "GenSigTimeoutTime_HU_High_X451" SG_ 528 LockUnlockEventPresenceAck 0;
BA_ "GenSigTimeoutTime_HU_B" SG_ 528 LockUnlockEventPresenceAck 0;
BA_ "GenSigTimeoutTime_HU_A" SG_ 528 LockUnlockEventPresenceAck 0;
BA_ "GenSigTimeoutMsg_HU_Mid_X451" SG_ 528 LockUnlockEventPresenceAck 0;
BA_ "GenSigTimeoutMsg_HU_High_X451" SG_ 528 LockUnlockEventPresenceAck 0;
BA_ "GenSigTimeoutMsg_HU_B" SG_ 528 LockUnlockEventPresenceAck 0;
BA_ "GenSigTimeoutMsg_HU_A" SG_ 528 LockUnlockEventPresenceAck 0;
BA_ "GenSigSendType" SG_ 528 LockUnlockEventPresenceAck 2;
BA_ "GenSigTimeoutMsg_HU_High_X445" SG_ 528 LockUnlockEventPresenceAck 0;
BA_ "GenSigTimeoutMsg_HU_Mid_X445" SG_ 528 LockUnlockEventPresenceAck 0;
BA_ "GenSigTimeoutTime_HU_High_X445" SG_ 528 LockUnlockEventPresenceAck 0;
BA_ "GenSigTimeoutTime_HU_Mid_X445" SG_ 528 LockUnlockEventPresenceAck 0;
BA_ "GenSigTimeoutMsg_IVI" SG_ 528 LockUnlockEventPresenceAck 0;
BA_ "GenSigTimeoutTime_IVI" SG_ 528 LockUnlockEventPresenceAck 0;
BA_ "GenSigTimeoutTime_HU_Mid_X451" SG_ 528 ActiveExtSoundSettingStateAck 0;
BA_ "GenSigTimeoutTime_HU_High_X451" SG_ 528 ActiveExtSoundSettingStateAck 0;
BA_ "GenSigTimeoutTime_HU_B" SG_ 528 ActiveExtSoundSettingStateAck 0;
BA_ "GenSigTimeoutTime_HU_A" SG_ 528 ActiveExtSoundSettingStateAck 0;
BA_ "GenSigTimeoutMsg_HU_Mid_X451" SG_ 528 ActiveExtSoundSettingStateAck 0;
BA_ "GenSigTimeoutMsg_HU_High_X451" SG_ 528 ActiveExtSoundSettingStateAck 0;
BA_ "GenSigTimeoutMsg_HU_B" SG_ 528 ActiveExtSoundSettingStateAck 0;
BA_ "GenSigTimeoutMsg_HU_A" SG_ 528 ActiveExtSoundSettingStateAck 0;
BA_ "GenSigSendType" SG_ 528 ActiveExtSoundSettingStateAck 2;
BA_ "GenSigTimeoutMsg_HU_High_X445" SG_ 528 ActiveExtSoundSettingStateAck 0;
BA_ "GenSigTimeoutMsg_HU_Mid_X445" SG_ 528 ActiveExtSoundSettingStateAck 0;
BA_ "GenSigTimeoutTime_HU_High_X445" SG_ 528 ActiveExtSoundSettingStateAck 0;
BA_ "GenSigTimeoutTime_HU_Mid_X445" SG_ 528 ActiveExtSoundSettingStateAck 0;
BA_ "GenSigTimeoutMsg_IVI" SG_ 528 ActiveExtSoundSettingStateAck 0;
BA_ "GenSigTimeoutTime_IVI" SG_ 528 ActiveExtSoundSettingStateAck 0;
BA_ "GenSigTimeoutTime_HU_Mid_X451" SG_ 528 ActiveExtSoundPresenceAck 0;
BA_ "GenSigTimeoutTime_HU_High_X451" SG_ 528 ActiveExtSoundPresenceAck 0;
BA_ "GenSigTimeoutTime_HU_B" SG_ 528 ActiveExtSoundPresenceAck 0;
BA_ "GenSigTimeoutTime_HU_A" SG_ 528 ActiveExtSoundPresenceAck 0;
BA_ "GenSigTimeoutMsg_HU_Mid_X451" SG_ 528 ActiveExtSoundPresenceAck 0;
BA_ "GenSigTimeoutMsg_HU_High_X451" SG_ 528 ActiveExtSoundPresenceAck 0;
BA_ "GenSigTimeoutMsg_HU_B" SG_ 528 ActiveExtSoundPresenceAck 0;
BA_ "GenSigTimeoutMsg_HU_A" SG_ 528 ActiveExtSoundPresenceAck 0;
BA_ "GenSigSendType" SG_ 528 ActiveExtSoundPresenceAck 2;
BA_ "GenSigTimeoutMsg_HU_High_X445" SG_ 528 ActiveExtSoundPresenceAck 0;
BA_ "GenSigTimeoutMsg_HU_Mid_X445" SG_ 528 ActiveExtSoundPresenceAck 0;
BA_ "GenSigTimeoutTime_HU_High_X445" SG_ 528 ActiveExtSoundPresenceAck 0;
BA_ "GenSigTimeoutTime_HU_Mid_X445" SG_ 528 ActiveExtSoundPresenceAck 0;
BA_ "GenSigTimeoutMsg_IVI" SG_ 528 ActiveExtSoundPresenceAck 0;
BA_ "GenSigTimeoutTime_IVI" SG_ 528 ActiveExtSoundPresenceAck 0;
BA_ "GenSigTimeoutTime_HU_Mid_X451" SG_ 527 V2XSoundSettingState 0;
BA_ "GenSigTimeoutTime_HU_High_X451" SG_ 527 V2XSoundSettingState 0;
BA_ "GenSigTimeoutTime_HU_B" SG_ 527 V2XSoundSettingState 0;
BA_ "GenSigTimeoutTime_HU_A" SG_ 527 V2XSoundSettingState 0;
BA_ "GenSigTimeoutMsg_HU_Mid_X451" SG_ 527 V2XSoundSettingState 0;
BA_ "GenSigTimeoutMsg_HU_High_X451" SG_ 527 V2XSoundSettingState 0;
BA_ "GenSigTimeoutMsg_HU_B" SG_ 527 V2XSoundSettingState 0;
BA_ "GenSigTimeoutMsg_HU_A" SG_ 527 V2XSoundSettingState 0;
BA_ "GenSigSendType" SG_ 527 V2XSoundSettingState 1;
BA_ "GenSigTimeoutMsg_HU_High_X445" SG_ 527 V2XSoundSettingState 0;
BA_ "GenSigTimeoutMsg_HU_Mid_X445" SG_ 527 V2XSoundSettingState 0;
BA_ "GenSigTimeoutTime_HU_High_X445" SG_ 527 V2XSoundSettingState 0;
BA_ "GenSigTimeoutTime_HU_Mid_X445" SG_ 527 V2XSoundSettingState 0;
BA_ "GenSigTimeoutMsg_IVI" SG_ 527 V2XSoundSettingState 0;
BA_ "GenSigTimeoutTime_IVI" SG_ 527 V2XSoundSettingState 0;
BA_ "GenSigTimeoutTime_HU_Mid_X451" SG_ 527 V2XEventPresence 0;
BA_ "GenSigTimeoutTime_HU_High_X451" SG_ 527 V2XEventPresence 0;
BA_ "GenSigTimeoutTime_HU_B" SG_ 527 V2XEventPresence 0;
BA_ "GenSigTimeoutTime_HU_A" SG_ 527 V2XEventPresence 0;
BA_ "GenSigTimeoutMsg_HU_Mid_X451" SG_ 527 V2XEventPresence 0;
BA_ "GenSigTimeoutMsg_HU_High_X451" SG_ 527 V2XEventPresence 0;
BA_ "GenSigTimeoutMsg_HU_B" SG_ 527 V2XEventPresence 0;
BA_ "GenSigTimeoutMsg_HU_A" SG_ 527 V2XEventPresence 0;
BA_ "GenSigSendType" SG_ 527 V2XEventPresence 1;
BA_ "GenSigTimeoutMsg_HU_High_X445" SG_ 527 V2XEventPresence 0;
BA_ "GenSigTimeoutMsg_HU_Mid_X445" SG_ 527 V2XEventPresence 0;
BA_ "GenSigTimeoutTime_HU_High_X445" SG_ 527 V2XEventPresence 0;
BA_ "GenSigTimeoutTime_HU_Mid_X445" SG_ 527 V2XEventPresence 0;
BA_ "GenSigTimeoutMsg_IVI" SG_ 527 V2XEventPresence 0;
BA_ "GenSigTimeoutTime_IVI" SG_ 527 V2XEventPresence 0;
BA_ "GenSigTimeoutTime_HU_Mid_X451" SG_ 527 SoundSignSettingState 0;
BA_ "GenSigTimeoutTime_HU_High_X451" SG_ 527 SoundSignSettingState 0;
BA_ "GenSigTimeoutTime_HU_B" SG_ 527 SoundSignSettingState 0;
BA_ "GenSigTimeoutTime_HU_A" SG_ 527 SoundSignSettingState 0;
BA_ "GenSigTimeoutMsg_HU_Mid_X451" SG_ 527 SoundSignSettingState 0;
BA_ "GenSigTimeoutMsg_HU_High_X451" SG_ 527 SoundSignSettingState 0;
BA_ "GenSigTimeoutMsg_HU_B" SG_ 527 SoundSignSettingState 0;
BA_ "GenSigTimeoutMsg_HU_A" SG_ 527 SoundSignSettingState 0;
BA_ "GenSigSendType" SG_ 527 SoundSignSettingState 1;
BA_ "GenSigTimeoutMsg_HU_High_X445" SG_ 527 SoundSignSettingState 0;
BA_ "GenSigTimeoutMsg_HU_Mid_X445" SG_ 527 SoundSignSettingState 0;
BA_ "GenSigTimeoutTime_HU_High_X445" SG_ 527 SoundSignSettingState 0;
BA_ "GenSigTimeoutTime_HU_Mid_X445" SG_ 527 SoundSignSettingState 0;
BA_ "GenSigTimeoutMsg_IVI" SG_ 527 SoundSignSettingState 0;
BA_ "GenSigTimeoutTime_IVI" SG_ 527 SoundSignSettingState 0;
BA_ "GenSigTimeoutTime_HU_Mid_X451" SG_ 527 SoundSignSettingPresence 0;
BA_ "GenSigTimeoutTime_HU_High_X451" SG_ 527 SoundSignSettingPresence 0;
BA_ "GenSigTimeoutTime_HU_B" SG_ 527 SoundSignSettingPresence 0;
BA_ "GenSigTimeoutTime_HU_A" SG_ 527 SoundSignSettingPresence 0;
BA_ "GenSigTimeoutMsg_HU_Mid_X451" SG_ 527 SoundSignSettingPresence 0;
BA_ "GenSigTimeoutMsg_HU_High_X451" SG_ 527 SoundSignSettingPresence 0;
BA_ "GenSigTimeoutMsg_HU_B" SG_ 527 SoundSignSettingPresence 0;
BA_ "GenSigTimeoutMsg_HU_A" SG_ 527 SoundSignSettingPresence 0;
BA_ "GenSigSendType" SG_ 527 SoundSignSettingPresence 1;
BA_ "GenSigTimeoutMsg_HU_High_X445" SG_ 527 SoundSignSettingPresence 0;
BA_ "GenSigTimeoutMsg_HU_Mid_X445" SG_ 527 SoundSignSettingPresence 0;
BA_ "GenSigTimeoutTime_HU_High_X445" SG_ 527 SoundSignSettingPresence 0;
BA_ "GenSigTimeoutTime_HU_Mid_X445" SG_ 527 SoundSignSettingPresence 0;
BA_ "GenSigTimeoutMsg_IVI" SG_ 527 SoundSignSettingPresence 0;
BA_ "GenSigTimeoutTime_IVI" SG_ 527 SoundSignSettingPresence 0;
BA_ "GenSigTimeoutTime_HU_Mid_X451" SG_ 527 SndSyncDriveModeSettingState 0;
BA_ "GenSigTimeoutTime_HU_High_X451" SG_ 527 SndSyncDriveModeSettingState 0;
BA_ "GenSigTimeoutTime_HU_B" SG_ 527 SndSyncDriveModeSettingState 0;
BA_ "GenSigTimeoutTime_HU_A" SG_ 527 SndSyncDriveModeSettingState 0;
BA_ "GenSigTimeoutMsg_HU_Mid_X451" SG_ 527 SndSyncDriveModeSettingState 0;
BA_ "GenSigTimeoutMsg_HU_High_X451" SG_ 527 SndSyncDriveModeSettingState 0;
BA_ "GenSigTimeoutMsg_HU_B" SG_ 527 SndSyncDriveModeSettingState 0;
BA_ "GenSigTimeoutMsg_HU_A" SG_ 527 SndSyncDriveModeSettingState 0;
BA_ "GenSigSendType" SG_ 527 SndSyncDriveModeSettingState 1;
BA_ "GenSigTimeoutMsg_HU_High_X445" SG_ 527 SndSyncDriveModeSettingState 0;
BA_ "GenSigTimeoutMsg_HU_Mid_X445" SG_ 527 SndSyncDriveModeSettingState 0;
BA_ "GenSigTimeoutTime_HU_High_X445" SG_ 527 SndSyncDriveModeSettingState 0;
BA_ "GenSigTimeoutTime_HU_Mid_X445" SG_ 527 SndSyncDriveModeSettingState 0;
BA_ "GenSigTimeoutMsg_IVI" SG_ 527 SndSyncDriveModeSettingState 0;
BA_ "GenSigTimeoutTime_IVI" SG_ 527 SndSyncDriveModeSettingState 0;
BA_ "GenSigTimeoutTime_HU_Mid_X451" SG_ 527 SndSyncDriveModePresence 0;
BA_ "GenSigTimeoutTime_HU_High_X451" SG_ 527 SndSyncDriveModePresence 0;
BA_ "GenSigTimeoutTime_HU_B" SG_ 527 SndSyncDriveModePresence 0;
BA_ "GenSigTimeoutTime_HU_A" SG_ 527 SndSyncDriveModePresence 0;
BA_ "GenSigTimeoutMsg_HU_Mid_X451" SG_ 527 SndSyncDriveModePresence 0;
BA_ "GenSigTimeoutMsg_HU_High_X451" SG_ 527 SndSyncDriveModePresence 0;
BA_ "GenSigTimeoutMsg_HU_B" SG_ 527 SndSyncDriveModePresence 0;
BA_ "GenSigTimeoutMsg_HU_A" SG_ 527 SndSyncDriveModePresence 0;
BA_ "GenSigSendType" SG_ 527 SndSyncDriveModePresence 1;
BA_ "GenSigTimeoutMsg_HU_High_X445" SG_ 527 SndSyncDriveModePresence 0;
BA_ "GenSigTimeoutMsg_HU_Mid_X445" SG_ 527 SndSyncDriveModePresence 0;
BA_ "GenSigTimeoutTime_HU_High_X445" SG_ 527 SndSyncDriveModePresence 0;
BA_ "GenSigTimeoutTime_HU_Mid_X445" SG_ 527 SndSyncDriveModePresence 0;
BA_ "GenSigTimeoutMsg_IVI" SG_ 527 SndSyncDriveModePresence 0;
BA_ "GenSigTimeoutTime_IVI" SG_ 527 SndSyncDriveModePresence 0;
BA_ "GenSigTimeoutTime_HU_Mid_X451" SG_ 527 LockUnlockSettingState 0;
BA_ "GenSigTimeoutTime_HU_High_X451" SG_ 527 LockUnlockSettingState 0;
BA_ "GenSigTimeoutTime_HU_B" SG_ 527 LockUnlockSettingState 0;
BA_ "GenSigTimeoutTime_HU_A" SG_ 527 LockUnlockSettingState 0;
BA_ "GenSigTimeoutMsg_HU_Mid_X451" SG_ 527 LockUnlockSettingState 0;
BA_ "GenSigTimeoutMsg_HU_High_X451" SG_ 527 LockUnlockSettingState 0;
BA_ "GenSigTimeoutMsg_HU_B" SG_ 527 LockUnlockSettingState 0;
BA_ "GenSigTimeoutMsg_HU_A" SG_ 527 LockUnlockSettingState 0;
BA_ "GenSigSendType" SG_ 527 LockUnlockSettingState 1;
BA_ "GenSigTimeoutMsg_HU_High_X445" SG_ 527 LockUnlockSettingState 0;
BA_ "GenSigTimeoutMsg_HU_Mid_X445" SG_ 527 LockUnlockSettingState 0;
BA_ "GenSigTimeoutTime_HU_High_X445" SG_ 527 LockUnlockSettingState 0;
BA_ "GenSigTimeoutTime_HU_Mid_X445" SG_ 527 LockUnlockSettingState 0;
BA_ "GenSigTimeoutMsg_IVI" SG_ 527 LockUnlockSettingState 0;
BA_ "GenSigTimeoutTime_IVI" SG_ 527 LockUnlockSettingState 0;
BA_ "GenSigTimeoutTime_HU_Mid_X451" SG_ 527 LockUnlockEventPresence 0;
BA_ "GenSigTimeoutTime_HU_High_X451" SG_ 527 LockUnlockEventPresence 0;
BA_ "GenSigTimeoutTime_HU_B" SG_ 527 LockUnlockEventPresence 0;
BA_ "GenSigTimeoutTime_HU_A" SG_ 527 LockUnlockEventPresence 0;
BA_ "GenSigTimeoutMsg_HU_Mid_X451" SG_ 527 LockUnlockEventPresence 0;
BA_ "GenSigTimeoutMsg_HU_High_X451" SG_ 527 LockUnlockEventPresence 0;
BA_ "GenSigTimeoutMsg_HU_B" SG_ 527 LockUnlockEventPresence 0;
BA_ "GenSigTimeoutMsg_HU_A" SG_ 527 LockUnlockEventPresence 0;
BA_ "GenSigSendType" SG_ 527 LockUnlockEventPresence 1;
BA_ "GenSigTimeoutMsg_HU_High_X445" SG_ 527 LockUnlockEventPresence 0;
BA_ "GenSigTimeoutMsg_HU_Mid_X445" SG_ 527 LockUnlockEventPresence 0;
BA_ "GenSigTimeoutTime_HU_High_X445" SG_ 527 LockUnlockEventPresence 0;
BA_ "GenSigTimeoutTime_HU_Mid_X445" SG_ 527 LockUnlockEventPresence 0;
BA_ "GenSigTimeoutMsg_IVI" SG_ 527 LockUnlockEventPresence 0;
BA_ "GenSigTimeoutTime_IVI" SG_ 527 LockUnlockEventPresence 0;
BA_ "GenSigTimeoutTime_HU_Mid_X451" SG_ 527 CrankSoundSettingState 0;
BA_ "GenSigTimeoutTime_HU_High_X451" SG_ 527 CrankSoundSettingState 0;
BA_ "GenSigTimeoutTime_HU_B" SG_ 527 CrankSoundSettingState 0;
BA_ "GenSigTimeoutTime_HU_A" SG_ 527 CrankSoundSettingState 0;
BA_ "GenSigTimeoutMsg_HU_Mid_X451" SG_ 527 CrankSoundSettingState 0;
BA_ "GenSigTimeoutMsg_HU_High_X451" SG_ 527 CrankSoundSettingState 0;
BA_ "GenSigTimeoutMsg_HU_B" SG_ 527 CrankSoundSettingState 0;
BA_ "GenSigTimeoutMsg_HU_A" SG_ 527 CrankSoundSettingState 0;
BA_ "GenSigSendType" SG_ 527 CrankSoundSettingState 1;
BA_ "GenSigTimeoutMsg_HU_High_X445" SG_ 527 CrankSoundSettingState 0;
BA_ "GenSigTimeoutMsg_HU_Mid_X445" SG_ 527 CrankSoundSettingState 0;
BA_ "GenSigTimeoutTime_HU_High_X445" SG_ 527 CrankSoundSettingState 0;
BA_ "GenSigTimeoutTime_HU_Mid_X445" SG_ 527 CrankSoundSettingState 0;
BA_ "GenSigTimeoutMsg_IVI" SG_ 527 CrankSoundSettingState 0;
BA_ "GenSigTimeoutTime_IVI" SG_ 527 CrankSoundSettingState 0;
BA_ "GenSigTimeoutTime_HU_Mid_X451" SG_ 527 CrankEventPresence 0;
BA_ "GenSigTimeoutTime_HU_High_X451" SG_ 527 CrankEventPresence 0;
BA_ "GenSigTimeoutTime_HU_B" SG_ 527 CrankEventPresence 0;
BA_ "GenSigTimeoutTime_HU_A" SG_ 527 CrankEventPresence 0;
BA_ "GenSigTimeoutMsg_HU_Mid_X451" SG_ 527 CrankEventPresence 0;
BA_ "GenSigTimeoutMsg_HU_High_X451" SG_ 527 CrankEventPresence 0;
BA_ "GenSigTimeoutMsg_HU_B" SG_ 527 CrankEventPresence 0;
BA_ "GenSigTimeoutMsg_HU_A" SG_ 527 CrankEventPresence 0;
BA_ "GenSigSendType" SG_ 527 CrankEventPresence 1;
BA_ "GenSigTimeoutMsg_HU_High_X445" SG_ 527 CrankEventPresence 0;
BA_ "GenSigTimeoutMsg_HU_Mid_X445" SG_ 527 CrankEventPresence 0;
BA_ "GenSigTimeoutTime_HU_High_X445" SG_ 527 CrankEventPresence 0;
BA_ "GenSigTimeoutTime_HU_Mid_X445" SG_ 527 CrankEventPresence 0;
BA_ "GenSigTimeoutMsg_IVI" SG_ 527 CrankEventPresence 0;
BA_ "GenSigTimeoutTime_IVI" SG_ 527 CrankEventPresence 0;
BA_ "GenSigTimeoutTime_HU_Mid_X451" SG_ 527 ChargingSoundSettingState 0;
BA_ "GenSigTimeoutTime_HU_High_X451" SG_ 527 ChargingSoundSettingState 0;
BA_ "GenSigTimeoutTime_HU_B" SG_ 527 ChargingSoundSettingState 0;
BA_ "GenSigTimeoutTime_HU_A" SG_ 527 ChargingSoundSettingState 0;
BA_ "GenSigTimeoutMsg_HU_Mid_X451" SG_ 527 ChargingSoundSettingState 0;
BA_ "GenSigTimeoutMsg_HU_High_X451" SG_ 527 ChargingSoundSettingState 0;
BA_ "GenSigTimeoutMsg_HU_B" SG_ 527 ChargingSoundSettingState 0;
BA_ "GenSigTimeoutMsg_HU_A" SG_ 527 ChargingSoundSettingState 0;
BA_ "GenSigSendType" SG_ 527 ChargingSoundSettingState 1;
BA_ "GenSigTimeoutMsg_HU_High_X445" SG_ 527 ChargingSoundSettingState 0;
BA_ "GenSigTimeoutMsg_HU_Mid_X445" SG_ 527 ChargingSoundSettingState 0;
BA_ "GenSigTimeoutTime_HU_High_X445" SG_ 527 ChargingSoundSettingState 0;
BA_ "GenSigTimeoutTime_HU_Mid_X445" SG_ 527 ChargingSoundSettingState 0;
BA_ "GenSigTimeoutMsg_IVI" SG_ 527 ChargingSoundSettingState 0;
BA_ "GenSigTimeoutTime_IVI" SG_ 527 ChargingSoundSettingState 0;
BA_ "GenSigTimeoutTime_HU_Mid_X451" SG_ 527 ChargingEventPresence 0;
BA_ "GenSigTimeoutTime_HU_High_X451" SG_ 527 ChargingEventPresence 0;
BA_ "GenSigTimeoutTime_HU_B" SG_ 527 ChargingEventPresence 0;
BA_ "GenSigTimeoutTime_HU_A" SG_ 527 ChargingEventPresence 0;
BA_ "GenSigTimeoutMsg_HU_Mid_X451" SG_ 527 ChargingEventPresence 0;
BA_ "GenSigTimeoutMsg_HU_High_X451" SG_ 527 ChargingEventPresence 0;
BA_ "GenSigTimeoutMsg_HU_B" SG_ 527 ChargingEventPresence 0;
BA_ "GenSigTimeoutMsg_HU_A" SG_ 527 ChargingEventPresence 0;
BA_ "GenSigSendType" SG_ 527 ChargingEventPresence 1;
BA_ "GenSigTimeoutMsg_HU_High_X445" SG_ 527 ChargingEventPresence 0;
BA_ "GenSigTimeoutMsg_HU_Mid_X445" SG_ 527 ChargingEventPresence 0;
BA_ "GenSigTimeoutTime_HU_High_X445" SG_ 527 ChargingEventPresence 0;
BA_ "GenSigTimeoutTime_HU_Mid_X445" SG_ 527 ChargingEventPresence 0;
BA_ "GenSigTimeoutMsg_IVI" SG_ 527 ChargingEventPresence 0;
BA_ "GenSigTimeoutTime_IVI" SG_ 527 ChargingEventPresence 0;
BA_ "GenSigTimeoutTime_HU_Mid_X451" SG_ 527 AVAsPreviewStateapplicability 0;
BA_ "GenSigTimeoutTime_HU_High_X451" SG_ 527 AVAsPreviewStateapplicability 0;
BA_ "GenSigTimeoutTime_HU_B" SG_ 527 AVAsPreviewStateapplicability 0;
BA_ "GenSigTimeoutTime_HU_A" SG_ 527 AVAsPreviewStateapplicability 0;
BA_ "GenSigTimeoutMsg_HU_Mid_X451" SG_ 527 AVAsPreviewStateapplicability 0;
BA_ "GenSigTimeoutMsg_HU_High_X451" SG_ 527 AVAsPreviewStateapplicability 0;
BA_ "GenSigTimeoutMsg_HU_B" SG_ 527 AVAsPreviewStateapplicability 0;
BA_ "GenSigTimeoutMsg_HU_A" SG_ 527 AVAsPreviewStateapplicability 0;
BA_ "GenSigSendType" SG_ 527 AVAsPreviewStateapplicability 1;
BA_ "GenSigTimeoutMsg_HU_High_X445" SG_ 527 AVAsPreviewStateapplicability 0;
BA_ "GenSigTimeoutMsg_HU_Mid_X445" SG_ 527 AVAsPreviewStateapplicability 0;
BA_ "GenSigTimeoutTime_HU_High_X445" SG_ 527 AVAsPreviewStateapplicability 0;
BA_ "GenSigTimeoutTime_HU_Mid_X445" SG_ 527 AVAsPreviewStateapplicability 0;
BA_ "GenSigTimeoutMsg_IVI" SG_ 527 AVAsPreviewStateapplicability 0;
BA_ "GenSigTimeoutTime_IVI" SG_ 527 AVAsPreviewStateapplicability 0;
BA_ "GenSigTimeoutTime_HU_Mid_X451" SG_ 527 AVAsPreviewState 0;
BA_ "GenSigTimeoutTime_HU_High_X451" SG_ 527 AVAsPreviewState 0;
BA_ "GenSigTimeoutTime_HU_B" SG_ 527 AVAsPreviewState 0;
BA_ "GenSigTimeoutTime_HU_A" SG_ 527 AVAsPreviewState 0;
BA_ "GenSigTimeoutMsg_HU_Mid_X451" SG_ 527 AVAsPreviewState 0;
BA_ "GenSigTimeoutMsg_HU_High_X451" SG_ 527 AVAsPreviewState 0;
BA_ "GenSigTimeoutMsg_HU_B" SG_ 527 AVAsPreviewState 0;
BA_ "GenSigTimeoutMsg_HU_A" SG_ 527 AVAsPreviewState 0;
BA_ "GenSigSendType" SG_ 527 AVAsPreviewState 1;
BA_ "GenSigTimeoutMsg_HU_High_X445" SG_ 527 AVAsPreviewState 0;
BA_ "GenSigTimeoutMsg_HU_Mid_X445" SG_ 527 AVAsPreviewState 0;
BA_ "GenSigTimeoutTime_HU_High_X445" SG_ 527 AVAsPreviewState 0;
BA_ "GenSigTimeoutTime_HU_Mid_X445" SG_ 527 AVAsPreviewState 0;
BA_ "GenSigTimeoutMsg_IVI" SG_ 527 AVAsPreviewState 0;
BA_ "GenSigTimeoutTime_IVI" SG_ 527 AVAsPreviewState 0;
BA_ "GenSigTimeoutTime_HU_Mid_X451" SG_ 527 AVAsPreviewPresence 0;
BA_ "GenSigTimeoutTime_HU_High_X451" SG_ 527 AVAsPreviewPresence 0;
BA_ "GenSigTimeoutTime_HU_B" SG_ 527 AVAsPreviewPresence 0;
BA_ "GenSigTimeoutTime_HU_A" SG_ 527 AVAsPreviewPresence 0;
BA_ "GenSigTimeoutMsg_HU_Mid_X451" SG_ 527 AVAsPreviewPresence 0;
BA_ "GenSigTimeoutMsg_HU_High_X451" SG_ 527 AVAsPreviewPresence 0;
BA_ "GenSigTimeoutMsg_HU_B" SG_ 527 AVAsPreviewPresence 0;
BA_ "GenSigTimeoutMsg_HU_A" SG_ 527 AVAsPreviewPresence 0;
BA_ "GenSigSendType" SG_ 527 AVAsPreviewPresence 1;
BA_ "GenSigTimeoutMsg_HU_High_X445" SG_ 527 AVAsPreviewPresence 0;
BA_ "GenSigTimeoutMsg_HU_Mid_X445" SG_ 527 AVAsPreviewPresence 0;
BA_ "GenSigTimeoutTime_HU_High_X445" SG_ 527 AVAsPreviewPresence 0;
BA_ "GenSigTimeoutTime_HU_Mid_X445" SG_ 527 AVAsPreviewPresence 0;
BA_ "GenSigTimeoutMsg_IVI" SG_ 527 AVAsPreviewPresence 0;
BA_ "GenSigTimeoutTime_IVI" SG_ 527 AVAsPreviewPresence 0;
BA_ "GenSigTimeoutTime_HU_Mid_X451" SG_ 527 ActiveExtSoundSettingState 0;
BA_ "GenSigTimeoutTime_HU_High_X451" SG_ 527 ActiveExtSoundSettingState 0;
BA_ "GenSigTimeoutTime_HU_B" SG_ 527 ActiveExtSoundSettingState 0;
BA_ "GenSigTimeoutTime_HU_A" SG_ 527 ActiveExtSoundSettingState 0;
BA_ "GenSigTimeoutMsg_HU_Mid_X451" SG_ 527 ActiveExtSoundSettingState 0;
BA_ "GenSigTimeoutMsg_HU_High_X451" SG_ 527 ActiveExtSoundSettingState 0;
BA_ "GenSigTimeoutMsg_HU_B" SG_ 527 ActiveExtSoundSettingState 0;
BA_ "GenSigTimeoutMsg_HU_A" SG_ 527 ActiveExtSoundSettingState 0;
BA_ "GenSigSendType" SG_ 527 ActiveExtSoundSettingState 1;
BA_ "GenSigTimeoutMsg_HU_High_X445" SG_ 527 ActiveExtSoundSettingState 0;
BA_ "GenSigTimeoutMsg_HU_Mid_X445" SG_ 527 ActiveExtSoundSettingState 0;
BA_ "GenSigTimeoutTime_HU_High_X445" SG_ 527 ActiveExtSoundSettingState 0;
BA_ "GenSigTimeoutTime_HU_Mid_X445" SG_ 527 ActiveExtSoundSettingState 0;
BA_ "GenSigTimeoutMsg_IVI" SG_ 527 ActiveExtSoundSettingState 0;
BA_ "GenSigTimeoutTime_IVI" SG_ 527 ActiveExtSoundSettingState 0;
BA_ "GenSigTimeoutTime_HU_Mid_X451" SG_ 527 ActiveExtSoundPresence 0;
BA_ "GenSigTimeoutTime_HU_High_X451" SG_ 527 ActiveExtSoundPresence 0;
BA_ "GenSigTimeoutTime_HU_B" SG_ 527 ActiveExtSoundPresence 0;
BA_ "GenSigTimeoutTime_HU_A" SG_ 527 ActiveExtSoundPresence 0;
BA_ "GenSigTimeoutMsg_HU_Mid_X451" SG_ 527 ActiveExtSoundPresence 0;
BA_ "GenSigTimeoutMsg_HU_High_X451" SG_ 527 ActiveExtSoundPresence 0;
BA_ "GenSigTimeoutMsg_HU_B" SG_ 527 ActiveExtSoundPresence 0;
BA_ "GenSigTimeoutMsg_HU_A" SG_ 527 ActiveExtSoundPresence 0;
BA_ "GenSigSendType" SG_ 527 ActiveExtSoundPresence 1;
BA_ "GenSigTimeoutMsg_HU_High_X445" SG_ 527 ActiveExtSoundPresence 0;
BA_ "GenSigTimeoutMsg_HU_Mid_X445" SG_ 527 ActiveExtSoundPresence 0;
BA_ "GenSigTimeoutTime_HU_High_X445" SG_ 527 ActiveExtSoundPresence 0;
BA_ "GenSigTimeoutTime_HU_Mid_X445" SG_ 527 ActiveExtSoundPresence 0;
BA_ "GenSigTimeoutMsg_IVI" SG_ 527 ActiveExtSoundPresence 0;
BA_ "GenSigTimeoutTime_IVI" SG_ 527 ActiveExtSoundPresence 0;
BA_ "GenSigSendType" SG_ 751 AvasPresence 7;
BA_ "GenSigCycleTimeActive" SG_ 751 AvasPresence 100;
BA_ "GenSigCycleTime" SG_ 751 AvasPresence 100;
BA_ "GenSigSendType" SG_ 751 AVAsMalFunction 7;
BA_ "GenSigCycleTimeActive" SG_ 751 AVAsMalFunction 100;
BA_ "GenSigCycleTime" SG_ 751 AVAsMalFunction 100;
BA_ "GenSigSendType" SG_ 749 LdwWarningSettingPresence 7;
BA_ "GenSigCycleTimeActive" SG_ 749 LdwWarningSettingPresence 100;
BA_ "GenSigCycleTime" SG_ 749 LdwWarningSettingPresence 100;
BA_ "GenSigSendType" SG_ 749 LcsOnOffState 7;
BA_ "GenSigCycleTimeActive" SG_ 749 LcsOnOffState 100;
BA_ "GenSigCycleTime" SG_ 749 LcsOnOffState 100;
BA_ "GenSigSendType" SG_ 749 AsaOnOffState 7;
BA_ "GenSigCycleTimeActive" SG_ 749 AsaOnOffState 100;
BA_ "GenSigCycleTime" SG_ 749 AsaOnOffState 100;
BA_ "GenSigSendType" SG_ 749 IsaOnOffState 7;
BA_ "GenSigCycleTimeActive" SG_ 749 IsaOnOffState 100;
BA_ "GenSigCycleTime" SG_ 749 IsaOnOffState 100;
BA_ "GenSigTimeoutTime_HU_Mid_X451" SG_ 864 MemoryOrvmFunState 1000;
BA_ "GenSigTimeoutTime_HU_High_X451" SG_ 864 MemoryOrvmFunState 1000;
BA_ "GenSigTimeoutTime_HU_B" SG_ 864 MemoryOrvmFunState 1000;
BA_ "GenSigTimeoutTime_HU_A" SG_ 864 MemoryOrvmFunState 1000;
BA_ "GenSigTimeoutMsg_HU_Mid_X451" SG_ 864 MemoryOrvmFunState 1000;
BA_ "GenSigTimeoutMsg_HU_High_X451" SG_ 864 MemoryOrvmFunState 1000;
BA_ "GenSigTimeoutMsg_HU_B" SG_ 864 MemoryOrvmFunState 1000;
BA_ "GenSigTimeoutMsg_HU_A" SG_ 864 MemoryOrvmFunState 1000;
BA_ "GenSigSendType" SG_ 864 MemoryOrvmFunState 7;
BA_ "GenSigCycleTimeActive" SG_ 864 MemoryOrvmFunState 200;
BA_ "GenSigCycleTime" SG_ 864 MemoryOrvmFunState 200;
BA_ "GenSigTimeoutMsg_HU_High_X445" SG_ 864 MemoryOrvmFunState 1000;
BA_ "GenSigTimeoutMsg_HU_Mid_X445" SG_ 864 MemoryOrvmFunState 1000;
BA_ "GenSigTimeoutTime_HU_High_X445" SG_ 864 MemoryOrvmFunState 1000;
BA_ "GenSigTimeoutTime_HU_Mid_X445" SG_ 864 MemoryOrvmFunState 1000;
BA_ "GenSigTimeoutMsg_IVI" SG_ 864 MemoryOrvmFunState 1000;
BA_ "GenSigTimeoutTime_IVI" SG_ 864 MemoryOrvmFunState 1000;
BA_ "GenSigTimeoutTime_HU_Mid_X451" SG_ 864 BcmHuOrvmTiltReversePosState 1000;
BA_ "GenSigTimeoutTime_HU_High_X451" SG_ 864 BcmHuOrvmTiltReversePosState 1000;
BA_ "GenSigTimeoutTime_HU_B" SG_ 864 BcmHuOrvmTiltReversePosState 1000;
BA_ "GenSigTimeoutTime_HU_A" SG_ 864 BcmHuOrvmTiltReversePosState 1000;
BA_ "GenSigTimeoutMsg_HU_Mid_X451" SG_ 864 BcmHuOrvmTiltReversePosState 1000;
BA_ "GenSigTimeoutMsg_HU_High_X451" SG_ 864 BcmHuOrvmTiltReversePosState 1000;
BA_ "GenSigTimeoutMsg_HU_B" SG_ 864 BcmHuOrvmTiltReversePosState 1000;
BA_ "GenSigTimeoutMsg_HU_A" SG_ 864 BcmHuOrvmTiltReversePosState 1000;
BA_ "GenSigStartValue" SG_ 864 BcmHuOrvmTiltReversePosState 1;
BA_ "GenSigSendType" SG_ 864 BcmHuOrvmTiltReversePosState 7;
BA_ "GenSigCycleTimeActive" SG_ 864 BcmHuOrvmTiltReversePosState 200;
BA_ "GenSigCycleTime" SG_ 864 BcmHuOrvmTiltReversePosState 200;
BA_ "GenSigTimeoutMsg_HU_High_X445" SG_ 864 BcmHuOrvmTiltReversePosState 1000;
BA_ "GenSigTimeoutMsg_HU_Mid_X445" SG_ 864 BcmHuOrvmTiltReversePosState 1000;
BA_ "GenSigTimeoutTime_HU_High_X445" SG_ 864 BcmHuOrvmTiltReversePosState 1000;
BA_ "GenSigTimeoutTime_HU_Mid_X445" SG_ 864 BcmHuOrvmTiltReversePosState 1000;
BA_ "GenSigTimeoutMsg_IVI" SG_ 864 BcmHuOrvmTiltReversePosState 1000;
BA_ "GenSigTimeoutTime_IVI" SG_ 864 BcmHuOrvmTiltReversePosState 1000;
BA_ "GenSigTimeoutTime_HU_Mid_X451" SG_ 864 BcmHuMrrAutoUnfoldFuncState 1000;
BA_ "GenSigTimeoutTime_HU_High_X451" SG_ 864 BcmHuMrrAutoUnfoldFuncState 1000;
BA_ "GenSigTimeoutTime_HU_B" SG_ 864 BcmHuMrrAutoUnfoldFuncState 1000;
BA_ "GenSigTimeoutTime_HU_A" SG_ 864 BcmHuMrrAutoUnfoldFuncState 1000;
BA_ "GenSigTimeoutMsg_HU_Mid_X451" SG_ 864 BcmHuMrrAutoUnfoldFuncState 1000;
BA_ "GenSigTimeoutMsg_HU_High_X451" SG_ 864 BcmHuMrrAutoUnfoldFuncState 1000;
BA_ "GenSigTimeoutMsg_HU_B" SG_ 864 BcmHuMrrAutoUnfoldFuncState 1000;
BA_ "GenSigTimeoutMsg_HU_A" SG_ 864 BcmHuMrrAutoUnfoldFuncState 1000;
BA_ "GenSigSendType" SG_ 864 BcmHuMrrAutoUnfoldFuncState 7;
BA_ "GenSigCycleTimeActive" SG_ 864 BcmHuMrrAutoUnfoldFuncState 200;
BA_ "GenSigCycleTime" SG_ 864 BcmHuMrrAutoUnfoldFuncState 200;
BA_ "GenSigTimeoutMsg_HU_High_X445" SG_ 864 BcmHuMrrAutoUnfoldFuncState 1000;
BA_ "GenSigTimeoutMsg_HU_Mid_X445" SG_ 864 BcmHuMrrAutoUnfoldFuncState 1000;
BA_ "GenSigTimeoutTime_HU_High_X445" SG_ 864 BcmHuMrrAutoUnfoldFuncState 1000;
BA_ "GenSigTimeoutTime_HU_Mid_X445" SG_ 864 BcmHuMrrAutoUnfoldFuncState 1000;
BA_ "GenSigTimeoutMsg_IVI" SG_ 864 BcmHuMrrAutoUnfoldFuncState 1000;
BA_ "GenSigTimeoutTime_IVI" SG_ 864 BcmHuMrrAutoUnfoldFuncState 1000;
BA_ "GenSigTimeoutTime_HU_Mid_X451" SG_ 864 BcmHuMrrAutoUnfoldSelState 1000;
BA_ "GenSigTimeoutTime_HU_High_X451" SG_ 864 BcmHuMrrAutoUnfoldSelState 1000;
BA_ "GenSigTimeoutTime_HU_B" SG_ 864 BcmHuMrrAutoUnfoldSelState 1000;
BA_ "GenSigTimeoutTime_HU_A" SG_ 864 BcmHuMrrAutoUnfoldSelState 1000;
BA_ "GenSigTimeoutMsg_HU_Mid_X451" SG_ 864 BcmHuMrrAutoUnfoldSelState 1000;
BA_ "GenSigTimeoutMsg_HU_High_X451" SG_ 864 BcmHuMrrAutoUnfoldSelState 1000;
BA_ "GenSigTimeoutMsg_HU_B" SG_ 864 BcmHuMrrAutoUnfoldSelState 1000;
BA_ "GenSigTimeoutMsg_HU_A" SG_ 864 BcmHuMrrAutoUnfoldSelState 1000;
BA_ "GenSigStartValue" SG_ 864 BcmHuMrrAutoUnfoldSelState 1;
BA_ "GenSigSendType" SG_ 864 BcmHuMrrAutoUnfoldSelState 7;
BA_ "GenSigCycleTimeActive" SG_ 864 BcmHuMrrAutoUnfoldSelState 200;
BA_ "GenSigCycleTime" SG_ 864 BcmHuMrrAutoUnfoldSelState 200;
BA_ "GenSigTimeoutMsg_HU_High_X445" SG_ 864 BcmHuMrrAutoUnfoldSelState 1000;
BA_ "GenSigTimeoutMsg_HU_Mid_X445" SG_ 864 BcmHuMrrAutoUnfoldSelState 1000;
BA_ "GenSigTimeoutTime_HU_High_X445" SG_ 864 BcmHuMrrAutoUnfoldSelState 1000;
BA_ "GenSigTimeoutTime_HU_Mid_X445" SG_ 864 BcmHuMrrAutoUnfoldSelState 1000;
BA_ "GenSigTimeoutMsg_IVI" SG_ 864 BcmHuMrrAutoUnfoldSelState 1000;
BA_ "GenSigTimeoutTime_IVI" SG_ 864 BcmHuMrrAutoUnfoldSelState 1000;
BA_ "Remarks" SG_ 864 PotHeightAdjState "null*";
BA_ "GenSigTimeoutTime_HU_Mid_X451" SG_ 864 PotHeightAdjState 1000;
BA_ "GenSigTimeoutTime_HU_High_X451" SG_ 864 PotHeightAdjState 1000;
BA_ "GenSigTimeoutTime_HU_B" SG_ 864 PotHeightAdjState 1000;
BA_ "GenSigTimeoutTime_HU_A" SG_ 864 PotHeightAdjState 1000;
BA_ "GenSigTimeoutMsg_HU_Mid_X451" SG_ 864 PotHeightAdjState 1000;
BA_ "GenSigTimeoutMsg_HU_High_X451" SG_ 864 PotHeightAdjState 1000;
BA_ "GenSigTimeoutMsg_HU_B" SG_ 864 PotHeightAdjState 1000;
BA_ "GenSigTimeoutMsg_HU_A" SG_ 864 PotHeightAdjState 1000;
BA_ "GenSigSendType" SG_ 864 PotHeightAdjState 7;
BA_ "GenSigCycleTimeActive" SG_ 864 PotHeightAdjState 200;
BA_ "GenSigCycleTime" SG_ 864 PotHeightAdjState 200;
BA_ "GenSigTimeoutMsg_HU_High_X445" SG_ 864 PotHeightAdjState 1000;
BA_ "GenSigTimeoutMsg_HU_Mid_X445" SG_ 864 PotHeightAdjState 1000;
BA_ "GenSigTimeoutTime_HU_High_X445" SG_ 864 PotHeightAdjState 1000;
BA_ "GenSigTimeoutTime_HU_Mid_X445" SG_ 864 PotHeightAdjState 1000;
BA_ "GenSigTimeoutMsg_IVI" SG_ 864 PotHeightAdjState 1000;
BA_ "GenSigTimeoutTime_IVI" SG_ 864 PotHeightAdjState 1000;
BA_ "Remarks" SG_ 864 PotSwRkeOnOffState "null*";
BA_ "GenSigTimeoutTime_HU_Mid_X451" SG_ 864 PotSwRkeOnOffState 1000;
BA_ "GenSigTimeoutTime_HU_High_X451" SG_ 864 PotSwRkeOnOffState 1000;
BA_ "GenSigTimeoutTime_HU_B" SG_ 864 PotSwRkeOnOffState 1000;
BA_ "GenSigTimeoutTime_HU_A" SG_ 864 PotSwRkeOnOffState 1000;
BA_ "GenSigTimeoutMsg_HU_Mid_X451" SG_ 864 PotSwRkeOnOffState 1000;
BA_ "GenSigTimeoutMsg_HU_High_X451" SG_ 864 PotSwRkeOnOffState 1000;
BA_ "GenSigTimeoutMsg_HU_B" SG_ 864 PotSwRkeOnOffState 1000;
BA_ "GenSigTimeoutMsg_HU_A" SG_ 864 PotSwRkeOnOffState 1000;
BA_ "GenSigSendType" SG_ 864 PotSwRkeOnOffState 7;
BA_ "GenSigCycleTimeActive" SG_ 864 PotSwRkeOnOffState 200;
BA_ "GenSigCycleTime" SG_ 864 PotSwRkeOnOffState 200;
BA_ "GenSigTimeoutMsg_HU_High_X445" SG_ 864 PotSwRkeOnOffState 1000;
BA_ "GenSigTimeoutMsg_HU_Mid_X445" SG_ 864 PotSwRkeOnOffState 1000;
BA_ "GenSigTimeoutTime_HU_High_X445" SG_ 864 PotSwRkeOnOffState 1000;
BA_ "GenSigTimeoutTime_HU_Mid_X445" SG_ 864 PotSwRkeOnOffState 1000;
BA_ "GenSigTimeoutMsg_IVI" SG_ 864 PotSwRkeOnOffState 1000;
BA_ "GenSigTimeoutTime_IVI" SG_ 864 PotSwRkeOnOffState 1000;
BA_ "Remarks" SG_ 864 PotGestOnOffState "null*";
BA_ "GenSigTimeoutTime_HU_Mid_X451" SG_ 864 PotGestOnOffState 1000;
BA_ "GenSigTimeoutTime_HU_High_X451" SG_ 864 PotGestOnOffState 1000;
BA_ "GenSigTimeoutTime_HU_B" SG_ 864 PotGestOnOffState 1000;
BA_ "GenSigTimeoutTime_HU_A" SG_ 864 PotGestOnOffState 1000;
BA_ "GenSigTimeoutMsg_HU_Mid_X451" SG_ 864 PotGestOnOffState 1000;
BA_ "GenSigTimeoutMsg_HU_High_X451" SG_ 864 PotGestOnOffState 1000;
BA_ "GenSigTimeoutMsg_HU_B" SG_ 864 PotGestOnOffState 1000;
BA_ "GenSigTimeoutMsg_HU_A" SG_ 864 PotGestOnOffState 1000;
BA_ "GenSigSendType" SG_ 864 PotGestOnOffState 7;
BA_ "GenSigCycleTimeActive" SG_ 864 PotGestOnOffState 200;
BA_ "GenSigCycleTime" SG_ 864 PotGestOnOffState 200;
BA_ "GenSigTimeoutMsg_HU_High_X445" SG_ 864 PotGestOnOffState 1000;
BA_ "GenSigTimeoutMsg_HU_Mid_X445" SG_ 864 PotGestOnOffState 1000;
BA_ "GenSigTimeoutTime_HU_High_X445" SG_ 864 PotGestOnOffState 1000;
BA_ "GenSigTimeoutTime_HU_Mid_X445" SG_ 864 PotGestOnOffState 1000;
BA_ "GenSigTimeoutMsg_IVI" SG_ 864 PotGestOnOffState 1000;
BA_ "GenSigTimeoutTime_IVI" SG_ 864 PotGestOnOffState 1000;
BA_ "Remarks" SG_ 864 PotBuzzOnOffState "null*";
BA_ "GenSigTimeoutTime_HU_Mid_X451" SG_ 864 PotBuzzOnOffState 1000;
BA_ "GenSigTimeoutTime_HU_High_X451" SG_ 864 PotBuzzOnOffState 1000;
BA_ "GenSigTimeoutTime_HU_B" SG_ 864 PotBuzzOnOffState 1000;
BA_ "GenSigTimeoutTime_HU_A" SG_ 864 PotBuzzOnOffState 1000;
BA_ "GenSigTimeoutMsg_HU_Mid_X451" SG_ 864 PotBuzzOnOffState 1000;
BA_ "GenSigTimeoutMsg_HU_High_X451" SG_ 864 PotBuzzOnOffState 1000;
BA_ "GenSigTimeoutMsg_HU_B" SG_ 864 PotBuzzOnOffState 1000;
BA_ "GenSigTimeoutMsg_HU_A" SG_ 864 PotBuzzOnOffState 1000;
BA_ "GenSigSendType" SG_ 864 PotBuzzOnOffState 7;
BA_ "GenSigCycleTimeActive" SG_ 864 PotBuzzOnOffState 200;
BA_ "GenSigCycleTime" SG_ 864 PotBuzzOnOffState 200;
BA_ "GenSigTimeoutMsg_HU_High_X445" SG_ 864 PotBuzzOnOffState 1000;
BA_ "GenSigTimeoutMsg_HU_Mid_X445" SG_ 864 PotBuzzOnOffState 1000;
BA_ "GenSigTimeoutTime_HU_High_X445" SG_ 864 PotBuzzOnOffState 1000;
BA_ "GenSigTimeoutTime_HU_Mid_X445" SG_ 864 PotBuzzOnOffState 1000;
BA_ "GenSigTimeoutMsg_IVI" SG_ 864 PotBuzzOnOffState 1000;
BA_ "GenSigTimeoutTime_IVI" SG_ 864 PotBuzzOnOffState 1000;
BA_ "Remarks" SG_ 864 PotFuncState "null*";
BA_ "GenSigTimeoutTime_HU_Mid_X451" SG_ 864 PotFuncState 1000;
BA_ "GenSigTimeoutTime_HU_High_X451" SG_ 864 PotFuncState 1000;
BA_ "GenSigTimeoutTime_HU_B" SG_ 864 PotFuncState 1000;
BA_ "GenSigTimeoutTime_HU_A" SG_ 864 PotFuncState 1000;
BA_ "GenSigTimeoutMsg_HU_Mid_X451" SG_ 864 PotFuncState 1000;
BA_ "GenSigTimeoutMsg_HU_High_X451" SG_ 864 PotFuncState 1000;
BA_ "GenSigTimeoutMsg_HU_B" SG_ 864 PotFuncState 1000;
BA_ "GenSigTimeoutMsg_HU_A" SG_ 864 PotFuncState 1000;
BA_ "GenSigSendType" SG_ 864 PotFuncState 7;
BA_ "GenSigCycleTimeActive" SG_ 864 PotFuncState 200;
BA_ "GenSigCycleTime" SG_ 864 PotFuncState 200;
BA_ "GenSigTimeoutMsg_HU_High_X445" SG_ 864 PotFuncState 1000;
BA_ "GenSigTimeoutMsg_HU_Mid_X445" SG_ 864 PotFuncState 1000;
BA_ "GenSigTimeoutTime_HU_High_X445" SG_ 864 PotFuncState 1000;
BA_ "GenSigTimeoutTime_HU_Mid_X445" SG_ 864 PotFuncState 1000;
BA_ "GenSigTimeoutMsg_IVI" SG_ 864 PotFuncState 1000;
BA_ "GenSigTimeoutTime_IVI" SG_ 864 PotFuncState 1000;
BA_ "GenSigTimeoutTime_HU_Mid_X451" SG_ 864 BCmHuSunShadeStateStatus 1000;
BA_ "GenSigTimeoutTime_HU_High_X451" SG_ 864 BCmHuSunShadeStateStatus 1000;
BA_ "GenSigTimeoutTime_HU_B" SG_ 864 BCmHuSunShadeStateStatus 1000;
BA_ "GenSigTimeoutTime_HU_A" SG_ 864 BCmHuSunShadeStateStatus 1000;
BA_ "GenSigTimeoutMsg_HU_Mid_X451" SG_ 864 BCmHuSunShadeStateStatus 1000;
BA_ "GenSigTimeoutMsg_HU_High_X451" SG_ 864 BCmHuSunShadeStateStatus 1000;
BA_ "GenSigTimeoutMsg_HU_B" SG_ 864 BCmHuSunShadeStateStatus 1000;
BA_ "GenSigTimeoutMsg_HU_A" SG_ 864 BCmHuSunShadeStateStatus 1000;
BA_ "GenSigSendType" SG_ 864 BCmHuSunShadeStateStatus 7;
BA_ "GenSigCycleTimeActive" SG_ 864 BCmHuSunShadeStateStatus 200;
BA_ "GenSigCycleTime" SG_ 864 BCmHuSunShadeStateStatus 200;
BA_ "GenSigTimeoutMsg_HU_High_X445" SG_ 864 BCmHuSunShadeStateStatus 1000;
BA_ "GenSigTimeoutMsg_HU_Mid_X445" SG_ 864 BCmHuSunShadeStateStatus 1000;
BA_ "GenSigTimeoutTime_HU_High_X445" SG_ 864 BCmHuSunShadeStateStatus 1000;
BA_ "GenSigTimeoutTime_HU_Mid_X445" SG_ 864 BCmHuSunShadeStateStatus 1000;
BA_ "GenSigTimeoutMsg_IVI" SG_ 864 BCmHuSunShadeStateStatus 1000;
BA_ "GenSigTimeoutTime_IVI" SG_ 864 BCmHuSunShadeStateStatus 1000;
BA_ "GenSigTimeoutTime_HU_Mid_X451" SG_ 864 BCmHuSunShadeState 1000;
BA_ "GenSigTimeoutTime_HU_High_X451" SG_ 864 BCmHuSunShadeState 1000;
BA_ "GenSigTimeoutTime_HU_B" SG_ 864 BCmHuSunShadeState 1000;
BA_ "GenSigTimeoutTime_HU_A" SG_ 864 BCmHuSunShadeState 1000;
BA_ "GenSigTimeoutMsg_HU_Mid_X451" SG_ 864 BCmHuSunShadeState 1000;
BA_ "GenSigTimeoutMsg_HU_High_X451" SG_ 864 BCmHuSunShadeState 1000;
BA_ "GenSigTimeoutMsg_HU_B" SG_ 864 BCmHuSunShadeState 1000;
BA_ "GenSigTimeoutMsg_HU_A" SG_ 864 BCmHuSunShadeState 1000;
BA_ "GenSigSendType" SG_ 864 BCmHuSunShadeState 7;
BA_ "GenSigCycleTimeActive" SG_ 864 BCmHuSunShadeState 200;
BA_ "GenSigCycleTime" SG_ 864 BCmHuSunShadeState 200;
BA_ "GenSigTimeoutMsg_HU_High_X445" SG_ 864 BCmHuSunShadeState 1000;
BA_ "GenSigTimeoutMsg_HU_Mid_X445" SG_ 864 BCmHuSunShadeState 1000;
BA_ "GenSigTimeoutTime_HU_High_X445" SG_ 864 BCmHuSunShadeState 1000;
BA_ "GenSigTimeoutTime_HU_Mid_X445" SG_ 864 BCmHuSunShadeState 1000;
BA_ "GenSigTimeoutMsg_IVI" SG_ 864 BCmHuSunShadeState 1000;
BA_ "GenSigTimeoutTime_IVI" SG_ 864 BCmHuSunShadeState 1000;
BA_ "GenSigTimeoutTime_HU_Mid_X451" SG_ 864 BCmHuSunRoofStateStatus 1000;
BA_ "GenSigTimeoutTime_HU_High_X451" SG_ 864 BCmHuSunRoofStateStatus 1000;
BA_ "GenSigTimeoutTime_HU_B" SG_ 864 BCmHuSunRoofStateStatus 1000;
BA_ "GenSigTimeoutTime_HU_A" SG_ 864 BCmHuSunRoofStateStatus 1000;
BA_ "GenSigTimeoutMsg_HU_Mid_X451" SG_ 864 BCmHuSunRoofStateStatus 1000;
BA_ "GenSigTimeoutMsg_HU_High_X451" SG_ 864 BCmHuSunRoofStateStatus 1000;
BA_ "GenSigTimeoutMsg_HU_B" SG_ 864 BCmHuSunRoofStateStatus 1000;
BA_ "GenSigTimeoutMsg_HU_A" SG_ 864 BCmHuSunRoofStateStatus 1000;
BA_ "GenSigSendType" SG_ 864 BCmHuSunRoofStateStatus 7;
BA_ "GenSigCycleTimeActive" SG_ 864 BCmHuSunRoofStateStatus 200;
BA_ "GenSigCycleTime" SG_ 864 BCmHuSunRoofStateStatus 200;
BA_ "GenSigTimeoutMsg_HU_High_X445" SG_ 864 BCmHuSunRoofStateStatus 1000;
BA_ "GenSigTimeoutMsg_HU_Mid_X445" SG_ 864 BCmHuSunRoofStateStatus 1000;
BA_ "GenSigTimeoutTime_HU_High_X445" SG_ 864 BCmHuSunRoofStateStatus 1000;
BA_ "GenSigTimeoutTime_HU_Mid_X445" SG_ 864 BCmHuSunRoofStateStatus 1000;
BA_ "GenSigTimeoutMsg_IVI" SG_ 864 BCmHuSunRoofStateStatus 1000;
BA_ "GenSigTimeoutTime_IVI" SG_ 864 BCmHuSunRoofStateStatus 1000;
BA_ "GenSigTimeoutTime_HU_Mid_X451" SG_ 864 BCmHuSunRoofState 1000;
BA_ "GenSigTimeoutTime_HU_High_X451" SG_ 864 BCmHuSunRoofState 1000;
BA_ "GenSigTimeoutTime_HU_B" SG_ 864 BCmHuSunRoofState 1000;
BA_ "GenSigTimeoutTime_HU_A" SG_ 864 BCmHuSunRoofState 1000;
BA_ "GenSigTimeoutMsg_HU_Mid_X451" SG_ 864 BCmHuSunRoofState 1000;
BA_ "GenSigTimeoutMsg_HU_High_X451" SG_ 864 BCmHuSunRoofState 1000;
BA_ "GenSigTimeoutMsg_HU_B" SG_ 864 BCmHuSunRoofState 1000;
BA_ "GenSigTimeoutMsg_HU_A" SG_ 864 BCmHuSunRoofState 1000;
BA_ "GenSigSendType" SG_ 864 BCmHuSunRoofState 7;
BA_ "GenSigCycleTimeActive" SG_ 864 BCmHuSunRoofState 200;
BA_ "GenSigCycleTime" SG_ 864 BCmHuSunRoofState 200;
BA_ "GenSigTimeoutMsg_HU_High_X445" SG_ 864 BCmHuSunRoofState 1000;
BA_ "GenSigTimeoutMsg_HU_Mid_X445" SG_ 864 BCmHuSunRoofState 1000;
BA_ "GenSigTimeoutTime_HU_High_X445" SG_ 864 BCmHuSunRoofState 1000;
BA_ "GenSigTimeoutTime_HU_Mid_X445" SG_ 864 BCmHuSunRoofState 1000;
BA_ "GenSigTimeoutMsg_IVI" SG_ 864 BCmHuSunRoofState 1000;
BA_ "GenSigTimeoutTime_IVI" SG_ 864 BCmHuSunRoofState 1000;
BA_ "GenSigTimeoutTime_HU_Mid_X451" SG_ 864 BCmHuGotoEntryExitPosState 1000;
BA_ "GenSigTimeoutTime_HU_High_X451" SG_ 864 BCmHuGotoEntryExitPosState 1000;
BA_ "GenSigTimeoutTime_HU_B" SG_ 864 BCmHuGotoEntryExitPosState 1000;
BA_ "GenSigTimeoutTime_HU_A" SG_ 864 BCmHuGotoEntryExitPosState 1000;
BA_ "GenSigTimeoutMsg_HU_Mid_X451" SG_ 864 BCmHuGotoEntryExitPosState 1000;
BA_ "GenSigTimeoutMsg_HU_High_X451" SG_ 864 BCmHuGotoEntryExitPosState 1000;
BA_ "GenSigTimeoutMsg_HU_B" SG_ 864 BCmHuGotoEntryExitPosState 1000;
BA_ "GenSigTimeoutMsg_HU_A" SG_ 864 BCmHuGotoEntryExitPosState 1000;
BA_ "GenSigSendType" SG_ 864 BCmHuGotoEntryExitPosState 7;
BA_ "GenSigCycleTimeActive" SG_ 864 BCmHuGotoEntryExitPosState 200;
BA_ "GenSigCycleTime" SG_ 864 BCmHuGotoEntryExitPosState 200;
BA_ "GenSigTimeoutMsg_HU_High_X445" SG_ 864 BCmHuGotoEntryExitPosState 1000;
BA_ "GenSigTimeoutMsg_HU_Mid_X445" SG_ 864 BCmHuGotoEntryExitPosState 1000;
BA_ "GenSigTimeoutTime_HU_High_X445" SG_ 864 BCmHuGotoEntryExitPosState 1000;
BA_ "GenSigTimeoutTime_HU_Mid_X445" SG_ 864 BCmHuGotoEntryExitPosState 1000;
BA_ "GenSigTimeoutMsg_IVI" SG_ 864 BCmHuGotoEntryExitPosState 1000;
BA_ "GenSigTimeoutTime_IVI" SG_ 864 BCmHuGotoEntryExitPosState 1000;
BA_ "GenSigTimeoutTime_HU_Mid_X451" SG_ 864 DrvMemSeatFunState 1000;
BA_ "GenSigTimeoutTime_HU_High_X451" SG_ 864 DrvMemSeatFunState 1000;
BA_ "GenSigTimeoutTime_HU_B" SG_ 864 DrvMemSeatFunState 1000;
BA_ "GenSigTimeoutTime_HU_A" SG_ 864 DrvMemSeatFunState 1000;
BA_ "GenSigTimeoutMsg_HU_Mid_X451" SG_ 864 DrvMemSeatFunState 1000;
BA_ "GenSigTimeoutMsg_HU_High_X451" SG_ 864 DrvMemSeatFunState 1000;
BA_ "GenSigTimeoutMsg_HU_B" SG_ 864 DrvMemSeatFunState 1000;
BA_ "GenSigTimeoutMsg_HU_A" SG_ 864 DrvMemSeatFunState 1000;
BA_ "GenSigSendType" SG_ 864 DrvMemSeatFunState 7;
BA_ "GenSigCycleTimeActive" SG_ 864 DrvMemSeatFunState 200;
BA_ "GenSigCycleTime" SG_ 864 DrvMemSeatFunState 200;
BA_ "GenSigTimeoutMsg_HU_High_X445" SG_ 864 DrvMemSeatFunState 1000;
BA_ "GenSigTimeoutMsg_HU_Mid_X445" SG_ 864 DrvMemSeatFunState 1000;
BA_ "GenSigTimeoutTime_HU_High_X445" SG_ 864 DrvMemSeatFunState 1000;
BA_ "GenSigTimeoutTime_HU_Mid_X445" SG_ 864 DrvMemSeatFunState 1000;
BA_ "GenSigTimeoutMsg_IVI" SG_ 864 DrvMemSeatFunState 1000;
BA_ "GenSigTimeoutTime_IVI" SG_ 864 DrvMemSeatFunState 1000;
VAL_ 731 GyroInfoXYZStatus 3 "Signal not available" 2 "Information given is implausible" 1 "Reserved for future use " 0 "Plausible  - Information given is correct" ;
VAL_ 730 AcclrmInfoXYZStatus 3 "Signal not available" 2 "Information given is implausible" 1 "Reserved for future use " 0 "Plausible  - Information given is correct" ;
VAL_ 371 SteerAngEPAsDirGen2 1 "Steering Wheel turned in the Counter clockwise direction" 0 "Steering Wheel turned in the Clockwise direction" ;
VAL_ 280 BrakePaddlePosStatus 3 "Signal Not available" 2 "BrakePaddlePos signal Value is implausible" 1 "Reserved" 0 "Information given by BrakePaddlePos is correct and according to specification" ;
VAL_ 703 OATICSigNewStatus 3 "Signal OATSig is not available" 2 "Implausible -Information given at OATICSig is implausible" 1 "Reserved for future use" 0 "Plausible-InformationgivenatOATICSigiscorrectandaccordingtospec" ;
VAL_ 452 OwnersBirthdayResponse 1 "Message successfully displayed" 0 "No message displayed" ;
VAL_ 452 OwnersAnniversaryResponse 1 "Message successfully displayed" 0 "No message displayed" ;
VAL_ 452 CarAnniversaryResponse 1 "Message successfully displayed" 0 "No message displayed" ;
VAL_ 708 SbCurrentAudioSource 15 "Reserved" 14 "Reserved" 13 "Reserved" 12 "Reserved" 11 "Reserved" 10 "Reserved" 9 "Reserved" 8 "Reserved" 7 "Reserved" 6 "Bluetooth Audio Streaming" 5 "AUX" 4 "SD Card" 3 "USB" 2 "FM" 1 "AM" 0 "Media Off" ;
VAL_ 708 DispVariant 15 "Reserved" 14 "Reserved" 13 "Reserved" 12 "Reserved" 11 "Reserved" 10 "Gen3 High+ 12.3 Inch  Infotainment + 10.25 Inch IC" 9 "Gen3 High 10.25 Inch Infotainment + 10.25 Inch IC" 8 "Gen3 Mid+ 10.25 Inch" 7 "Gen3 Mid 10.25 Inch" 6 "X451 7 Inch TFT Display" 5 "X451 3.5 Inch Monochrome Display" 4 "Q5 8.8 Inch TFT Display" 3 "Q5 7 Inch TFT Display" 2 "Q5 5.5 Inch TFT Display" 1 "X 104 TFT Display" 0 "X 104 Monochrome Display" ;
VAL_ 708 SbPowerModeConfig 1 "PEPS Type" 0 "Ign Lock Type" ;
VAL_ 708 SbCurrentPowerMode 7 "Reserved" 6 "Reserved" 5 "Crank" 4 "Static" 3 "Standby" 2 "S2R" 1 "SbActive Mode" 0 "SbMediaOff Mode" ;
VAL_ 708 BpVariant 15 "Reserved" 14 "Reserved" 13 "Reserved" 12 "Reserved" 11 "Reserved" 10 "Reserved" 9 "Reserved" 8 "Reserved" 7 "Reserved" 6 "Reserved" 5 "Reserved" 4 "Reserved" 3 "Reserved" 2 "X451  ButtonPanel" 1 "Q5  ButtonPanel" 0 "X 104 Button Panel" ;
VAL_ 708 DispCurrentPowerMode 7 "Reserved" 6 "Reserved" 5 "Reserved" 4 "Reserved" 3 "Reserved" 2 "DispActive Mode" 1 "DispStandBy Mode" 0 "DisplSwitchOff Mode" ;
VAL_ 708 BpCurrentPowerMode 7 "Reserved" 6 "Reserved" 5 "Reserved" 4 "Reserved" 3 "Reserved" 2 "Reserved" 1 "BpActive Mode" 0 "BpSwitchOff Mode" ;
VAL_ 708 BpPresence 3 "Reserved" 2 "Reserved" 1 "Present" 0 "Absence" ;
VAL_ 708 DispPresence 3 "Reserved" 2 "Reserved" 1 "Present" 0 "Absence" ;
VAL_ 1109 AvasOnOffSettingState 1 "On" 0 "Off" ;
VAL_ 1109 AvasOnOffSettingPresence 3 "Reserved" 2 "Not Present" 1 "Present" 0 "Not Used" ;
VAL_ 1126 AvasOnOffSettingPresenceAck 3 "Reserved" 2 "Not Present" 1 "Present" 0 "Not Used" ;
VAL_ 1126 AvasOnOffSettinStateAck 1 "On" 0 "Off" ;
VAL_ 1126 AvasOnOffSettingChangeReq 1 "On" 0 "Off" ;
VAL_ 945 VehicleKeyType 31 "Reserved (5 to 31)" 5 "Reserved" 4 "MQ_PEPS Key_With SASS" 3 "APTIV_PEPS Key" 2 "MQ_PEPS Key" 1 "Hella_Remote Key(3 Button RKE)" 0 "NO_Key(By Defult)_Or_Only with Mech Key" ;
VAL_ 535 CplHuSclSettingUpdateAck 3 "Reserved" 2 "SCL Settings Update Success	

" 1 "SCL Settings Update failed	

" 0 "No SCL settings update" ;
VAL_ 754 CplPresence 1 "Reserved" 0 "CPL is present" ;
VAL_ 754 CplHuSclTimerConfigState 3 "Reserved" 2 "SCL Timer is 60 sec" 1 "SCL Timer is 30 sec" 0 "SCL Timer is 10 sec" ;
VAL_ 754 CplHuSclPresence 1 "SCL feature is present." 0 "SCL feature is absent." ;
VAL_ 754 CplHuSclOnOffConfigState 1 "SCL is ON" 0 "SCL is OFF" ;
VAL_ 756 VCuHuChargeLimitPresence 3 "AC and DC" 2 "only DC" 1 "only AC" 0 "absent" ;
VAL_ 756 HVChargerConnectedStatus_VCAN 3 "Reserved" 2 "Information given is implausible due to a detected failure" 1 "Reserved" 0 "Information given is correct and according to specification" ;
VAL_ 756 HVChargerConnected_VCAN 3 "Reserved for future use" 2 "Charger Connection lamp Flash" 1 "Charger Connection lamp ON" 0 "Charger Connection lamp is OFF" ;
VAL_ 756 VCUSlowChrgshtdnStatus_VCAN 3 "Reserved for future use" 2 "Signal is implausible" 1 "Reserved for future use" 0 "Signal is correct" ;
VAL_ 756 VCUSlowChrgshtdn_VCAN 7 "Reserved" 6 "Reserved" 5 "Reserved" 4 "Hardware Fault" 3 "Communication failure" 2 "Vehicle Side error" 1 "Charging station Side error" 0 "No Error" ;
VAL_ 756 VCUFastChrgshtdnStatus_VCAN 3 "Reserved for future use" 2 "Signal is implausible" 1 "Reserved for future use" 0 "Signal is correct" ;
VAL_ 756 VCUFastChrgshtdn_VCAN 7 "Reserved" 6 "Reserved" 5 "Reserved" 4 "Hardware Fault" 3 "Communication failure" 2 "Vehicle Side error" 1 "Charging station Side error" 0 "No Error" ;
VAL_ 756 VCUChargingRateStatus_VCAN 3 "Reserved for future use" 2 "Signal is implausible" 1 "Reserved for future use." 0 "Signal is correct" ;
VAL_ 753 HudPresence 3 "Reserved" 2 "Reserved" 1 "AR_HUD" 0 "C_HUD" ;
VAL_ 753 HudFeaturePresence 1 "HuD feature  present" 0 "HUD feature not present" ;
VAL_ 529 VCuHuChargeLimitValueAck 3 "DC Charge limit Set success " 2 "SC Charge limit Set success " 1 "failure" 0 "don’t care" ;
VAL_ 529 DischargingSOCLimitAck 3 "Reserved for Future Use" 2 "SOC limit acknowledged" 1 "SOC limit not acknowledged" 0 "Don't Care" ;
VAL_ 528 DischargeSOClimitcmd 3 "Reserved for Future Use" 2 "Reset Discharge limit" 1 "Set Discharge limit" 0 "No Discharge limit" ;
VAL_ 528 AVAsFeaturePreviewReq 31 "Reserved" 30 "Reserved" 29 "Reserved" 28 "Reserved" 27 "Reserved" 26 "Reserved" 25 "Reserved" 24 "Reserved" 23 "Reserved" 22 "Reserved" 21 "Reserved" 20 "Reserved" 19 "Reserved" 18 "Reserved" 17 "Reserved" 16 "Reserved" 15 "Reserved" 14 "Reserved" 13 "Reserved" 12 "Reserved" 11 "Reserved" 10 "Reserved" 9 "Reserved" 8 "Reserved" 7 "Reserved" 6 "Preview V2X Sound" 5 "Preview Sound Signature 3" 4 "Preview Sound Signature 2" 3 "Preview Sound Signature 1" 2 "Preview crank sound" 1 "Preview charging sound" 0 "Preview Lock Unlock Sound" ;
VAL_ 528 SoundSigSettingStateAck 31 "Reserved" 30 "Reserved" 29 "Reserved" 28 "Reserved" 27 "Reserved" 26 "Reserved" 25 "Reserved" 24 "Reserved" 23 "Reserved" 22 "Reserved" 21 "Reserved" 20 "Reserved" 19 "Reserved" 18 "Reserved" 17 "Reserved" 16 "Reserved" 15 "Reserved" 14 "Reserved" 13 "Reserved" 12 "Reserved" 11 "Reserved" 10 "Reserved" 9 "Reserved" 8 "Reserved" 7 "Reserved" 6 "Reserved" 5 "Reserved" 4 "Reserved" 3 "Reserved" 2 "Sound Signature 3" 1 "Sound Signature 2" 0 "Sound Signature 1" ;
VAL_ 528 SoundSigSettingPresenceAck 31 "Reserved" 30 "Reserved" 29 "Reserved" 28 "Reserved" 27 "Reserved" 26 "Reserved" 25 "Reserved" 24 "Reserved" 23 "Reserved" 22 "Reserved" 21 "Reserved" 20 "Reserved" 19 "Reserved" 18 "Reserved" 17 "Reserved" 16 "Reserved" 15 "Reserved" 14 "Reserved" 13 "Reserved" 12 "Reserved" 11 "Reserved" 10 "Reserved" 9 "Reserved" 8 "Reserved" 7 "Reserved" 6 "Reserved" 5 "Reserved" 4 "Reserved" 3 "Three Sound signatures Present" 2 "Two Sound signatures Present" 1 "Not present" 0 "Not used" ;
VAL_ 528 ChargingSettingChangeReq 1 "ON" 0 "OFF" ;
VAL_ 528 V2XSoundSettingStateAck 1 "ON" 0 "OFF" ;
VAL_ 528 V2XSettingChangeReq 1 "ON" 0 "OFF" ;
VAL_ 528 V2XEventPresenceAck 3 "Reserved" 2 "Not present" 1 "Present" 0 "Not used" ;
VAL_ 528 SndSyncDriveModeChangeReq 1 "sound sync with drive mode Off" 0 "sound sync with drive mode ON" ;
VAL_ 528 SoundSigSettingChangeReq 31 "Reserved" 30 "Reserved" 29 "Reserved" 28 "Reserved" 27 "Reserved" 26 "Reserved" 25 "Reserved" 24 "Reserved" 23 "Reserved" 22 "Reserved" 21 "Reserved" 20 "Reserved" 19 "Reserved" 18 "Reserved" 17 "Reserved" 16 "Reserved" 15 "Reserved" 14 "Reserved" 13 "Reserved" 12 "Reserved" 11 "Reserved" 10 "Reserved" 9 "Reserved" 8 "Reserved" 7 "Reserved" 6 "Reserved" 5 "Reserved" 4 "Reserved" 3 "Reserved" 2 "Sound Signature 3" 1 "Sound Signature 2" 0 "Sound Signature 1" ;
VAL_ 528 CrankSettingChangeReq 1 "ON" 0 "OFF" ;
VAL_ 528 LockUnlockSettingChangeReq 1 "ON" 0 "OFF" ;
VAL_ 528 ActiveExtSettingChangeReq 1 "ON" 0 "OFF" ;
VAL_ 528 HuAVAsReqType 15 "Reserved" 14 "Reserved" 13 "Reserved" 12 "Reserved" 11 "Reserved" 10 "Reserved" 9 "Reserved" 8 "Reserved" 7 "Reserved" 6 "Reserved" 5 "Stop User Preview" 4 "Play User Preview" 3 "User Settings Reset" 2 "User Settings Update" 1 "Config Query" 0 "Config Ack" ;
VAL_ 528 SndSyncDriveModePresenceAck 3 "Reserved" 2 "Not Present" 1 "Present" 0 "Not Used" ;
VAL_ 528 SndSyncDriveModeSettingStateAck 1 "ON" 0 "OFF" ;
VAL_ 528 CrankSoundSettingStateAck 1 "ON" 0 "OFF" ;
VAL_ 528 CrankEventPresenceAck 3 "Reserved" 2 "Not Present" 1 "Present" 0 "Not Used" ;
VAL_ 528 ChargingSoundSettingStateAck 1 "ON" 0 "OFF" ;
VAL_ 528 ChargingEventPresenceAck 3 "Reserved" 2 "Not present" 1 "Present" 0 "Not used" ;
VAL_ 528 LockUnlockSettingStateAck 1 "ON" 0 "OFF" ;
VAL_ 528 LockUnlockEventPresenceAck 3 "Reserved" 2 "Not Present" 1 "Present" 0 "Not Used" ;
VAL_ 528 ActiveExtSoundSettingStateAck 1 "ON" 0 "OFF" ;
VAL_ 528 ActiveExtSoundPresenceAck 3 "Reserved" 2 "Not Present" 1 "Present" 0 "Not Used" ;
VAL_ 527 V2XSoundSettingState 1 "ON" 0 "OFF" ;
VAL_ 527 V2XEventPresence 3 "Reserved" 2 "Not present" 1 "Present" 0 "Not used" ;
VAL_ 527 SoundSignSettingState 31 "Reserved" 30 "Reserved" 29 "Reserved" 28 "Reserved" 27 "Reserved" 26 "Reserved" 25 "Reserved" 24 "Reserved" 23 "Reserved" 22 "Reserved" 21 "Reserved" 20 "Reserved" 19 "Reserved" 18 "Reserved" 17 "Reserved" 16 "Reserved" 15 "Reserved" 14 "Reserved" 13 "Reserved" 12 "Reserved" 11 "Reserved" 10 "Reserved" 9 "Reserved" 8 "Reserved" 7 "Reserved" 6 "Reserved" 5 "Reserved" 4 "Reserved" 3 "Reserved" 2 "Sound Signature 3" 1 "Sound Signature 2" 0 "Sound Signature 1" ;
VAL_ 527 SoundSignSettingPresence 31 "Reserved" 30 "Reserved" 29 "Reserved" 28 "Reserved" 27 "Reserved" 26 "Reserved" 25 "Reserved" 24 "Reserved" 23 "Reserved" 22 "Reserved" 21 "Reserved" 20 "Reserved" 19 "Reserved" 18 "Reserved" 17 "Reserved" 16 "Reserved" 15 "Reserved" 14 "Reserved" 13 "Reserved" 12 "Reserved" 11 "Reserved" 10 "Reserved" 9 "Reserved" 8 "Reserved" 7 "Reserved" 6 "Reserved" 5 "Reserved" 4 "Reserved" 3 "Three Sound signatures Present" 2 "Two Sound signatures Present" 1 "Not present" 0 "Not used" ;
VAL_ 527 SndSyncDriveModeSettingState 1 "ON" 0 "OFF" ;
VAL_ 527 SndSyncDriveModePresence 3 "Reserved" 2 "Not Present" 1 "Present" 0 "Not Used" ;
VAL_ 527 LockUnlockSettingState 1 "ON" 0 "OFF" ;
VAL_ 527 LockUnlockEventPresence 3 "Reserved" 2 "Not Present" 1 "Present" 0 "Not Used" ;
VAL_ 527 CrankSoundSettingState 1 "ON" 0 "OFF" ;
VAL_ 527 CrankEventPresence 3 "Reserved" 2 "Not Present" 1 "Present" 0 "Not Used" ;
VAL_ 527 ChargingSoundSettingState 1 "ON" 0 "OFF" ;
VAL_ 527 ChargingEventPresence 3 "Reserved" 2 "Not present" 1 "Present" 0 "Not used" ;
VAL_ 527 AVAsPreviewStateapplicability 31 "Reserved" 30 "Reserved" 29 "Reserved" 28 "Reserved" 27 "Reserved" 26 "Reserved" 25 "Reserved" 24 "Reserved" 23 "Reserved" 22 "Reserved" 21 "Reserved" 20 "Reserved" 19 "Reserved" 18 "Reserved" 17 "Reserved" 16 "Reserved" 15 "Reserved" 14 "Reserved" 13 "Reserved" 12 "Reserved" 11 "Reserved" 10 "Reserved" 9 "Reserved" 8 "Reserved" 7 "Reserved" 6 "Preview V2X Sound" 5 "Preview Sound Signature 3" 4 "Preview Sound Signature 2" 3 "Preview Sound Signature 1" 2 "Preview crank sound" 1 "Preview charging sound" 0 "Preview Lock Unlock Sound" ;
VAL_ 527 AVAsPreviewState 3 "Reserved" 2 "Reserved" 1 "No preview" 0 "Playing preview" ;
VAL_ 527 AVAsPreviewPresence 3 "Reserved" 2 "Not present" 1 "Present" 0 "Not used" ;
VAL_ 527 ActiveExtSoundSettingState 1 "ON" 0 "OFF" ;
VAL_ 527 ActiveExtSoundPresence 3 "Reserved" 2 "Not Present" 1 "Present" 0 "Not Used" ;
VAL_ 751 AvasPresence 1 "AVAS present" 0 "AVAS Not Present" ;
VAL_ 751 AVAsMalFunction 3 "Reserved" 2 "Reserved" 1 "Malfunction" 0 "No malfunction" ;
VAL_ 749 LdwWarningSettingPresence 1 "Present" 0 "Not Present" ;
VAL_ 749 LcsOnOffState 3 "Reserved		

" 2 "ON		

" 1 "OFF		

" 0 "Not Present		

" ;
VAL_ 749 AsaOnOffState 3 "Reserved		

" 2 "ON		

" 1 "OFF		

" 0 "Not Present		

" ;
VAL_ 749 IsaOnOffState 3 "ON (Intelligent Mode)		

" 2 "ON (Manual Mode)		

" 1 "OFF		

" 0 "Not Present		

" ;
VAL_ 864 MemoryOrvmFunState 1 "Memory ORVM function Present" 0 "Memory ORVM function Absent" ;
VAL_ 864 BcmHuOrvmTiltReversePosState 1 "ORVM Tilt in Reverse function ON State" 0 "ORVM Tilt in Reverse function OFF State" ;
VAL_ 864 BcmHuMrrAutoUnfoldFuncState 1 "ORVM AutoUnfold Function Present" 0 "ORVM Auto Unfold Function Absent" ;
VAL_ 864 BcmHuMrrAutoUnfoldSelState 1 "ORVM Auto Unfold feature ON" 0 "ORVM Auto Unfold feature OFF" ;
VAL_ 864 PotHeightAdjState 7 "Reserve" 6 "100% open (Default =  Fully Open Soft Stop)" 5 "90% open" 4 "80% open" 3 "70% open" 2 "60% open" 1 "50% open" 0 "No User Height Set" ;
VAL_ 864 PotSwRkeOnOffState 1 "Enable Power Tailgate by RKE sw feature" 0 "Disable Power Tailgate by RKE sw feature" ;
VAL_ 864 PotGestOnOffState 1 "Enable Power Tailgate Gesture feature" 0 "Disable Power Tailgate Gesture feature" ;
VAL_ 864 PotBuzzOnOffState 1 "POT buzzer function ON" 0 "POT buzzer function OFF" ;
VAL_ 864 PotFuncState 1 "POT function Present" 0 "POT function Absent" ;
VAL_ 864 BCmHuSunShadeStateStatus 3 "Signal Not Available(SNA)" 2 "Implausible" 1 "Reserved" 0 "Plausible" ;
VAL_ 864 BCmHuSunShadeState 7 "Reserved Bit" 6 "Reserved Bit" 5 "Reserved Bit" 4 "SunShade Function Not Available" 3 "SunShade Closing (Ongoing Closing transition)" 2 "SunShade opening (Ongoing Opening transition)" 1 "SunShade opened" 0 "SunShade Fully Closed" ;
VAL_ 864 BCmHuSunRoofStateStatus 3 "Signal Not Available(SNA)" 2 "Implausible" 1 "Reserved" 0 "Plausible" ;
VAL_ 864 BCmHuSunRoofState 7 "Reserved Bit" 6 "Reserved Bit" 5 "Reserved Bit" 4 "SunRoof Function Not Available" 3 "Sunroof Closing (Ongoing Closing transition)" 2 "Sunroof opening (Ongoing Opening transition)" 1 "Sunroof opened" 0 "Sunroof Fully Closed" ;
VAL_ 864 BCmHuGotoEntryExitPosState 1 "Easy Entry Exit function ON" 0 "Easy Entry Exit function OFF" ;
VAL_ 864 DrvMemSeatFunState 1 "Driver Memory Seat function Present" 0 "Driver Memory Seat function Absent" ;
